VERSION ""

NS_ :

BS_:

BU_: PowertrainControlModule AtmosphericSensor SafetyRestraintSystem2 Aftertreatment_2_GasOutlet Aftertreatment_2_GasIntake DieselParticulateFilterControl Turbocharger SafetyRestraintSystem1 CabDisplay2 Aftertreatment_1_GasOutlet Aftertreatment_1_GasIntake OnBoardDataLogger OffBoardDiagnosticTool2 OffBoardDiagnosticTool1 FileServer ParkingBrakeController SeatController2 FanDriveController SteeringColumnUnit CommunicationUnitRadio CommunicationUnitSatellite CommunicationUnitCellular PropulsionBatteryCharger ChassisController2 ChassisController1 EngineValveControl AuxiliaryHeater2 AuxiliaryHeater1 ClutchUnit RampControl InformationSystem1 SuspensionSystemController2 OilSensor VehicleDynamicStability ExhaustEmissionController TransmissionDisplay2 TransmissionDisplay1 ClimateControl2 WaterPumpController RearAxleSteeringController LightingOperatorControl SeatController1 IgnitionController2 IgnitionController1 TirePressureController CabController2 CabController1 PneumaticSystemController SuspensionSystemController1 HydraulicPumpController EnduranceBrakingSystem RetarderExhaustEngine2 OnBoardDiagnosticUnit HeadwayController RetarderExhaustEngine1 CabDisplay1 ManagementComputer VirtualTerminal OffVehicleGateway PowerTakeOffFront HitchControl AuxiliaryValveControl BodyController TractorTrailerBridge1 StarterSystem ElectricalSystem VehicleSecurity VehicleNavigation AerodynamicControl ElectricalChargingSystem ClimateControl1 TripRecorder InstrumentCluster SuspensionDriveAxle2 SuspensionDriveAxle1 SuspensionSteerAxle SteeringController FuelSystem CruiseControl RetarderDriveline RetarderEngine BrakesDriveAxle2 BrakesDriveAxle1 BrakesSystemController BrakesSteerAxle AxleDrive2 AxleDrive1 AxleSteering PowerTakeOff ShiftConsoleSecondary ShiftConsolePrimary Transmission2 Transmission1 Engine2 Engine1

BO_ 2566642942 DC4: 8 Vector__XXX
 SG_ EnableStatusOfDoor30 : 58|2@1+ (1,0) [0|3] "" Vector__XXX
 SG_ OpenStatusOfDoor30 : 56|2@1+ (1,0) [0|3] "" Vector__XXX
 SG_ LockStatusOfDoor30 : 54|2@1+ (1,0) [0|3] "" Vector__XXX
 SG_ EnableStatusOfDoor29 : 52|2@1+ (1,0) [0|3] "" Vector__XXX
 SG_ OpenStatusOfDoor29 : 50|2@1+ (1,0) [0|3] "" Vector__XXX
 SG_ LockStatusOfDoor29 : 48|2@1+ (1,0) [0|3] "" Vector__XXX
 SG_ EnableStatusOfDoor28 : 46|2@1+ (1,0) [0|3] "" Vector__XXX
 SG_ OpenStatusOfDoor28 : 44|2@1+ (1,0) [0|3] "" Vector__XXX
 SG_ LockStatusOfDoor28 : 42|2@1+ (1,0) [0|3] "" Vector__XXX
 SG_ EnableStatusOfDoor27 : 40|2@1+ (1,0) [0|3] "" Vector__XXX
 SG_ OpenStatusOfDoor27 : 38|2@1+ (1,0) [0|3] "" Vector__XXX
 SG_ LockStatusOfDoor27 : 36|2@1+ (1,0) [0|3] "" Vector__XXX
 SG_ EnableStatusOfDoor26 : 34|2@1+ (1,0) [0|3] "" Vector__XXX
 SG_ OpenStatusOfDoor26 : 32|2@1+ (1,0) [0|3] "" Vector__XXX
 SG_ LockStatusOfDoor26 : 30|2@1+ (1,0) [0|3] "" Vector__XXX
 SG_ EnableStatusOfDoor25 : 28|2@1+ (1,0) [0|3] "" Vector__XXX
 SG_ OpenStatusOfDoor25 : 26|2@1+ (1,0) [0|3] "" Vector__XXX
 SG_ LockStatusOfDoor25 : 24|2@1+ (1,0) [0|3] "" Vector__XXX
 SG_ EnableStatusOfDoor24 : 22|2@1+ (1,0) [0|3] "" Vector__XXX
 SG_ OpenStatusOfDoor24 : 20|2@1+ (1,0) [0|3] "" Vector__XXX
 SG_ LockStatusOfDoor24 : 18|2@1+ (1,0) [0|3] "" Vector__XXX
 SG_ EnableStatusOfDoor23 : 16|2@1+ (1,0) [0|3] "" Vector__XXX
 SG_ OpenStatusOfDoor23 : 14|2@1+ (1,0) [0|3] "" Vector__XXX
 SG_ LockStatusOfDoor23 : 12|2@1+ (1,0) [0|3] "" Vector__XXX
 SG_ EnableStatusOfDoor22 : 10|2@1+ (1,0) [0|3] "" Vector__XXX
 SG_ OpenStatusOfDoor22 : 8|2@1+ (1,0) [0|3] "" Vector__XXX
 SG_ LockStatusOfDoor22 : 6|2@1+ (1,0) [0|3] "" Vector__XXX
 SG_ EnableStatusOfDoor21 : 4|2@1+ (1,0) [0|3] "" Vector__XXX
 SG_ OpenStatusOfDoor21 : 2|2@1+ (1,0) [0|3] "" Vector__XXX
 SG_ LockStatusOfDoor21 : 0|2@1+ (1,0) [0|3] "" Vector__XXX

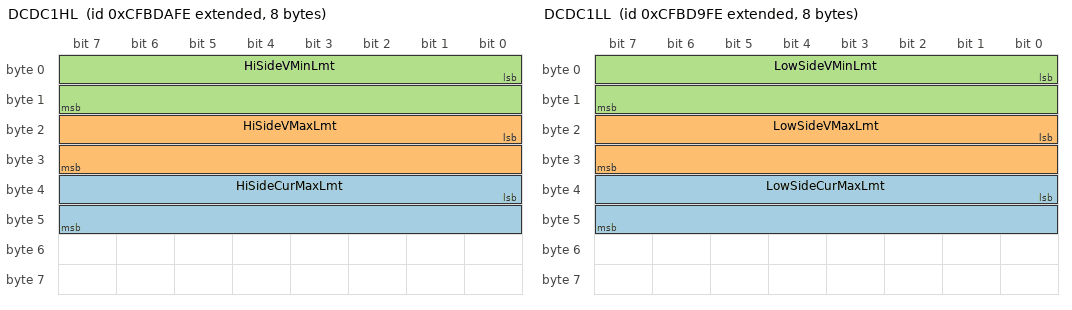
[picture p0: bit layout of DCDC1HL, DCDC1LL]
BO_ 2365315838 DCDC1HL: 8 Vector__XXX
 SG_ HiSideCurMaxLmt : 32|16@1+ (0.05,0) [0|3212.75] "A" Vector__XXX
 SG_ HiSideVMaxLmt : 16|16@1+ (0.05,0) [0|3212.75] "V" Vector__XXX
 SG_ HiSideVMinLmt : 0|16@1+ (0.05,0) [0|3212.75] "V" Vector__XXX

BO_ 2365315582 DCDC1LL: 8 Vector__XXX
 SG_ LowSideCurMaxLmt : 32|16@1+ (0.05,0) [0|3212.75] "A" Vector__XXX
 SG_ LowSideVMaxLmt : 16|16@1+ (0.01,0) [0|642.55] "V" Vector__XXX
 SG_ LowSideVMinLmt : 0|16@1+ (0.01,0) [0|642.55] "V" Vector__XXX

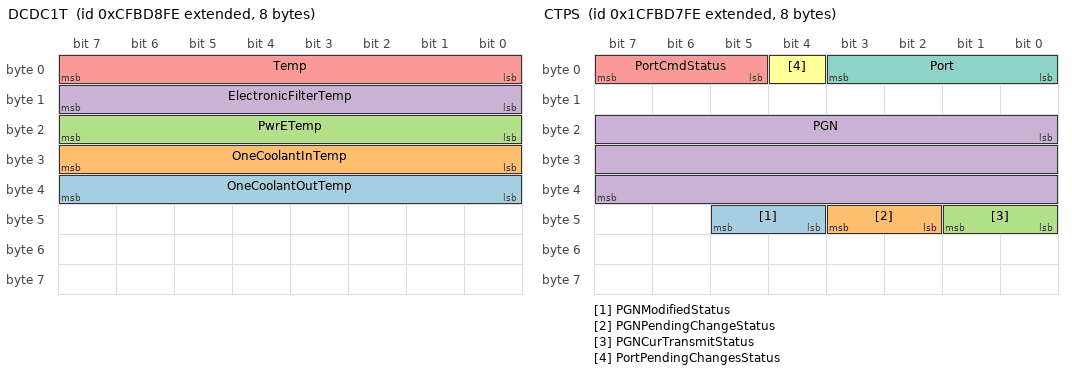
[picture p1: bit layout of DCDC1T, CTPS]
BO_ 2365315326 DCDC1T: 8 Vector__XXX
 SG_ OneCoolantOutTemp : 32|8@1+ (1,-40) [-40|210] "°C" Vector__XXX
 SG_ OneCoolantInTemp : 24|8@1+ (1,-40) [-40|210] "°C" Vector__XXX
 SG_ PwrETemp : 16|8@1+ (1,-40) [-40|210] "°C" Vector__XXX
 SG_ ElectronicFilterTemp : 8|8@1+ (1,-40) [-40|210] "°C" Vector__XXX
 SG_ Temp : 0|8@1+ (1,-40) [-40|210] "°C" Vector__XXX

BO_ 2633750526 CTPS: 8 Vector__XXX
 SG_ PGNModifiedStatus : 44|2@1+ (1,0) [0|3] "" Vector__XXX
 SG_ PGNPendingChangeStatus : 42|2@1+ (1,0) [0|3] "" Vector__XXX
 SG_ PGNCurTransmitStatus : 40|2@1+ (1,0) [0|3] "" Vector__XXX
 SG_ PGN : 16|24@1+ (1,0) [0|16777215] "" Vector__XXX
 SG_ PortCmdStatus : 5|3@1+ (1,0) [0|7] "" Vector__XXX
 SG_ PortPendingChangesStatus : 4|1@1+ (1,0) [0|1] "" Vector__XXX
 SG_ Port : 0|4@1+ (1,0) [0|15] "" Vector__XXX

BO_ 2566641406 EEC21: 8 Vector__XXX
 SG_ ExhManifoldPress2 : 16|16@1+ (0.1,0) [0|6425.5] "kPa" Vector__XXX
 SG_ ExhManifoldPress1 : 0|16@1+ (0.1,0) [0|6425.5] "kPa" Vector__XXX

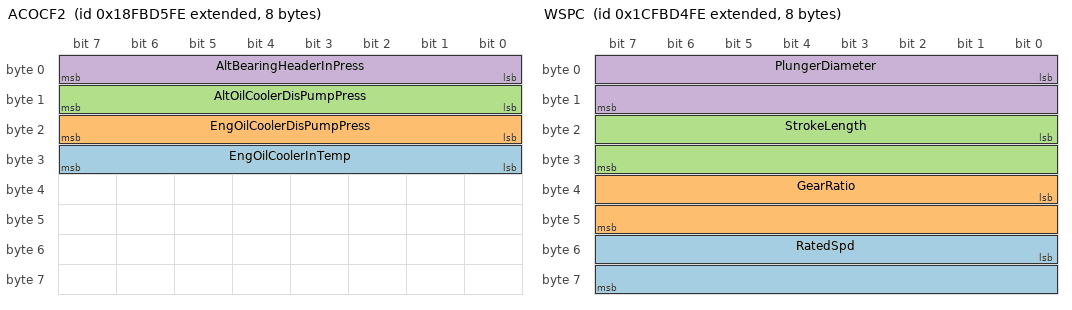
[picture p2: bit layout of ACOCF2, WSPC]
BO_ 2566641150 ACOCF2: 8 Vector__XXX
 SG_ EngOilCoolerInTemp : 24|8@1+ (1,-40) [-40|210] "°C" Vector__XXX
 SG_ EngOilCoolerDisPumpPress : 16|8@1+ (2,0) [0|500] "kPa" Vector__XXX
 SG_ AltOilCoolerDisPumpPress : 8|8@1+ (2,0) [0|500] "kPa" Vector__XXX
 SG_ AltBearingHeaderInPress : 0|8@1+ (2,0) [0|500] "kPa" Vector__XXX

BO_ 2633749758 WSPC: 8 Vector__XXX
 SG_ RatedSpd : 48|16@1+ (0.125,0) [0|8031.875] "rpm" Vector__XXX
 SG_ GearRatio : 32|16@1+ (0.001,0) [0|64.255] "" Vector__XXX
 SG_ StrokeLength : 16|16@1+ (1,0) [0|64255] "mm" Vector__XXX
 SG_ PlungerDiameter : 0|16@1+ (1,0) [0|64255] "mm" Vector__XXX

BO_ 2633749502 WSPT: 16 Vector__XXX
 SG_ CycleCount : 96|32@1+ (1,0) [0|4211081215] "" Vector__XXX
 SG_ WorkingHours : 64|32@1+ (1,0) [0|4211081215] "s" Vector__XXX
 SG_ PwrEndWorkingHours : 32|32@1+ (1,0) [0|4211081215] "s" Vector__XXX
 SG_ FluidEndWorkingHours : 0|32@1+ (1,0) [0|4211081215] "s" Vector__XXX

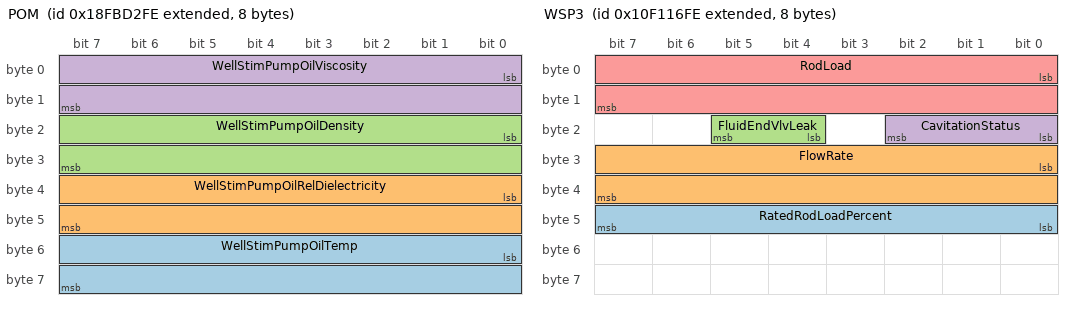
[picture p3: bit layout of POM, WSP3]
BO_ 2566640382 POM: 8 Vector__XXX
 SG_ WellStimPumpOilTemp : 48|16@1+ (0.03125,-273) [-273|1734.96875] "°C" Vector__XXX
 SG_ WellStimPumpOilRelDielectricity : 32|16@1+ (0.0001220703125,0) [0|7.8436279296875] "" Vector__XXX
 SG_ WellStimPumpOilDensity : 16|16@1+ (3.052E-005,0) [0|1.9610626] "g/cc" Vector__XXX
 SG_ WellStimPumpOilViscosity : 0|16@1+ (0.015625,0) [0|1003.984375] "cP" Vector__XXX

BO_ 2431719166 WSP3: 8 Vector__XXX
 SG_ RatedRodLoadPercent : 40|8@1+ (0.5,0) [0|125] "%" Vector__XXX
 SG_ FlowRate : 24|16@1+ (0.5,0) [0|32127.5] "l/min" Vector__XXX
 SG_ FluidEndVlvLeak : 20|2@1+ (1,0) [0|3] "" Vector__XXX
 SG_ CavitationStatus : 16|3@1+ (1,0) [0|7] "" Vector__XXX
 SG_ RodLoad : 0|16@1+ (5,0) [0|321275] "kN" Vector__XXX

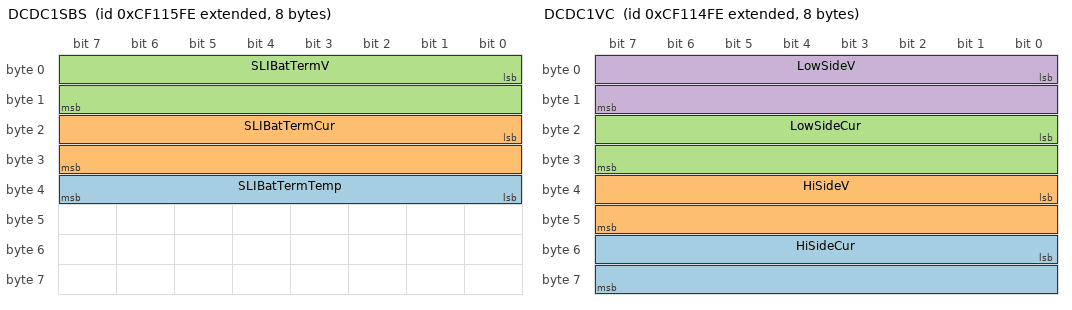
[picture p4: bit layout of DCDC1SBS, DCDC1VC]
BO_ 2364610046 DCDC1SBS: 8 Vector__XXX
 SG_ SLIBatTermTemp : 32|8@1+ (1,-40) [-40|210] "°C" Vector__XXX
 SG_ SLIBatTermCur : 16|16@1+ (0.1,-3212.7) [-3212.7|3212.8] "A" Vector__XXX
 SG_ SLIBatTermV : 0|16@1+ (0.01,0) [0|642.55] "V" Vector__XXX

BO_ 2364609790 DCDC1VC: 8 Vector__XXX
 SG_ HiSideCur : 48|16@1+ (0.1,-3212.7) [-3212.7|3212.8] "A" Vector__XXX
 SG_ HiSideV : 32|16@1+ (0.05,0) [0|3212.75] "V" Vector__XXX
 SG_ LowSideCur : 16|16@1+ (0.1,-3212.7) [-3212.7|3212.8] "A" Vector__XXX
 SG_ LowSideV : 0|16@1+ (0.01,0) [0|642.55] "V" Vector__XXX

BO_ 2364609534 DCDC1OS: 8 Vector__XXX
 SG_ DCDC1OperatingStatusCRC : 56|8@1+ (1,0) [0|255] "" Vector__XXX
 SG_ DCDC1OperatingStatusCounter : 52|4@1+ (1,0) [0|15] "" Vector__XXX
 SG_ PLDueToUndefinedReason : 32|2@1+ (1,0) [0|3] "" Vector__XXX
 SG_ PLDueToSLIBatTermTemp : 30|2@1+ (1,0) [0|3] "" Vector__XXX
 SG_ PLDueToSLIBatTermCur : 28|2@1+ (1,0) [0|3] "" Vector__XXX
 SG_ PLDueToSLIBatTermV : 26|2@1+ (1,0) [0|3] "" Vector__XXX
 SG_ PLDueToPwrETemp : 24|2@1+ (1,0) [0|3] "" Vector__XXX
 SG_ PLDueToElectronicFilterTemp : 22|2@1+ (1,0) [0|3] "" Vector__XXX
 SG_ PLDueToCtrlTemp : 20|2@1+ (1,0) [0|3] "" Vector__XXX
 SG_ PLDueToLowSideVMax : 18|2@1+ (1,0) [0|3] "" Vector__XXX
 SG_ PLDueToLowSideVMin : 16|2@1+ (1,0) [0|3] "" Vector__XXX
 SG_ PLDueToHiSideVMax : 14|2@1+ (1,0) [0|3] "" Vector__XXX
 SG_ PLDueToHiSideVMin : 12|2@1+ (1,0) [0|3] "" Vector__XXX
 SG_ PLDueToLowSideCur : 10|2@1+ (1,0) [0|3] "" Vector__XXX
 SG_ PLDueToHiSideCur : 8|2@1+ (1,0) [0|3] "" Vector__XXX
 SG_ LoadshedReq : 6|2@1+ (1,0) [0|3] "" Vector__XXX
 SG_ HVILStatus : 4|2@1+ (1,0) [0|3] "" Vector__XXX
 SG_ OperationalStatus : 0|4@1+ (1,0) [0|15] "" Vector__XXX

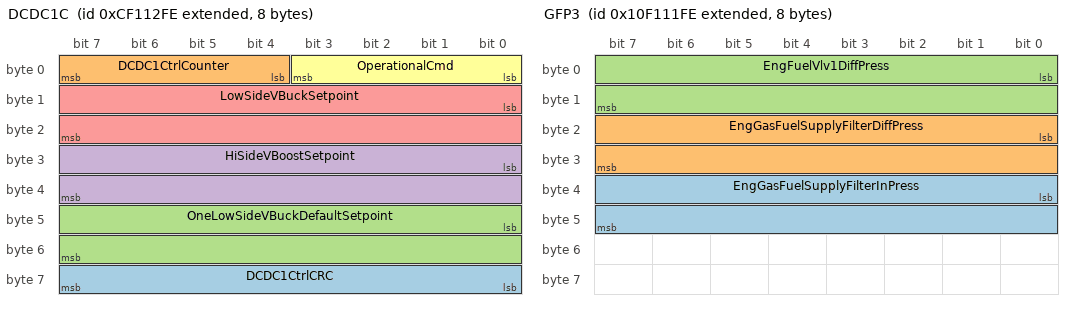
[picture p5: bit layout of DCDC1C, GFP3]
BO_ 2364609278 DCDC1C: 8 Vector__XXX
 SG_ DCDC1CtrlCRC : 56|8@1+ (1,0) [0|255] "" Vector__XXX
 SG_ DCDC1CtrlCounter : 4|4@1+ (1,0) [0|15] "" Vector__XXX
 SG_ OneLowSideVBuckDefaultSetpoint : 40|16@1+ (0.01,0) [0|642.55] "V" Vector__XXX
 SG_ HiSideVBoostSetpoint : 24|16@1+ (0.05,0) [0|3212.75] "V" Vector__XXX
 SG_ LowSideVBuckSetpoint : 8|16@1+ (0.01,0) [0|642.55] "V" Vector__XXX
 SG_ OperationalCmd : 0|4@1+ (1,0) [0|15] "" Vector__XXX

BO_ 2431717886 GFP3: 8 Vector__XXX
 SG_ EngGasFuelSupplyFilterInPress : 32|16@1+ (0.5,0) [0|32127.5] "kPa" Vector__XXX
 SG_ EngGasFuelSupplyFilterDiffPress : 16|16@1+ (0.0078125,-100) [-100|401.9921875] "kPa" Vector__XXX
 SG_ EngFuelVlv1DiffPress : 0|16@1+ (0.0078125,-100) [-100|401.9921875] "kPa" Vector__XXX

BO_ 2297499902 B2: 8 Vector__XXX
 SG_ BrkPedalSw2 : 16|2@1+ (1,0) [0|3] "" Vector__XXX
 SG_ DemandedBrkAppPress : 0|16@1+ (0.1,0) [0|6425.5] "kPa" Vector__XXX

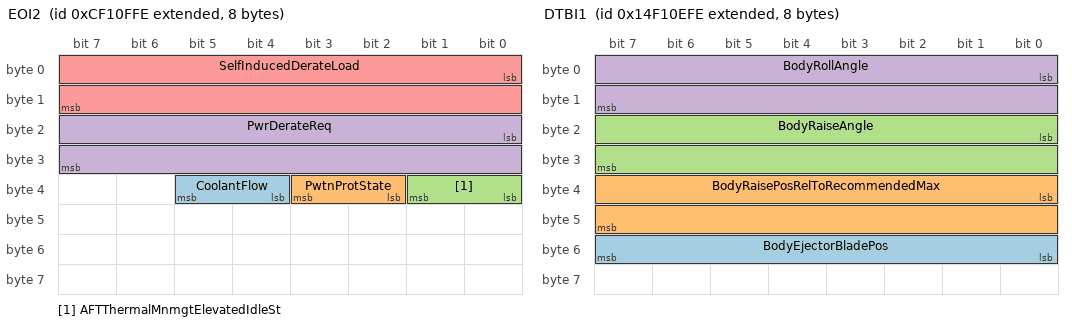
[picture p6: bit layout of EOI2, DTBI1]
BO_ 2364608510 EOI2: 8 Vector__XXX
 SG_ CoolantFlow : 36|2@1+ (1,0) [0|3] "" Vector__XXX
 SG_ PwtnProtState : 34|2@1+ (1,0) [0|3] "" Vector__XXX
 SG_ AFTThermalMnmgtElevatedIdleSt : 32|2@1+ (1,0) [0|3] "" Vector__XXX
 SG_ PwrDerateReq : 16|16@1+ (0.5,0) [0|32127.5] "kW" Vector__XXX
 SG_ SelfInducedDerateLoad : 0|16@1+ (0.5,0) [0|32127.5] "kW" Vector__XXX

BO_ 2498825982 DTBI1: 8 Vector__XXX
 SG_ BodyEjectorBladePos : 48|8@1+ (0.4,0) [0|100] "%" Vector__XXX
 SG_ BodyRaisePosRelToRecommendedMax : 32|16@1+ (0.005,-150) [-150|171.275] "%" Vector__XXX
 SG_ BodyRaiseAngle : 16|16@1+ (0.0078125,-200) [-200|301.9921875] "deg" Vector__XXX
 SG_ BodyRollAngle : 0|16@1+ (0.0078125,-200) [-200|301.9921875] "deg" Vector__XXX

BO_ 2565934590 GFI6: 8 Vector__XXX
 SG_ EngFuelVlv2DiffPress : 0|16@1+ (0.1,0) [0|6425.5] "kPa" Vector__XXX

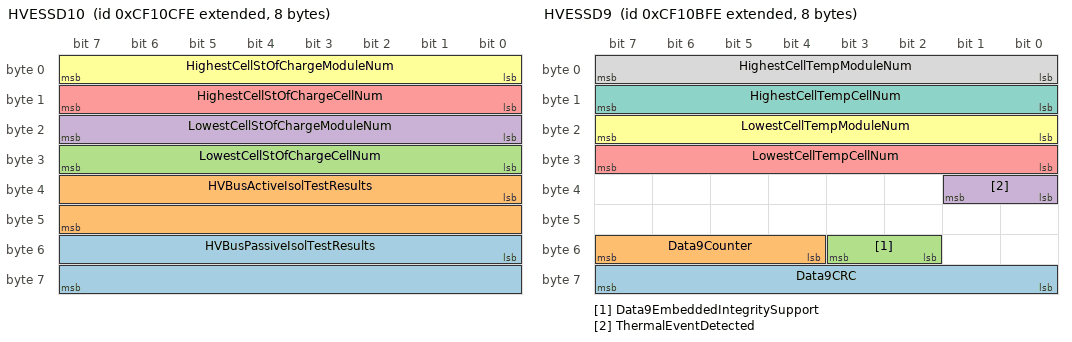
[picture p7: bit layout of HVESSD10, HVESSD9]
BO_ 2364607742 HVESSD10: 8 Vector__XXX
 SG_ HVBusPassiveIsolTestResults : 48|16@1+ (0.1,0) [0|6425.5] "Ohm/V" Vector__XXX
 SG_ HVBusActiveIsolTestResults : 32|16@1+ (0.1,0) [0|6425.5] "Ohm/V" Vector__XXX
 SG_ LowestCellStOfChargeCellNum : 24|8@1+ (1,0) [0|250] "" Vector__XXX
 SG_ LowestCellStOfChargeModuleNum : 16|8@1+ (1,0) [0|250] "" Vector__XXX
 SG_ HighestCellStOfChargeCellNum : 8|8@1+ (1,0) [0|250] "" Vector__XXX
 SG_ HighestCellStOfChargeModuleNum : 0|8@1+ (1,0) [0|250] "" Vector__XXX

BO_ 2364607486 HVESSD9: 8 Vector__XXX
 SG_ Data9CRC : 56|8@1+ (1,0) [0|255] "" Vector__XXX
 SG_ Data9Counter : 52|4@1+ (1,0) [0|15] "" Vector__XXX
 SG_ Data9EmbeddedIntegritySupport : 50|2@1+ (1,0) [0|3] "" Vector__XXX
 SG_ ThermalEventDetected : 32|2@1+ (1,0) [0|3] "" Vector__XXX
 SG_ LowestCellTempCellNum : 24|8@1+ (1,0) [0|250] "" Vector__XXX
 SG_ LowestCellTempModuleNum : 16|8@1+ (1,0) [0|250] "" Vector__XXX
 SG_ HighestCellTempCellNum : 8|8@1+ (1,0) [0|250] "" Vector__XXX
 SG_ HighestCellTempModuleNum : 0|8@1+ (1,0) [0|250] "" Vector__XXX

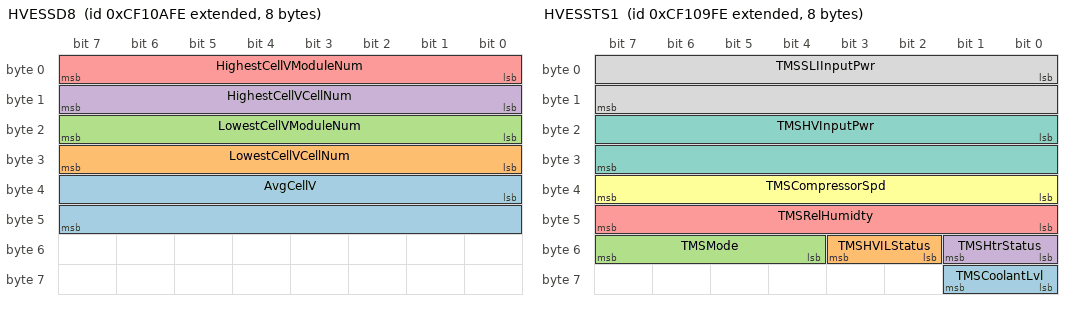
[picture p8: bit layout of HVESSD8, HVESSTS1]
BO_ 2364607230 HVESSD8: 8 Vector__XXX
 SG_ AvgCellV : 32|16@1+ (0.001,0) [0|64.255] "V" Vector__XXX
 SG_ LowestCellVCellNum : 24|8@1+ (1,0) [0|250] "" Vector__XXX
 SG_ LowestCellVModuleNum : 16|8@1+ (1,0) [0|250] "" Vector__XXX
 SG_ HighestCellVCellNum : 8|8@1+ (1,0) [0|250] "" Vector__XXX
 SG_ HighestCellVModuleNum : 0|8@1+ (1,0) [0|250] "" Vector__XXX

BO_ 2364606974 HVESSTS1: 8 Vector__XXX
 SG_ TMSCoolantLvl : 56|2@1+ (1,0) [0|3] "" Vector__XXX
 SG_ TMSHVILStatus : 50|2@1+ (1,0) [0|3] "" Vector__XXX
 SG_ TMSMode : 52|4@1+ (1,0) [0|15] "" Vector__XXX
 SG_ TMSHtrStatus : 48|2@1+ (1,0) [0|3] "" Vector__XXX
 SG_ TMSRelHumidty : 40|8@1+ (0.4,0) [0|100] "%" Vector__XXX
 SG_ TMSCompressorSpd : 32|8@1+ (32,0) [0|8000] "rpm" Vector__XXX
 SG_ TMSHVInputPwr : 16|16@1+ (0.5,0) [0|32127.5] "W" Vector__XXX
 SG_ TMSSLIInputPwr : 0|16@1+ (0.5,0) [0|32127.5] "W" Vector__XXX

BO_ 2364606718 HVESSMS1: 8 Vector__XXX
 SG_ Module32OperationalStatus : 62|2@1+ (1,0) [0|3] "" Vector__XXX
 SG_ Module31OperationalStatus : 60|2@1+ (1,0) [0|3] "" Vector__XXX
 SG_ Module30OperationalStatus : 58|2@1+ (1,0) [0|3] "" Vector__XXX
 SG_ Module29OperationalStatus : 56|2@1+ (1,0) [0|3] "" Vector__XXX
 SG_ Module28OperationalStatus : 54|2@1+ (1,0) [0|3] "" Vector__XXX
 SG_ Module27OperationalStatus : 52|2@1+ (1,0) [0|3] "" Vector__XXX
 SG_ Module26OperationalStatus : 50|2@1+ (1,0) [0|3] "" Vector__XXX
 SG_ Module25OperationalStatus : 48|2@1+ (1,0) [0|3] "" Vector__XXX
 SG_ Module24OperationalStatus : 46|2@1+ (1,0) [0|3] "" Vector__XXX
 SG_ Module23OperationalStatus : 44|2@1+ (1,0) [0|3] "" Vector__XXX
 SG_ Module22OperationalStatus : 42|2@1+ (1,0) [0|3] "" Vector__XXX
 SG_ Module21OperationalStatus : 40|2@1+ (1,0) [0|3] "" Vector__XXX
 SG_ Module20OperationalStatus : 38|2@1+ (1,0) [0|3] "" Vector__XXX
 SG_ Module19OperationalStatus : 36|2@1+ (1,0) [0|3] "" Vector__XXX
 SG_ Module18OperationalStatus : 34|2@1+ (1,0) [0|3] "" Vector__XXX
 SG_ Module17OperationalStatus : 32|2@1+ (1,0) [0|3] "" Vector__XXX
 SG_ Module16OperationalStatus : 30|2@1+ (1,0) [0|3] "" Vector__XXX
 SG_ Module15OperationalStatus : 28|2@1+ (1,0) [0|3] "" Vector__XXX
 SG_ Module14OperationalStatus : 26|2@1+ (1,0) [0|3] "" Vector__XXX
 SG_ Module13OperationalStatus : 24|2@1+ (1,0) [0|3] "" Vector__XXX
 SG_ Module12OperationalStatus : 22|2@1+ (1,0) [0|3] "" Vector__XXX
 SG_ Module11OperationalStatus : 20|2@1+ (1,0) [0|3] "" Vector__XXX
 SG_ Module10OperationalStatus : 18|2@1+ (1,0) [0|3] "" Vector__XXX
 SG_ Module9OperationalStatus : 16|2@1+ (1,0) [0|3] "" Vector__XXX
 SG_ Module8OperationalStatus : 14|2@1+ (1,0) [0|3] "" Vector__XXX
 SG_ Module7OperationalStatus : 12|2@1+ (1,0) [0|3] "" Vector__XXX
 SG_ Module6OperationalStatus : 10|2@1+ (1,0) [0|3] "" Vector__XXX
 SG_ Module5OperationalStatus : 8|2@1+ (1,0) [0|3] "" Vector__XXX
 SG_ Module4OperationalStatus : 6|2@1+ (1,0) [0|3] "" Vector__XXX
 SG_ Module3OperationalStatus : 4|2@1+ (1,0) [0|3] "" Vector__XXX
 SG_ Module2OperationalStatus : 2|2@1+ (1,0) [0|3] "" Vector__XXX
 SG_ Module1OperationalStatus : 0|2@1+ (1,0) [0|3] "" Vector__XXX

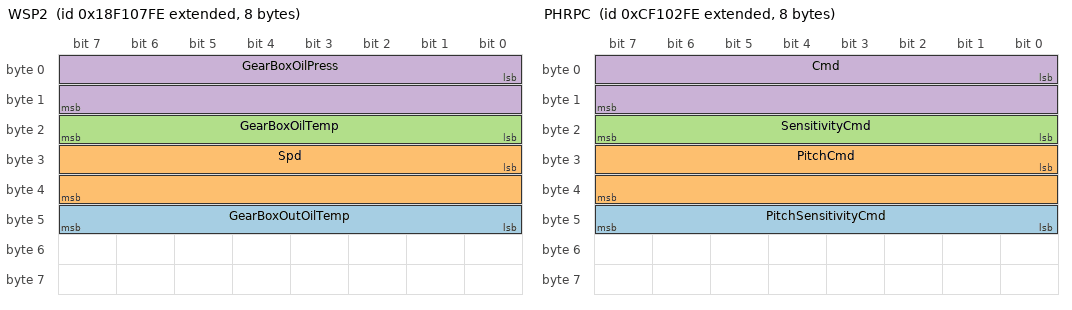
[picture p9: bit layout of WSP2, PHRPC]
BO_ 2565933054 WSP2: 8 Vector__XXX
 SG_ GearBoxOutOilTemp : 40|8@1+ (1,-40) [-40|210] "°C" Vector__XXX
 SG_ Spd : 24|16@1+ (0.125,0) [0|8031.875] "rpm" Vector__XXX
 SG_ GearBoxOilTemp : 16|8@1+ (1,-40) [-40|210] "°C" Vector__XXX
 SG_ GearBoxOilPress : 0|16@1+ (0.1,0) [0|6425.5] "kPa" Vector__XXX

BO_ 2565932798 WSP1: 8 Vector__XXX
 SG_ DisPress : 16|16@1+ (5,0) [0|321275] "kPa" Vector__XXX
 SG_ SuctionPress : 0|16@1+ (0.1,-3212.7) [-3212.7|3212.8] "kPa" Vector__XXX

BO_ 2364605950 HPD: 8 Vector__XXX
 SG_ MechMovementAngle : 16|16@1+ (0.0078125,0) [0|359.99] "deg" Vector__XXX
 SG_ LinePress : 0|16@1+ (1,0) [0|64255] "kPa" Vector__XXX

BO_ 2565932286 ESSI2: 8 Vector__XXX
 SG_ Vour : 0|16@1+ (0.5,0) [0|32127.5] "rpm" Vector__XXX

BO_ 2364605438 GTRACE: 8 Vector__XXX
 SG_ KVArHoursExport : 32|32@1+ (1,0) [0|4211081215] "kVArh" Vector__XXX
 SG_ KWHoursExport : 0|32@1+ (1,0) [0|4211081215] "kWh" Vector__XXX

BO_ 2364605182 PHRPC: 8 Vector__XXX
 SG_ PitchSensitivityCmd : 40|8@1+ (0.4,0) [0|100] "%" Vector__XXX
 SG_ PitchCmd : 24|16@1+ (0.002,-64) [-64|64.51] "deg" Vector__XXX
 SG_ SensitivityCmd : 16|8@1+ (0.4,0) [0|100] "%" Vector__XXX
 SG_ Cmd : 0|16@1+ (0.002,-64) [-64|64.51] "deg" Vector__XXX

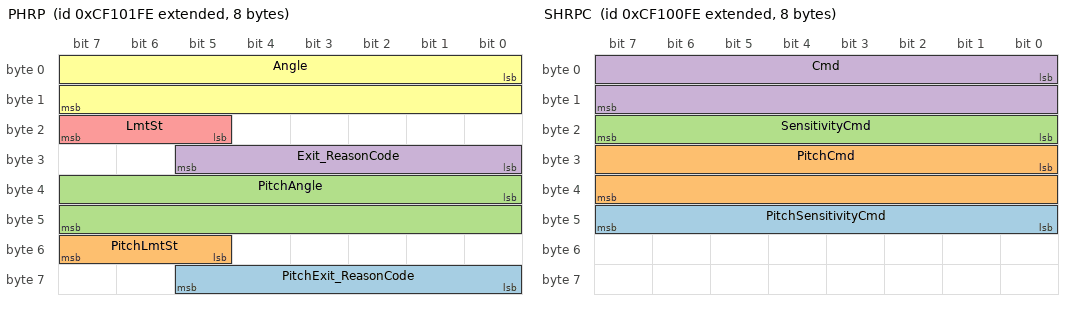
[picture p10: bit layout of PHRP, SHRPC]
BO_ 2364604926 PHRP: 8 Vector__XXX
 SG_ PitchExit_ReasonCode : 56|6@1+ (1,0) [0|63] "" Vector__XXX
 SG_ PitchLmtSt : 53|3@1+ (1,0) [0|7] "" Vector__XXX
 SG_ PitchAngle : 32|16@1+ (0.002,-64) [-64|64.51] "deg" Vector__XXX
 SG_ Exit_ReasonCode : 24|6@1+ (1,0) [0|63] "" Vector__XXX
 SG_ LmtSt : 21|3@1+ (1,0) [0|7] "" Vector__XXX
 SG_ Angle : 0|16@1+ (0.002,-64) [-64|64.51] "deg" Vector__XXX

BO_ 2364604670 SHRPC: 8 Vector__XXX
 SG_ PitchSensitivityCmd : 40|8@1+ (0.4,0) [0|100] "%" Vector__XXX
 SG_ PitchCmd : 24|16@1+ (0.002,-64) [-64|64.51] "deg" Vector__XXX
 SG_ SensitivityCmd : 16|8@1+ (0.4,0) [0|100] "%" Vector__XXX
 SG_ Cmd : 0|16@1+ (0.002,-64) [-64|64.51] "deg" Vector__XXX

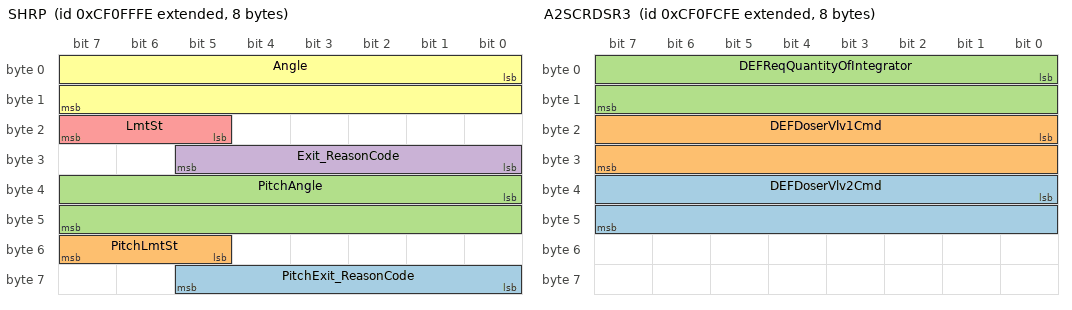
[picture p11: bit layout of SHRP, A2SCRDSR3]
BO_ 2364604414 SHRP: 8 Vector__XXX
 SG_ PitchExit_ReasonCode : 56|6@1+ (1,0) [0|63] "" Vector__XXX
 SG_ PitchLmtSt : 53|3@1+ (1,0) [0|7] "" Vector__XXX
 SG_ PitchAngle : 32|16@1+ (0.002,-64) [-64|64.51] "deg" Vector__XXX
 SG_ Exit_ReasonCode : 24|6@1+ (1,0) [0|63] "" Vector__XXX
 SG_ LmtSt : 21|3@1+ (1,0) [0|7] "" Vector__XXX
 SG_ Angle : 0|16@1+ (0.002,-64) [-64|64.51] "deg" Vector__XXX

BO_ 2364604158 A2SCRDSI4: 8 Vector__XXX
 SG_ DEFActualQuantityOfIntegrator : 0|16@1+ (0.001,0) [0|64.255] "g" Vector__XXX

BO_ 2364603902 A1SCRDSI4: 8 Vector__XXX
 SG_ DEFActualQuantityOfIntegrator : 0|16@1+ (0.001,0) [0|64.255] "g" Vector__XXX

BO_ 2364603646 A2SCRDSR3: 8 Vector__XXX
 SG_ DEFDoserVlv2Cmd : 32|16@1+ (0.0025,0) [0|160.6375] "%" Vector__XXX
 SG_ DEFDoserVlv1Cmd : 16|16@1+ (0.0025,0) [0|160.6375] "%" Vector__XXX
 SG_ DEFReqQuantityOfIntegrator : 0|16@1+ (0.001,0) [0|64.255] "g" Vector__XXX

BO_ 2364603390 A1SCRDSR3: 8 Vector__XXX
 SG_ DEFDoserVlv2Cmd : 32|16@1+ (0.0025,0) [0|100] "%" Vector__XXX
 SG_ DEFDoserVlv1Cmd : 16|16@1+ (0.0025,0) [0|100] "%" Vector__XXX
 SG_ DEFReqQuantityOfIntegrator : 0|16@1+ (0.001,0) [0|64.255] "g" Vector__XXX

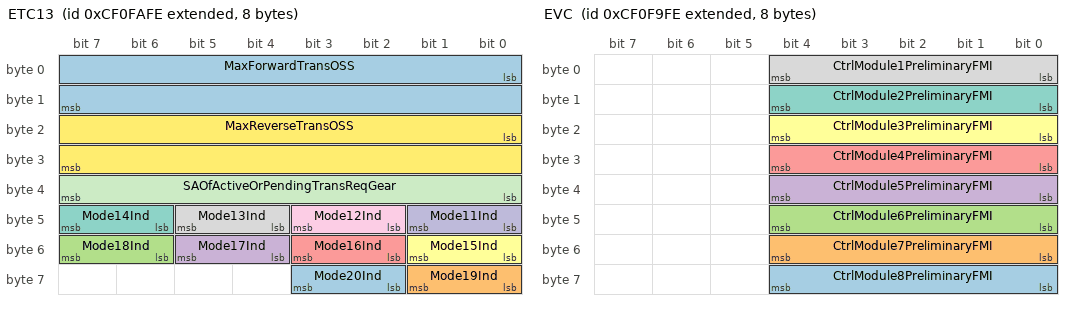
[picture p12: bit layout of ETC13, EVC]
BO_ 2364603134 ETC13: 8 Vector__XXX
 SG_ Mode20Ind : 58|2@1+ (1,0) [0|3] "" Vector__XXX
 SG_ Mode19Ind : 56|2@1+ (1,0) [0|3] "" Vector__XXX
 SG_ Mode18Ind : 54|2@1+ (1,0) [0|3] "" Vector__XXX
 SG_ Mode17Ind : 52|2@1+ (1,0) [0|3] "" Vector__XXX
 SG_ Mode16Ind : 50|2@1+ (1,0) [0|3] "" Vector__XXX
 SG_ Mode15Ind : 48|2@1+ (1,0) [0|3] "" Vector__XXX
 SG_ Mode14Ind : 46|2@1+ (1,0) [0|3] "" Vector__XXX
 SG_ Mode13Ind : 44|2@1+ (1,0) [0|3] "" Vector__XXX
 SG_ Mode12Ind : 42|2@1+ (1,0) [0|3] "" Vector__XXX
 SG_ Mode11Ind : 40|2@1+ (1,0) [0|3] "" Vector__XXX
 SG_ SAOfActiveOrPendingTransReqGear : 32|8@1+ (1,0) [0|253] "" Vector__XXX
 SG_ MaxReverseTransOSS : 16|16@1+ (0.125,0) [0|8031.875] "rpm" Vector__XXX
 SG_ MaxForwardTransOSS : 0|16@1+ (0.125,0) [0|8031.875] "rpm" Vector__XXX

BO_ 2364602878 EVC: 8 Vector__XXX
 SG_ CtrlModule8PreliminaryFMI : 56|5@1+ (1,0) [0|31] "" Vector__XXX
 SG_ CtrlModule7PreliminaryFMI : 48|5@1+ (1,0) [0|31] "" Vector__XXX
 SG_ CtrlModule6PreliminaryFMI : 40|5@1+ (1,0) [0|31] "" Vector__XXX
 SG_ CtrlModule5PreliminaryFMI : 32|5@1+ (1,0) [0|31] "" Vector__XXX
 SG_ CtrlModule4PreliminaryFMI : 24|5@1+ (1,0) [0|31] "" Vector__XXX
 SG_ CtrlModule3PreliminaryFMI : 16|5@1+ (1,0) [0|31] "" Vector__XXX
 SG_ CtrlModule2PreliminaryFMI : 8|5@1+ (1,0) [0|31] "" Vector__XXX
 SG_ CtrlModule1PreliminaryFMI : 0|5@1+ (1,0) [0|31] "" Vector__XXX

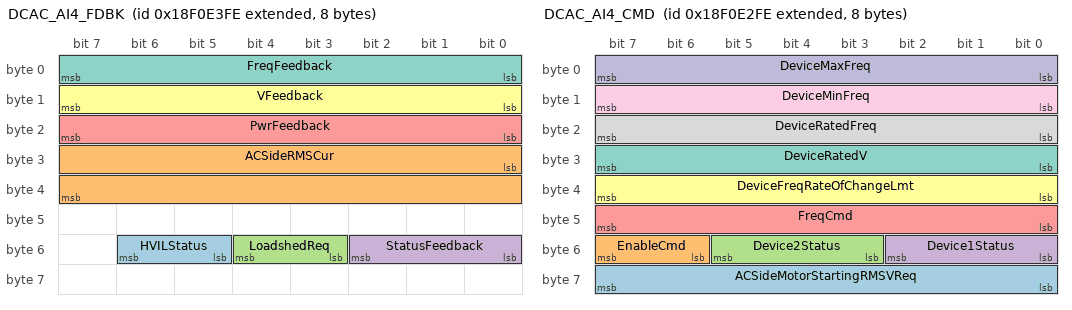
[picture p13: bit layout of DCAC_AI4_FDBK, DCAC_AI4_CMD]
BO_ 2565923838 DCAC_AI4_FDBK: 8 Vector__XXX
 SG_ HVILStatus : 53|2@1+ (1,0) [0|3] "" Vector__XXX
 SG_ ACSideRMSCur : 24|16@1+ (0.03125,0) [0|2007.96875] "A" Vector__XXX
 SG_ LoadshedReq : 51|2@1+ (1,0) [0|3] "" Vector__XXX
 SG_ StatusFeedback : 48|3@1+ (1,0) [0|7] "" Vector__XXX
 SG_ PwrFeedback : 16|8@1+ (0.1,0) [0|25] "kW" Vector__XXX
 SG_ VFeedback : 8|8@1+ (2,0) [0|500] "V" Vector__XXX
 SG_ FreqFeedback : 0|8@1+ (1,0) [0|250] "Hz" Vector__XXX

BO_ 2565923582 DCAC_AI4_CMD: 8 Vector__XXX
 SG_ ACSideMotorStartingRMSVReq : 56|8@1+ (2,0) [0|500] "V" Vector__XXX
 SG_ EnableCmd : 54|2@1+ (1,0) [0|3] "" Vector__XXX
 SG_ Device2Status : 51|3@1+ (1,0) [0|7] "" Vector__XXX
 SG_ Device1Status : 48|3@1+ (1,0) [0|7] "" Vector__XXX
 SG_ FreqCmd : 40|8@1+ (1,0) [0|250] "Hz" Vector__XXX
 SG_ DeviceFreqRateOfChangeLmt : 32|8@1+ (2,0) [0|500] "Hz/s" Vector__XXX
 SG_ DeviceRatedV : 24|8@1+ (2,0) [0|500] "V" Vector__XXX
 SG_ DeviceRatedFreq : 16|8@1+ (1,0) [0|250] "Hz" Vector__XXX
 SG_ DeviceMinFreq : 8|8@1+ (1,0) [0|250] "Hz" Vector__XXX
 SG_ DeviceMaxFreq : 0|8@1+ (1,0) [0|250] "Hz" Vector__XXX

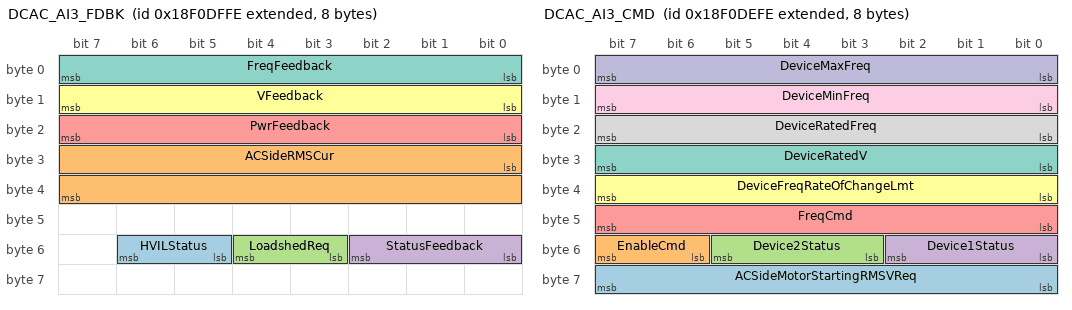
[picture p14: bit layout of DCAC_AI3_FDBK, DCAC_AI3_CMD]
BO_ 2565922814 DCAC_AI3_FDBK: 8 Vector__XXX
 SG_ HVILStatus : 53|2@1+ (1,0) [0|3] "" Vector__XXX
 SG_ ACSideRMSCur : 24|16@1+ (0.03125,0) [0|2007.96875] "A" Vector__XXX
 SG_ LoadshedReq : 51|2@1+ (1,0) [0|3] "" Vector__XXX
 SG_ StatusFeedback : 48|3@1+ (1,0) [0|7] "" Vector__XXX
 SG_ PwrFeedback : 16|8@1+ (0.1,0) [0|25] "kW" Vector__XXX
 SG_ VFeedback : 8|8@1+ (2,0) [0|500] "V" Vector__XXX
 SG_ FreqFeedback : 0|8@1+ (1,0) [0|250] "Hz" Vector__XXX

BO_ 2565922558 DCAC_AI3_CMD: 8 Vector__XXX
 SG_ ACSideMotorStartingRMSVReq : 56|8@1+ (2,0) [0|500] "V" Vector__XXX
 SG_ EnableCmd : 54|2@1+ (1,0) [0|3] "" Vector__XXX
 SG_ Device2Status : 51|3@1+ (1,0) [0|7] "" Vector__XXX
 SG_ Device1Status : 48|3@1+ (1,0) [0|7] "" Vector__XXX
 SG_ FreqCmd : 40|8@1+ (1,0) [0|250] "Hz" Vector__XXX
 SG_ DeviceFreqRateOfChangeLmt : 32|8@1+ (2,0) [0|500] "Hz/s" Vector__XXX
 SG_ DeviceRatedV : 24|8@1+ (2,0) [0|500] "V" Vector__XXX
 SG_ DeviceRatedFreq : 16|8@1+ (1,0) [0|250] "Hz" Vector__XXX
 SG_ DeviceMinFreq : 8|8@1+ (1,0) [0|250] "Hz" Vector__XXX
 SG_ DeviceMaxFreq : 0|8@1+ (1,0) [0|250] "Hz" Vector__XXX

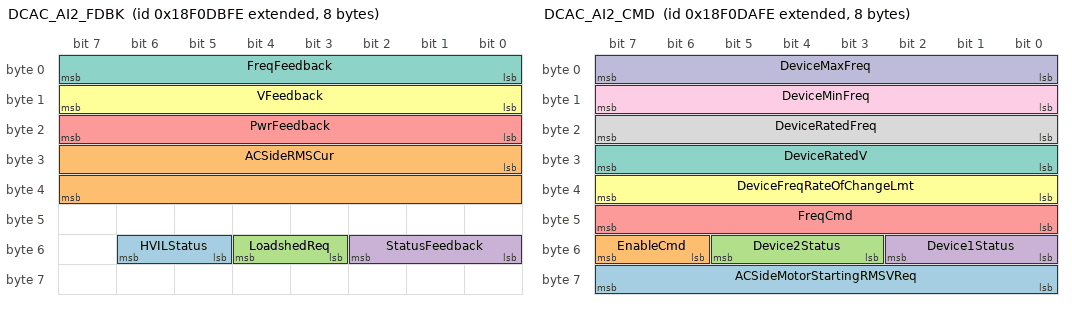
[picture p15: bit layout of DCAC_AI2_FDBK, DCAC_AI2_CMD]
BO_ 2565921790 DCAC_AI2_FDBK: 8 Vector__XXX
 SG_ HVILStatus : 53|2@1+ (1,0) [0|3] "" Vector__XXX
 SG_ ACSideRMSCur : 24|16@1+ (0.03125,0) [0|2007.96875] "A" Vector__XXX
 SG_ LoadshedReq : 51|2@1+ (1,0) [0|3] "" Vector__XXX
 SG_ StatusFeedback : 48|3@1+ (1,0) [0|7] "" Vector__XXX
 SG_ PwrFeedback : 16|8@1+ (0.1,0) [0|25] "kW" Vector__XXX
 SG_ VFeedback : 8|8@1+ (2,0) [0|500] "V" Vector__XXX
 SG_ FreqFeedback : 0|8@1+ (1,0) [0|250] "Hz" Vector__XXX

BO_ 2565921534 DCAC_AI2_CMD: 8 Vector__XXX
 SG_ ACSideMotorStartingRMSVReq : 56|8@1+ (2,0) [0|500] "V" Vector__XXX
 SG_ EnableCmd : 54|2@1+ (1,0) [0|3] "" Vector__XXX
 SG_ Device2Status : 51|3@1+ (1,0) [0|7] "" Vector__XXX
 SG_ Device1Status : 48|3@1+ (1,0) [0|7] "" Vector__XXX
 SG_ FreqCmd : 40|8@1+ (1,0) [0|250] "Hz" Vector__XXX
 SG_ DeviceFreqRateOfChangeLmt : 32|8@1+ (2,0) [0|500] "Hz/s" Vector__XXX
 SG_ DeviceRatedV : 24|8@1+ (2,0) [0|500] "V" Vector__XXX
 SG_ DeviceRatedFreq : 16|8@1+ (1,0) [0|250] "Hz" Vector__XXX
 SG_ DeviceMinFreq : 8|8@1+ (1,0) [0|250] "Hz" Vector__XXX
 SG_ DeviceMaxFreq : 0|8@1+ (1,0) [0|250] "Hz" Vector__XXX

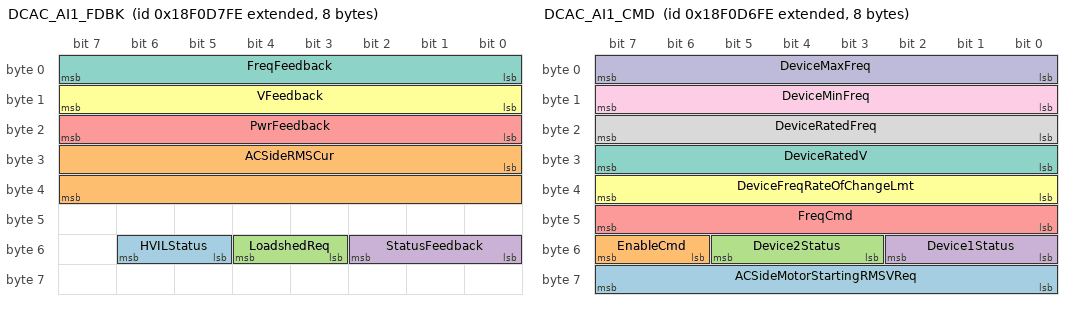
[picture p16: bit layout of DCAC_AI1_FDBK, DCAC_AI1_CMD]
BO_ 2565920766 DCAC_AI1_FDBK: 8 Vector__XXX
 SG_ HVILStatus : 53|2@1+ (1,0) [0|3] "" Vector__XXX
 SG_ ACSideRMSCur : 24|16@1+ (0.03125,0) [0|2007.96875] "A" Vector__XXX
 SG_ LoadshedReq : 51|2@1+ (1,0) [0|3] "" Vector__XXX
 SG_ StatusFeedback : 48|3@1+ (1,0) [0|7] "" Vector__XXX
 SG_ PwrFeedback : 16|8@1+ (0.1,0) [0|25] "kW" Vector__XXX
 SG_ VFeedback : 8|8@1+ (2,0) [0|500] "V" Vector__XXX
 SG_ FreqFeedback : 0|8@1+ (1,0) [0|250] "Hz" Vector__XXX

BO_ 2565920510 DCAC_AI1_CMD: 8 Vector__XXX
 SG_ ACSideMotorStartingRMSVReq : 56|8@1+ (2,0) [0|500] "V" Vector__XXX
 SG_ EnableCmd : 54|2@1+ (1,0) [0|3] "" Vector__XXX
 SG_ Device2Status : 51|3@1+ (1,0) [0|7] "" Vector__XXX
 SG_ Device1Status : 48|3@1+ (1,0) [0|7] "" Vector__XXX
 SG_ FreqCmd : 40|8@1+ (1,0) [0|250] "Hz" Vector__XXX
 SG_ DeviceFreqRateOfChangeLmt : 32|8@1+ (2,0) [0|500] "Hz/s" Vector__XXX
 SG_ DeviceRatedV : 24|8@1+ (2,0) [0|500] "V" Vector__XXX
 SG_ DeviceRatedFreq : 16|8@1+ (1,0) [0|250] "Hz" Vector__XXX
 SG_ DeviceMinFreq : 8|8@1+ (1,0) [0|250] "Hz" Vector__XXX
 SG_ DeviceMaxFreq : 0|8@1+ (1,0) [0|250] "Hz" Vector__XXX

BO_ 2364580094 HVESSD7: 8 Vector__XXX
 SG_ MaxChargeVLmt : 48|16@1+ (0.05,0) [0|3212.75] "V" Vector__XXX
 SG_ ChargeEnergyCapacity : 24|24@1+ (0.001,0) [0|16449.535] "kWh" Vector__XXX
 SG_ DisEnergyCapacity : 0|24@1+ (0.001,0) [0|16449.535] "kWh" Vector__XXX

BO_ 2364577534 HVESSS1: 8 Vector__XXX
 SG_ Status1CRC : 56|8@1+ (1,0) [0|255] "" Vector__XXX
 SG_ NumOfHVESPsReady : 48|8@1+ (1,0) [0|250] "" Vector__XXX
 SG_ Status1Counter : 36|4@1+ (1,0) [0|15] "" Vector__XXX
 SG_ OperationalStatus : 44|4@1+ (1,0) [0|15] "" Vector__XXX
 SG_ HVBusConnectionStatus : 40|4@1+ (1,0) [0|15] "" Vector__XXX
 SG_ InternalChargerStatus : 32|2@1+ (1,0) [0|3] "" Vector__XXX
 SG_ CellBalancingActive : 30|2@1+ (1,0) [0|3] "" Vector__XXX
 SG_ CellBalanceStatus : 28|2@1+ (1,0) [0|3] "" Vector__XXX
 SG_ StOfChargeStatus : 24|4@1+ (1,0) [0|15] "" Vector__XXX
 SG_ InertiaSwStatus : 22|2@1+ (1,0) [0|3] "" Vector__XXX
 SG_ HVILStatus : 20|2@1+ (1,0) [0|3] "" Vector__XXX
 SG_ HVBusPassiveIsolTestStatus : 16|4@1+ (1,0) [0|15] "" Vector__XXX
 SG_ HVBusActiveIsolTestStatus : 12|4@1+ (1,0) [0|15] "" Vector__XXX
 SG_ CenterOfPackContactorSt : 10|2@1+ (1,0) [0|3] "" Vector__XXX
 SG_ HVBusPreChargeRelaySt : 8|2@1+ (1,0) [0|3] "" Vector__XXX
 SG_ HVBusDisconnectForewarning : 4|4@1+ (1,0) [0|15] "" Vector__XXX
 SG_ HVBusContactorSt8092 : 2|2@1+ (1,0) [0|3] "" Vector__XXX
 SG_ HVBusContactorSt : 0|2@1+ (1,0) [0|3] "" Vector__XXX

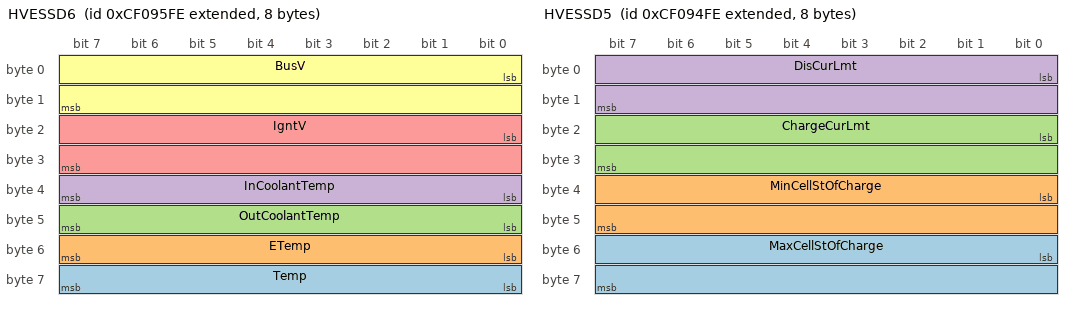
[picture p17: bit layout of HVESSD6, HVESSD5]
BO_ 2364577278 HVESSD6: 8 Vector__XXX
 SG_ Temp : 56|8@1+ (1,-40) [-40|210] "°C" Vector__XXX
 SG_ ETemp : 48|8@1+ (1,-40) [-40|210] "°C" Vector__XXX
 SG_ OutCoolantTemp : 40|8@1+ (1,-40) [-40|210] "°C" Vector__XXX
 SG_ InCoolantTemp : 32|8@1+ (1,-40) [-40|210] "°C" Vector__XXX
 SG_ IgntV : 16|16@1+ (0.01,0) [0|642.55] "V" Vector__XXX
 SG_ BusV : 0|16@1+ (0.05,0) [0|3212.75] "V" Vector__XXX

BO_ 2364577022 HVESSD5: 8 Vector__XXX
 SG_ MaxCellStOfCharge : 48|16@1+ (0.0015625,0) [0|100.3984375] "%" Vector__XXX
 SG_ MinCellStOfCharge : 32|16@1+ (0.0015625,0) [0|100.3984375] "%" Vector__XXX
 SG_ ChargeCurLmt : 16|16@1+ (0.05,-1600) [0|1612.75] "A" Vector__XXX
 SG_ DisCurLmt : 0|16@1+ (0.05,-1600) [-1600|0] "A" Vector__XXX

BO_ 2364576766 HVESSD4: 8 Vector__XXX
 SG_ CellBalancingCount : 32|16@1+ (1,0) [0|64255] "" Vector__XXX
 SG_ ChargeCapacity : 16|16@1+ (0.01,0) [0|642.55] "Ah" Vector__XXX
 SG_ DisCapacity : 0|16@1+ (0.01,0) [0|642.55] "Ah" Vector__XXX

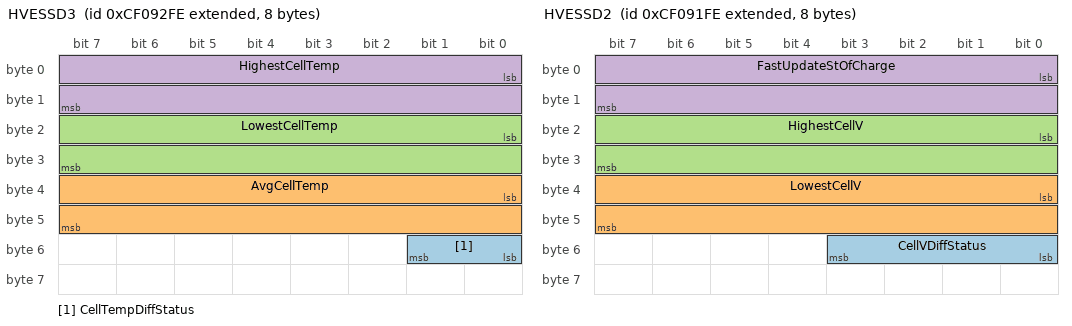
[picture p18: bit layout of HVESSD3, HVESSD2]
BO_ 2364576510 HVESSD3: 8 Vector__XXX
 SG_ CellTempDiffStatus : 48|2@1+ (1,0) [0|3] "" Vector__XXX
 SG_ AvgCellTemp : 32|16@1+ (0.03125,-273) [-273|1734.96875] "°C" Vector__XXX
 SG_ LowestCellTemp : 16|16@1+ (0.03125,-273) [-273|1734.96875] "°C" Vector__XXX
 SG_ HighestCellTemp : 0|16@1+ (0.03125,-273) [-273|1734.96875] "°C" Vector__XXX

BO_ 2364576254 HVESSD2: 8 Vector__XXX
 SG_ CellVDiffStatus : 48|4@1+ (1,0) [0|15] "" Vector__XXX
 SG_ LowestCellV : 32|16@1+ (0.001,0) [0|64.255] "V" Vector__XXX
 SG_ HighestCellV : 16|16@1+ (0.001,0) [0|64.255] "V" Vector__XXX
 SG_ FastUpdateStOfCharge : 0|16@1+ (0.0015625,0) [0|100.3984375] "%" Vector__XXX

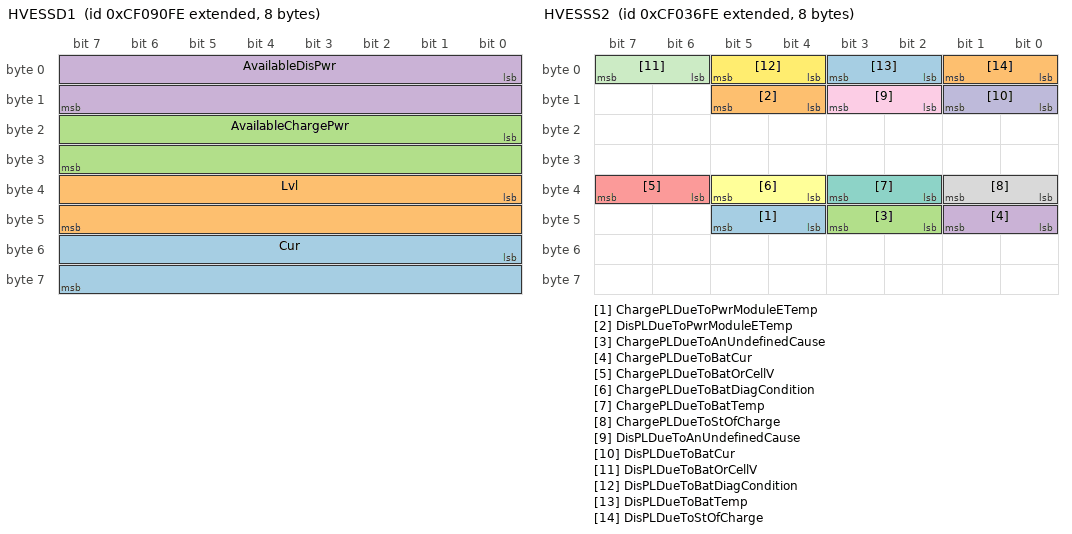
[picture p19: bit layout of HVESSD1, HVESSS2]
BO_ 2364575998 HVESSD1: 8 Vector__XXX
 SG_ Cur : 48|16@1+ (0.05,-1600) [-1600|1612.75] "A" Vector__XXX
 SG_ Lvl : 32|16@1+ (0.05,0) [0|3212.75] "V" Vector__XXX
 SG_ AvailableChargePwr : 16|16@1+ (0.05,0) [0|3212.75] "kW" Vector__XXX
 SG_ AvailableDisPwr : 0|16@1+ (0.05,0) [0|3212.75] "kW" Vector__XXX

BO_ 2364552958 HVESSS2: 8 Vector__XXX
 SG_ ChargePLDueToPwrModuleETemp : 44|2@1+ (1,0) [0|3] "" Vector__XXX
 SG_ DisPLDueToPwrModuleETemp : 12|2@1+ (1,0) [0|3] "" Vector__XXX
 SG_ ChargePLDueToAnUndefinedCause : 42|2@1+ (1,0) [0|3] "" Vector__XXX
 SG_ ChargePLDueToBatCur : 40|2@1+ (1,0) [0|3] "" Vector__XXX
 SG_ ChargePLDueToBatOrCellV : 38|2@1+ (1,0) [0|3] "" Vector__XXX
 SG_ ChargePLDueToBatDiagCondition : 36|2@1+ (1,0) [0|3] "" Vector__XXX
 SG_ ChargePLDueToBatTemp : 34|2@1+ (1,0) [0|3] "" Vector__XXX
 SG_ ChargePLDueToStOfCharge : 32|2@1+ (1,0) [0|3] "" Vector__XXX
 SG_ DisPLDueToAnUndefinedCause : 10|2@1+ (1,0) [0|3] "" Vector__XXX
 SG_ DisPLDueToBatCur : 8|2@1+ (1,0) [0|3] "" Vector__XXX
 SG_ DisPLDueToBatOrCellV : 6|2@1+ (1,0) [0|3] "" Vector__XXX
 SG_ DisPLDueToBatDiagCondition : 4|2@1+ (1,0) [0|3] "" Vector__XXX
 SG_ DisPLDueToBatTemp : 2|2@1+ (1,0) [0|3] "" Vector__XXX
 SG_ DisPLDueToStOfCharge : 0|2@1+ (1,0) [0|3] "" Vector__XXX

BO_ 2558459646 ESRRBR: 8 Vector__XXX
 SG_ ReqEngSpdDecelerationRateLmt : 16|16@1+ (1,0) [0|64255] "rpm/s" Vector__XXX
 SG_ ReqEngSpdAccelerationRateLmt : 0|16@1+ (1,0) [0|64255] "rpm/s" Vector__XXX

CM_ BO_ 2566642942 "Door Control 4
Used for door information.";
CM_ SG_ 2566642942 EnableStatusOfDoor30 "Enable status of bus door 30.  Enabled means the bus doors are able to be automatically opened or closed.

00b = Door disabled
01b = Door enabled
10b = Error
11b = Not available";
CM_ SG_ 2566642942 OpenStatusOfDoor30 "Open status of bus door 30

00b = Door closed
01b = Door opened
10b = Error
11b = Not available";
CM_ SG_ 2566642942 LockStatusOfDoor30 "Lock status of bus door 30

00b = Unlocked
01b = Locked
10b = Error
11b = Not available";
CM_ SG_ 2566642942 EnableStatusOfDoor29 "Enable status of bus door 29.  Enabled means the bus doors are able to be automatically opened or closed.

00b = Door disabled
01b = Door enabled
10b = Error
11b = Not available";
CM_ SG_ 2566642942 OpenStatusOfDoor29 "Open status of bus door 29

00b = Door closed
01b = Door opened
10b = Error
11b = Not available";
CM_ SG_ 2566642942 LockStatusOfDoor29 "Lock status of bus door 29

00b = Unlocked
01b = Locked
10b = Error
11b = Not available";
CM_ SG_ 2566642942 EnableStatusOfDoor28 "Enable status of bus door 28.  Enabled means the bus doors are able to be automatically opened or closed.

00b = Door disabled
01b = Door enabled
10b = Error
11b = Not available";
CM_ SG_ 2566642942 OpenStatusOfDoor28 "Open status of bus door 28

00b = Door closed
01b = Door opened
10b = Error
11b = Not available";
CM_ SG_ 2566642942 LockStatusOfDoor28 "Lock status of bus door 28

00b = Unlocked
01b = Locked
10b = Error
11b = Not available";
CM_ SG_ 2566642942 EnableStatusOfDoor27 "Enable status of bus door 27.  Enabled means the bus doors are able to be automatically opened or closed.

00b = Door disabled
01b = Door enabled
10b = Error
11b = Not available";
CM_ SG_ 2566642942 OpenStatusOfDoor27 "Open status of bus door 27

00b = Door closed
01b = Door opened
10b = Error
11b = Not available";
CM_ SG_ 2566642942 LockStatusOfDoor27 "Lock status of bus door 27

00b = Unlocked
01b = Locked
10b = Error
11b = Not available";
CM_ SG_ 2566642942 EnableStatusOfDoor26 "Enable status of bus door 26.  Enabled means the bus doors are able to be automatically opened or closed.

00b = Door disabled
01b = Door enabled
10b = Error
11b = Not available";
CM_ SG_ 2566642942 OpenStatusOfDoor26 "Open status of bus door 26

00b = Door closed
01b = Door opened
10b = Error
11b = Not available";
CM_ SG_ 2566642942 LockStatusOfDoor26 "Lock status of bus door 26

00b = Unlocked
01b = Locked
10b = Error
11b = Not available";
CM_ SG_ 2566642942 EnableStatusOfDoor25 "Enable status of bus door 25.  Enabled means the bus doors are able to be automatically opened or closed.

00b = Door disabled
01b = Door enabled
10b = Error
11b = Not available";
CM_ SG_ 2566642942 OpenStatusOfDoor25 "Open status of bus door 25

00b = Door closed
01b = Door opened
10b = Error
11b = Not available";
CM_ SG_ 2566642942 LockStatusOfDoor25 "Lock status of bus door 25

00b = Unlocked
01b = Locked
10b = Error
11b = Not available";
CM_ SG_ 2566642942 EnableStatusOfDoor24 "Enable status of bus door 24.  Enabled means the bus doors are able to be automatically opened or closed.

00b = Door disabled
01b = Door enabled
10b = Error
11b = Not available";
CM_ SG_ 2566642942 OpenStatusOfDoor24 "Open status of bus door 24

00b = Door closed
01b = Door opened
10b = Error
11b = Not available";
CM_ SG_ 2566642942 LockStatusOfDoor24 "Lock status of bus door 24

00b = Unlocked
01b = Locked
10b = Error
11b = Not available";
CM_ SG_ 2566642942 EnableStatusOfDoor23 "Enable status of bus door 23.  Enabled means the bus doors are able to be automatically opened or closed.

00b = Door disabled
01b = Door enabled
10b = Error
11b = Not available";
CM_ SG_ 2566642942 OpenStatusOfDoor23 "Open status of bus door 23

00b = Door closed
01b = Door opened
10b = Error
11b = Not available";
CM_ SG_ 2566642942 LockStatusOfDoor23 "Lock status of bus door 23

00b = Unlocked
01b = Locked
10b = Error
11b = Not available";
CM_ SG_ 2566642942 EnableStatusOfDoor22 "Enable status of bus door 22.  Enabled means the bus doors are able to be automatically opened or closed.

00b = Door disabled
01b = Door enabled
10b = Error
11b = Not available";
CM_ SG_ 2566642942 OpenStatusOfDoor22 "Open status of bus door 22

00b = Door closed
01b = Door opened
10b = Error
11b = Not available";
CM_ SG_ 2566642942 LockStatusOfDoor22 "Lock status of bus door 22

00b = Unlocked
01b = Locked
10b = Error
11b = Not available";
CM_ SG_ 2566642942 EnableStatusOfDoor21 "Enable status of bus door 21.  Enabled means the bus doors are able to be automatically opened or closed.

00b = Door disabled
01b = Door enabled
10b = Error
11b = Not available";
CM_ SG_ 2566642942 OpenStatusOfDoor21 "Open status of bus door 21

00b = Door closed
01b = Door opened
10b = Error
11b = Not available";
CM_ SG_ 2566642942 LockStatusOfDoor21 "Lock status of bus door 21

00b = Unlocked
01b = Locked
10b = Error
11b = Not available";
CM_ BO_ 2365315838 "DC/DC Converter 1 High Side Limits
Sets the HVES or High Voltage system limits for the transfer of energy between the high voltage system (i.e. high side) and the SLI battery or low voltage system (i.e. low side) using a DC/DC converter.
One ...";
CM_ SG_ 2365315838 HiSideCurMaxLmt "The maximum allowed high side current requested by a separate device.   Under normal conditions this requested limit would be reflected in SPN 8826.";
CM_ SG_ 2365315838 HiSideVMaxLmt "The maximum allowed high side voltage requested by a separate device.   Under normal conditions this requested limit would be reflected in SPN 8825.";
CM_ SG_ 2365315838 HiSideVMinLmt "The minimum allowed high side voltage requested by a separate device.   Under normal conditions this requested limit would be reflected in SPN 8824.";
CM_ BO_ 2365315582 "DC/DC Converter 1 Low Side Limits
Sets the SLI or Low Voltage system limits for the transfer of energy between the HVES or high voltage system (i.e. high side) and the SLI battery or low voltage system (i.e. low side) in a DC/DC Converter.";
CM_ SG_ 2365315582 LowSideCurMaxLmt "The maximum allowed low side current requested by a separate device.   Under normal conditions this requested limit would be reflected in SPN 8829.";
CM_ SG_ 2365315582 LowSideVMaxLmt "The maximum allowed low side voltage requested by a separate device.   Under normal conditions this requested limit would be reflected in SPN 8828.";
CM_ SG_ 2365315582 LowSideVMinLmt "The minimum allowed low side voltage requested by a separate device.   Under normal conditions this requested limit would be reflected in SPN 8827.";
CM_ BO_ 2365315326 "DC/DC Converter 1 Temperatures
DC/DC Converter measured temperature data.

One intended use of this message is for a conventional engine mounted alternator replacement.";
CM_ SG_ 2365315326 OneCoolantOutTemp "Parameter indicating the temperature of the DC/DC Converter Coolant measured at the output of the converter";
CM_ SG_ 2365315326 OneCoolantInTemp "Parameter indicating the temperature of the DC/DC Converter Coolant measured at the input of the converter";
CM_ SG_ 2365315326 PwrETemp "Parameter indicating the temperature of the DC/DC Converter power electronics components (e.g, switch or heatsink).";
CM_ SG_ 2365315326 ElectronicFilterTemp "Parameter indicating the temperature of the electronic components that make up the DC/DC Converter filter.";
CM_ SG_ 2365315326 Temp "Parameter indicating the temperature of the DC/DC Converter (e.g, controller, circuit board, enclosure).";
CM_ BO_ 2633750526 "Configurable Transmit PGNs Status
PGN 28928 and PGN 64471 are used to manage and report messages that are transmitted by a Configurable ECU. PGN 64471 is the response to PGN 28928. This message includes the PGs and their transmit status that can be ...";
CM_ SG_ 2633750526 PGNModifiedStatus "Indicates if able to honor the transmit status change request issued in the triggering PGN 28928 message for the associated PG on the port identified in SPN 8595.  This parameter is reported as '0' only if the received PGN 28928 requested a transmit ...";
CM_ SG_ 2633750526 PGNPendingChangeStatus "Indicates if there is a pending change to the transmit capability of the associated PG on the port identified in SPN 8599.
00b = Pending transmit change to disable for the port identified in SPN 8599.
01b = Pending transmit change to enable for ...";
CM_ SG_ 2633750526 PGNCurTransmitStatus "Indicates the current transmit status of the associated PG on the port identified in SPN 8599.
00b = PG is currently configured for transmit on the port identified in SPN 8599.
01b = PG is not currently configured for transmit on the port ...";
CM_ SG_ 2633750526 PGN "Identifies the PG for which the associated SPNs 8603, 8604, & 8605 apply.";
CM_ SG_ 2633750526 PortCmdStatus "Indicates the overall success in performing the commanded transaction in PGN 28928.
000b = Positive Acknowledgment - PGN 28928 commanded transaction was processed without issue.
001b = Negative Acknowledgment - PGN 28928 command was received but ...";
CM_ SG_ 2633750526 PortPendingChangesStatus "Indicates if there are any pending transmit changes for the specified ECU communication port.
0b = No pending changes to the transmit status for any supported PGs for the port identified in SPN 8599.
1b = Transmit changes are pending for one or ...";
CM_ SG_ 2633750526 Port "Identifies the ECU communications port of the responding Configurable ECU that is in context for this instance of PGN 64471.  If changes are accepted by the Configurable ECU, then this is the port affected.  The identification of each ECU ...";
CM_ BO_ 2566641406 "Electronic Engine Controller 21
Engine exhaust related parameters";
CM_ SG_ 2566641406 ExhManifoldPress2 "Absolute pressure of the exhaust gasses as measured at the engine exhaust manifold, location 2.";
CM_ SG_ 2566641406 ExhManifoldPress1 "Absolute pressure of the exhaust gasses as measured at the engine exhaust manifold, location 1.";
CM_ BO_ 2566641150 "Aftercooler and Oil Cooler Fluids 2
Temperature and pressures for the aftercooler and oil cooler.";
CM_ SG_ 2566641150 EngOilCoolerInTemp "Temperature of lube oil at engine cooler intake.";
CM_ SG_ 2566641150 EngOilCoolerDisPumpPress "Pressure of the lube oil at engine oil cooler discharge pump.";
CM_ SG_ 2566641150 AltOilCoolerDisPumpPress "Pressure of the lube oil at the alternator oil cooler discharge pump.";
CM_ SG_ 2566641150 AltBearingHeaderInPress "Pressure of the lube oil at the intake of alternator bearing header.";
CM_ BO_ 2633749758 "Well Stimulation Pump System Configuration
Communicates the configuration parameters of a well stimulation pump used in oil and gas drilling applications.
A well stimulation pump is a pump used to flow hydrocarbons from the drainage area into the ...";
CM_ SG_ 2633749758 RatedSpd "The rated speed of the well stimulation pump.";
CM_ SG_ 2633749758 GearRatio "Actual ratio of input shaft speed to output shaft speed.";
CM_ SG_ 2633749758 StrokeLength "The stroke length of the plunger in a well stimulation pump.";
CM_ SG_ 2633749758 PlungerDiameter "The diameter of the well stimulation pump plungers";
CM_ BO_ 2633749502 "Well Stimulation Pump System Lifetime Totals
Communicates the configuration parameters of a well stimulation pump used in oil and gas drilling applications.
A well stimulation pump is a pump used to flow hydrocarbons from the drainage area into ...";
CM_ SG_ 2633749502 CycleCount "The total number of cycles on the well stimulation pump. A cycle is defined as a working stage from start to finish.";
CM_ SG_ 2633749502 WorkingHours "The accumulated amount of time the Well Stimulation Pump has spent working.";
CM_ SG_ 2633749502 PwrEndWorkingHours "The accumulated time of operation of the power end of the pump while under operating conditions.";
CM_ SG_ 2633749502 FluidEndWorkingHours "The accumulated time of operation of the fluid end of the pump while under operating conditions.";
CM_ BO_ 2566640382 "Pump Oil Message
Pump oil related parameters.

.";
CM_ SG_ 2566640382 WellStimPumpOilTemp "Temperature of the well stimulation pump lubricant.";
CM_ SG_ 2566640382 WellStimPumpOilRelDielectricity "Well stimulation pump oil relative dielectricity used to describe the well stimulation pump oil quality.";
CM_ SG_ 2566640382 WellStimPumpOilDensity "Density of the well stimulation pump oil.";
CM_ SG_ 2566640382 WellStimPumpOilViscosity "Dynamic viscosity of the well stimulation pump oil.";
CM_ BO_ 2431719166 "Well Stimulation Pump System 3
Communicates operating parameters of a well stimulation pump used in oil and gas drilling applications.
A well stimulation pump is a pump used to flow hydrocarbons from the drainage area into the well bore of a oil ...";
CM_ SG_ 2431719166 RatedRodLoadPercent "Parameter which represents the ratio of the calculated rod load (reference SPN 8648) divided by the rated rod load of the pump * 100.";
CM_ SG_ 2431719166 FlowRate "The amount of fluid that is being pumped by the well stimulation pump.";
CM_ SG_ 2431719166 FluidEndVlvLeak "Indicates the leakage detected in the well stimulation pump fluid end.

00b = No Leak Detected
01b = Leak Detected
10b = Error
11b = Not Available";
CM_ SG_ 2431719166 CavitationStatus "Indicates the level of cavitation detected on the well stimulation pump.

000b = No Cavitation
001b = Low
010b = Medium
011b = High
100b = Reserved
101b = Reserved
110b = Error
111b = Not Available";
CM_ SG_ 2431719166 RodLoad "The load on the plungers of the well stimulation pump.";
CM_ BO_ 2364610046 "DC/DC Converter 1 SLI Battery Status
Status of the SLI battery measured at the SLI battery terminals.

One intended use of this message is for a conventional engine mounted alternator replacement.";
CM_ SG_ 2364610046 SLIBatTermTemp "Parameter indicating the SLI battery terminal temperature for control use by the DC/DC converter.";
CM_ SG_ 2364610046 SLIBatTermCur "Parameter indicating the SLI battery terminal current for control use by the DC/DC converter.  The current is positive if the SLI battery or low side voltage source is being charged from the HVES.";
CM_ SG_ 2364610046 SLIBatTermV "Parameter indicating the SLI battery terminal voltage for control use by the DC/DC converter.";
CM_ BO_ 2364609790 "DC/DC Converter 1 Voltage and Current
Voltage and current data from a DC/DC Converter.

One intended use of this message is for a conventional engine mounted alternator replacement.";
CM_ SG_ 2364609790 HiSideCur "Indicates the measured HVES or high side current measured at the point of control inside the DC/DC Converter.  The current is negative if the converter is charging the SLI battery from the hybrid battery.";
CM_ SG_ 2364609790 HiSideV "Indicates the measured HVES or high side voltage measured at the point of control inside the DC/DC Converter.";
CM_ SG_ 2364609790 LowSideCur "Indicates the measured SLI battery or low side current measured at the point of control inside the DC/DC Converter.  The current is positive if the converter is charging the SLI battery from the hybrid battery.";
CM_ SG_ 2364609790 LowSideV "Indicates the measured SLI battery or low side voltage measured at the point of control inside the DC/DC Converter.";
CM_ BO_ 2364609534 "DC/DC Converter 1 Operating Status
Contains information on the operating status of a DC/DC Converter.

One intended use of this message is for a conventional engine mounted alternator replacement.";
CM_ SG_ 2364609534 DCDC1OperatingStatusCRC "The CRC is defined as follows:
• Length: 8 bits
• Polynomial: x^8+x^5+x^3+x^2+x+1
• Initial Value: FFh
• Input Data Reflection: Not reflected
• Result Data Reflection: Not reflected
• XOR value: FFh
SAE makes no claim of the functional safety ...";
CM_ SG_ 2364609534 DCDC1OperatingStatusCounter "The message counter is used to detect situations where the transmitting ECU malfunction repeats the same frame all the time. The receiver of the information may use the counter parameter to detect this situation. The transmitting device will ...";
CM_ SG_ 2364609534 PLDueToUndefinedReason "Indicates whether or not output power is being limited due to an undefined reason.

00b = No power limit for this reason
01b = Power limited for this reason
10b = Error
11b = Not Available";
CM_ SG_ 2364609534 PLDueToSLIBatTermTemp "Indicates whether or not output power is being limited due to the SLI battery terminal temperature (see SPN 8591) approaching or exceeding limits (see SPN 8819).
00b = No power limit for this reason
01b = Power limited for this reason
10b = Error
 ...";
CM_ SG_ 2364609534 PLDueToSLIBatTermCur "Indicates whether or not output power is being limited due to the SLI battery terminal current (see SPN 8590) approaching or exceeding limits (see SPN 8818).
00b = No power limit for this reason
01b = Power limited for this reason
10b = Error
 ...";
CM_ SG_ 2364609534 PLDueToSLIBatTermV "Indicates whether or not output power is being limited due to the SLI battery terminal voltage (see SPN 8589) approaching or exceeding limits (see SPN 8817).
00b = No power limit for this reason
01b = Power limited for this reason
10b = Error
 ...";
CM_ SG_ 2364609534 PLDueToPwrETemp "Indicates whether or not output power is being limited due to Power Electronics Temperature (see SPN 8594) approaching or exceeding the maximum limit.
00b = No power limit for this reason
01b = Power limited for this reason
10b = Error
11b = Not ...";
CM_ SG_ 2364609534 PLDueToElectronicFilterTemp "Indicates whether or not output power is being limited due to Output Electronic Filter Temperature (see SPN 8693) approaching or exceeding the maximum limit.
00b = No power limit for this reason
01b = Power limited for this reason
10b = Error
 ...";
CM_ SG_ 2364609534 PLDueToCtrlTemp "Indicates whether or not output power is being limited due to Converter Temperature (see SPN 8592) approaching or exceeding the maximum limit.
00b = No power limit for this reason
01b = Power limited for this reason
10b = Error
11b = Not ...";
CM_ SG_ 2364609534 PLDueToLowSideVMax "Indicates whether or not output power is being limited due to low side voltage (see SPN 8585) approaching or exceeding the maximum limit (see SPN 8567).
00b = No power limit for this reason
01b = Power limited for this reason
10b = Error
11b = ...";
CM_ SG_ 2364609534 PLDueToLowSideVMin "Indicates whether or not output power is being limited due to low side voltage (see SPN 8585) approaching or falling below the minimum limit (see SPN 8566).
00b = No power limit for this reason
01b = Power limited for this reason
10b = Error
11b ...";
CM_ SG_ 2364609534 PLDueToHiSideVMax "Indicates whether or not output power is being limited due to high side voltage (see SPN 8587) approaching or exceeding the maximum limit (see SPN 8564).
00b = No power limit for this reason
01b = Power limited for this reason
10b = Error
11b = ...";
CM_ SG_ 2364609534 PLDueToHiSideVMin "Indicates whether or not output power is being limited due to high side voltage (see SPN 8587) approaching or falling below the minimum limit (see SPN 8563).
00b = No power limit for this reason
01b = Power limited for this reason
10b = Error
 ...";
CM_ SG_ 2364609534 PLDueToLowSideCur "Indicates whether or not output power is being limited due to low side current (see SPN 8586) approaching or exceeding the maximum limit (see SPN 8568).
00b = No power limit for this reason
01b = Power limited for this reason
10b = Error
11b = ...";
CM_ SG_ 2364609534 PLDueToHiSideCur "Indicates whether or not output power is being limited due to high side current (see SPN 8588) approaching or exceeding the maximum limit (see SPN 8565).
00b = No power limit for this reason
01b = Power limited for this reason
10b = Error
11b = ...";
CM_ SG_ 2364609534 LoadshedReq "The loadshed request is a request to the controlling device to reduce the DC/DC Converter loads.  The Loadshed Requested state is an indication that this DC/DC Converter has a malfunction or is in a limit condition and if the load of the output is ...";
CM_ SG_ 2364609534 HVILStatus "High Voltage Interlock Loop (HVIL) state of the DC/DC Converter.

00b = HVIL Closed
01b = HVIL Open
10b = Error
11b = Not Available";
CM_ SG_ 2364609534 OperationalStatus "Operating state of the DC/DC Converter
0000b = Disabled
0001b = Initialization in process.  The device is powering up.  This process may include both internal checks, as well as system checks being run by the DC/DC Converter.
0010b = Operational ...";
CM_ BO_ 2364609278 "DC/DC Converter 1 Control
Controls the transfer of energy between the HVES or high voltage system (i.e. high side) and the SLI battery or low voltage system (i.e. low side).  Provides a function to either charge the SLI Battery from the HVES (Buck) ...";
CM_ SG_ 2364609278 DCDC1CtrlCRC "The CRC is defined as follows:
• Length: 8 bits
• Polynomial: x^8+x^5+x^3+x^2+x+1
• Initial Value: FFh
• Input Data Reflection: Not reflected
• Result Data Reflection: Not reflected
• XOR value: FFh
SAE makes no claim of the functional safety ...";
CM_ SG_ 2364609278 DCDC1CtrlCounter "The message counter is used to detect situations where the transmitting ECU malfunction repeats the same frame all the time. The receiver of the information may use the counter parameter to detect this situation. The transmitting device will ...";
CM_ SG_ 2364609278 OneLowSideVBuckDefaultSetpoint "The set point for the converter default low side voltage during buck mode.   This setting may be used for when communication has been lost with the controlling device.  When set to Not Available (FFFFh), no default setting is provided and the system ...";
CM_ SG_ 2364609278 HiSideVBoostSetpoint "The set point for regulating the high side voltage during boost mode.";
CM_ SG_ 2364609278 LowSideVBuckSetpoint "The set point for regulating the low side voltage during buck mode.";
CM_ SG_ 2364609278 OperationalCmd "Command to enable or disable operation.
0000b = Disable - in this mode all high voltage switching is disabled
0001b = Operate in standby mode; system is waiting for command to enter buck or boost mode
0010b = Operate in buck mode; energy flows ...";
CM_ BO_ 2431717886 "Gaseous Fuel Pressure 3";
CM_ SG_ 2431717886 EngGasFuelSupplyFilterInPress "Pressure of gaseous fuel supply measured at the intake of gaseous fuel supply filter.";
CM_ SG_ 2431717886 EngGasFuelSupplyFilterDiffPress "Change in gaseous fuel delivery pressure, measured across the filter, due to accumulation of solid or semisolid matter on the filter element.";
CM_ SG_ 2431717886 EngFuelVlv1DiffPress "The differential pressure between the intake and the outlet of the first or only gaseous fuel valve.

See SPN 1391 for alternate range and resolution.";
CM_ BO_ 2297499902 "Brakes 2
Contains information on brake control.";
CM_ SG_ 2297499902 BrkPedalSw2 "Second switch signal instance which indicates that the driver operated brake foot pedal is being pressed. This parameter is functionally equivalent to SPN 597, but derived from a second, independent sensor and may be used where redundancy is ...";
CM_ SG_ 2297499902 DemandedBrkAppPress "Gage pressure of the compressed air or fluid in the vehicle braking system that is used to apply brake shoes (or pads) against the brake drums (or discs). This is the brake application pressure demanded by the vehicle operator and / or another ...";
CM_ BO_ 2364608510 "Engine Operating Information 2
Contains engine parameters related to operation.";
CM_ SG_ 2364608510 CoolantFlow "Used to detect the flow of engine coolant through an engine (usually from an engine coolant flow switch).

00b = No Engine Coolant Flow
01b = Engine Coolant is Flowing
10b = Error
11b = Not Available";
CM_ SG_ 2364608510 PwtnProtState "Engine powertrain protection derate enablement status; based on if the engine is or is not installed in a chassis. This is intended to be used in a factory test cell mode or service dyno mode situation (where the engine is not installed in a ...";
CM_ SG_ 2364608510 AFTThermalMnmgtElevatedIdleSt "Indicates that the engine is elevating the idle speed due to aftertreatment thermal management strategies.

00b = No Idle Elevation Active - standard idle speed
01b = Idle Elevation Active
10b = Reserved for SAE assignment
11b = Not Available";
CM_ SG_ 2364608510 PwrDerateReq "Derate request made from the engine control system to an external system, where the engine is requesting an external device to reduce the load being applied. A zero value indicates no derate, while any other value indicates the amount of load (in ...";
CM_ SG_ 2364608510 SelfInducedDerateLoad "The self-induced derate load that the Engine Control Module is trying to achieve.  A value of 0% means there is no active derate.";
CM_ BO_ 2498825982 "Dump Truck Body Information
Communicates the status and position of the dump body of an earth moving vehicle.";
CM_ SG_ 2498825982 BodyEjectorBladePos "The dump body ejector blade is used to push material out of the dump body of a dump truck. 0% represents the fully retracted position and 100% represents the fully extended position.";
CM_ SG_ 2498825982 BodyRaisePosRelToRecommendedMax "The angular position of the dump body expressed as a percentage of the maximum recommended body raised position. 100% represents the maximum default raised position of the dump body and is measured related to level ground.
Note:  Depending on the ...";
CM_ SG_ 2498825982 BodyRaiseAngle "The angular position of the dump body referenced to the vehicle chassis. 0 degrees represents the body in its resting position.";
CM_ SG_ 2498825982 BodyRollAngle "The angle between the dump body y-axis and the ground plane (i.e. rotation about the X-axis). The roll angle for a roll to the right is reported with a positive value. Roll angle is the same for both Z-Down and Z-Up axis systems, since both systems ...";
CM_ BO_ 2565934590 "Fuel Information 6 (Gaseous)
Gaseous fuel information 6";
CM_ SG_ 2565934590 EngFuelVlv2DiffPress "The differential pressure between the intake and the outlet of the second gaseous fuel valve.";
CM_ BO_ 2364607742 "High Voltage Energy Storage System Data 10
Data set 10 (electrical) for High Voltage Energy Storage System (or Pack 1 in systems with only one pack).";
CM_ SG_ 2364607742 HVBusPassiveIsolTestResults "The isolation resistance expressed in Ohms per Volt that resulted from the High-Voltage Bus Passive Isolation Test.
See SPN 8097 (HVESS High-Voltage Bus Passive Isolation Test Status) for test status and SPN 8126 (HVESS High-Voltage Bus Passive ...";
CM_ SG_ 2364607742 HVBusActiveIsolTestResults "The isolation resistance expressed in Ohms per Volt that resulted from the High-Voltage Bus Active Isolation Test.
See SPN 8096 (HVESS High-Voltage Bus Active Isolation Test Status) for test status and SPN 8125 (HVESS High-Voltage Bus Active ...";
CM_ SG_ 2364607742 LowestCellStOfChargeCellNum "Identifies the location of SPN 8084 (HVESS Lowest Cell State of Charge) within SPN 8247 (HVESS Lowest Cell State of Charge Module Number).
This parameter provides HVES system level information. If there are multiple packs in the system, then both ...";
CM_ SG_ 2364607742 LowestCellStOfChargeModuleNum "Identifies the location of the module containing SPN 8084 (HVESS Lowest Cell State of Charge).
This parameter provides HVES system level information. If there are multiple packs in the system, then both individual pack messages (e.g. HVESP1, HVESP2 ...";
CM_ SG_ 2364607742 HighestCellStOfChargeCellNum "Identifies the location of SPN 8085 (HVESS Highest Cell State of Charge) within SPN 8245 (HVESS Highest Cell State of Charge Module Number).
This parameter provides HVES system level information. If there are multiple packs in the system, then both ...";
CM_ SG_ 2364607742 HighestCellStOfChargeModuleNum "Identifies the location of the module containing SPN 8085 (HVESS Highest Cell State of Charge).
This parameter provides HVES system level information. If there are multiple packs in the system, then both individual pack messages (e.g. HVESP1, ...";
CM_ BO_ 2364607486 "High Voltage Energy Storage System Data 9
Data set 9 (thermal) for High Voltage Energy Storage System (or Pack 1 in systems with only one pack).";
CM_ SG_ 2364607486 Data9CRC "The CRC is defined as follows:
• Length: 8 bits
• Polynomial: x^8+x^5+x^3+x^2+x+1
• Initial Value: FFh
• Input Data Reflection: Not reflected
• Result Data Reflection: Not reflected
• XOR value: FFh
SAE makes no claim of the functional safety ...";
CM_ SG_ 2364607486 Data9Counter "The message counter is used to detect situations where the transmitting ECU malfunction repeats the same frame all the time. The receiver of the information may use the counter parameter to detect this situation. The transmitting device will ...";
CM_ SG_ 2364607486 Data9EmbeddedIntegritySupport "Indicates SPN 22973 (HVESS Data 9 CRC) and SPN 22972 (HVESS Data 9 Counter) are supported by the sender.
00b = Embedded CRC and Counter are supported by the sender
01b = Protection is supported using J1939-76 SHM
10b = Reserved
11b = CRC and ...";
CM_ SG_ 2364607486 ThermalEventDetected "A sensor has detected the presence of a thermal event at or near High Voltage Energy Storage System  (or Pack 1 in systems with only one pack).
00b = No Thermal Event Detected
01b = Thermal Event Detected
10b = Error
11b = Not available
This ...";
CM_ SG_ 2364607486 LowestCellTempCellNum "Identifies the location of SPN 8076 (HVESS Lowest Cell Temperature) within SPN 8243 (HVESS Lowest Cell Temperature Module Number).
This parameter provides HVES system level information. If there are multiple packs in the system, then both ...";
CM_ SG_ 2364607486 LowestCellTempModuleNum "Identifies the location of the module containing SPN 8076 (HVESS Lowest Cell Temperature ).
This parameter provides HVES system level information. If there are multiple packs in the system, then both individual pack messages (e.g. HVESP1, HVESP2 ...";
CM_ SG_ 2364607486 HighestCellTempCellNum "Identifies the location of SPN 8075 (HVESS Highest Cell Temperature) within SPN 8241 (HVESS Highest Cell Temperature Module Number).
This parameter provides HVES system level information. If there are multiple packs in the system, then both ...";
CM_ SG_ 2364607486 HighestCellTempModuleNum "Identifies the location of the module containing SPN 8075 (HVESS Highest Cell Temperature).
This parameter provides HVES system level information. If there are multiple packs in the system, then both individual pack messages (e.g. HVESP1, HVESP2 ...";
CM_ BO_ 2364607230 "High Voltage Energy Storage System Data 8
Data set 8 (electrical data) for High Voltage Energy Storage System (or Pack 1 in systems with only one pack).";
CM_ SG_ 2364607230 AvgCellV "The average cell voltage in the High Voltage Energy Storage System (or Pack 1 in systems with only one pack).
This parameter provides HVES system level information. If there are multiple packs in the system, then both individual pack messages (e.g ...";
CM_ SG_ 2364607230 LowestCellVCellNum "Identifies the location of SPN 5923 (HVESS Lowest Cell Voltage) within SPN 8238 (HVESS Lowest Cell Voltage Module Number).
This parameter provides HVES system level information. If there are multiple packs in the system, then both individual pack ...";
CM_ SG_ 2364607230 LowestCellVModuleNum "Identifies the location of the module containing SPN 5923 (HVESS Lowest Cell Voltage).
This parameter provides HVES system level information. If there are multiple packs in the system, then both individual pack messages (e.g. HVESP1, HVESP2 etc.) ...";
CM_ SG_ 2364607230 HighestCellVCellNum "Identifies the location of SPN 5922 (HVESS Highest Cell Voltage) within SPN 8236 (HVESS Highest Cell Voltage Module Number).
This parameter provides HVES system level information. If there are multiple packs in the system, then both individual pack ...";
CM_ SG_ 2364607230 HighestCellVModuleNum "Identifies the location of the module containing SPN 5922 (HVESS Highest Cell Voltage).
This parameter provides HVES system level information. If there are multiple packs in the system, then both individual pack messages (e.g. HVESP1, HVESP2 etc.) ...";
CM_ BO_ 2364606974 "High Voltage Energy Storage System Thermal Management System Status 1
Collection of data the High Voltage Energy Storage System (or Pack 1 in systems with only one pack) Thermal Management System sends to the Hybrid Controller.";
CM_ SG_ 2364606974 TMSCoolantLvl "Indicates the coolant level in the High Voltage Energy Storage System (or Pack 1 in systems with only one pack) Thermal Management System.
This parameter provides HVES system level information. If there are multiple packs in the system, then both ...";
CM_ SG_ 2364606974 TMSHVILStatus "Status of the High Voltage Interlock Loop from the viewpoint of the High Voltage Energy Storage System Thermal Management System 1.

00b = HVIL Closed
01b = HVIL Open
10b = Error
11b = Not Available";
CM_ SG_ 2364606974 TMSMode "Indicates the operating mode of the Thermal Management System.  The heat transfer medium may be (e.g. liquid or air).  The cooling system may be fans, liquid coolant, or a combination of mediums.  The system may include an air and/or liquid ...";
CM_ SG_ 2364606974 TMSHtrStatus "The state of the High Voltage Energy Storage System (or Pack 1 in systems with only one pack) heater
This parameter provides HVES system level information. If there are multiple packs in the system, then both individual pack messages (e.g. HVESP1, ...";
CM_ SG_ 2364606974 TMSRelHumidty "When the High Voltage Energy Storage System (or Pack 1 in systems with only one pack) Thermal Management System is equipped with a relative humidity sensor, this is the  measured Relative Humidity.
This parameter provides HVES system level ...";
CM_ SG_ 2364606974 TMSCompressorSpd "When the High Voltage Energy Storage System (or Pack 1 in systems with only one pack) Thermal Management System is equipped with an active cooling system (e.g. air conditioner), this is the Compressor Speed.
This parameter provides HVES system ...";
CM_ SG_ 2364606974 TMSHVInputPwr "This is the high-voltage power consumed by this Thermal Management System (TMS). If there is only one pack, or a single TMS for the entire HVES system, then this represents the total high-voltage power consumed.
This parameter provides HVES system ...";
CM_ SG_ 2364606974 TMSSLIInputPwr "This is the low-voltage power consumed by this Thermal Management System (TMS). If there is only one pack, or a single TMS for the entire HVES system, then this represents the total low-voltage power consumed.
This parameter provides HVES system ...";
CM_ BO_ 2364606718 "High Voltage Energy Storage System Module Status 1
Module Status message 1 for High Voltage Energy Storage System (or Pack 1 in systems with only one pack).";
CM_ SG_ 2364606718 Module32OperationalStatus "Operational Status of Module 32 in this High Voltage Energy Storage System (or Pack 1 in systems with only one pack).  Not Operational is used when the module is initializing or not able to function (e.g. internal module level monitors have failed) ...";
CM_ SG_ 2364606718 Module31OperationalStatus "Operational Status of Module 31 in this High Voltage Energy Storage System (or Pack 1 in systems with only one pack).  Not Operational is used when the module is initializing or not able to function (e.g. internal module level monitors have failed) ...";
CM_ SG_ 2364606718 Module30OperationalStatus "Operational Status of Module 30 in this High Voltage Energy Storage System (or Pack 1 in systems with only one pack).  Not Operational is used when the module is initializing or not able to function (e.g. internal module level monitors have failed) ...";
CM_ SG_ 2364606718 Module29OperationalStatus "Operational Status of Module 29 in this High Voltage Energy Storage System (or Pack 1 in systems with only one pack).  Not Operational is used when the module is initializing or not able to function (e.g. internal module level monitors have failed) ...";
CM_ SG_ 2364606718 Module28OperationalStatus "Operational Status of Module 28 in this High Voltage Energy Storage System (or Pack 1 in systems with only one pack).  Not Operational is used when the module is initializing or not able to function (e.g. internal module level monitors have failed) ...";
CM_ SG_ 2364606718 Module27OperationalStatus "Operational Status of Module 27 in this High Voltage Energy Storage System (or Pack 1 in systems with only one pack).  Not Operational is used when the module is initializing or not able to function (e.g. internal module level monitors have failed) ...";
CM_ SG_ 2364606718 Module26OperationalStatus "Operational Status of Module 26 in this High Voltage Energy Storage System (or Pack 1 in systems with only one pack).  Not Operational is used when the module is initializing or not able to function (e.g. internal module level monitors have failed) ...";
CM_ SG_ 2364606718 Module25OperationalStatus "Operational Status of Module 25 in this High Voltage Energy Storage System (or Pack 1 in systems with only one pack).  Not Operational is used when the module is initializing or not able to function (e.g. internal module level monitors have failed) ...";
CM_ SG_ 2364606718 Module24OperationalStatus "Operational Status of Module 24 in this High Voltage Energy Storage System (or Pack 1 in systems with only one pack).  Not Operational is used when the module is initializing or not able to function (e.g. internal module level monitors have failed) ...";
CM_ SG_ 2364606718 Module23OperationalStatus "Operational Status of Module 23 in this High Voltage Energy Storage System (or Pack 1 in systems with only one pack).  Not Operational is used when the module is initializing or not able to function (e.g. internal module level monitors have failed) ...";
CM_ SG_ 2364606718 Module22OperationalStatus "Operational Status of Module 22 in this High Voltage Energy Storage System (or Pack 1 in systems with only one pack).  Not Operational is used when the module is initializing or not able to function (e.g. internal module level monitors have failed) ...";
CM_ SG_ 2364606718 Module21OperationalStatus "Operational Status of Module 21 in this High Voltage Energy Storage System (or Pack 1 in systems with only one pack).  Not Operational is used when the module is initializing or not able to function (e.g. internal module level monitors have failed) ...";
CM_ SG_ 2364606718 Module20OperationalStatus "Operational Status of Module 20 in this High Voltage Energy Storage System (or Pack 1 in systems with only one pack).  Not Operational is used when the module is initializing or not able to function (e.g. internal module level monitors have failed) ...";
CM_ SG_ 2364606718 Module19OperationalStatus "Operational Status of Module 19 in this High Voltage Energy Storage System (or Pack 1 in systems with only one pack).  Not Operational is used when the module is initializing or not able to function (e.g. internal module level monitors have failed) ...";
CM_ SG_ 2364606718 Module18OperationalStatus "Operational Status of Module 18 in this High Voltage Energy Storage System (or Pack 1 in systems with only one pack).  Not Operational is used when the module is initializing or not able to function (e.g. internal module level monitors have failed) ...";
CM_ SG_ 2364606718 Module17OperationalStatus "Operational Status of Module 17 in the High Voltage Energy Storage System (or Pack 1 in systems with only one pack).  Not Operational is used when the module is initializing or not able to function (e.g. internal module level monitors have failed) ...";
CM_ SG_ 2364606718 Module16OperationalStatus "Operational Status of Module 16 in the High Voltage Energy Storage System (or Pack 1 in systems with only one pack).  Not Operational is used when the module is initializing or not able to function (e.g. internal module level monitors have failed) ...";
CM_ SG_ 2364606718 Module15OperationalStatus "Operational Status of Module 15 in the High Voltage Energy Storage System (or Pack 1 in systems with only one pack).  Not Operational is used when the module is initializing or not able to function (e.g. internal module level monitors have failed) ...";
CM_ SG_ 2364606718 Module14OperationalStatus "Operational Status of Module 14 in the High Voltage Energy Storage System (or Pack 1 in systems with only one pack).  Not Operational is used when the module is initializing or not able to function (e.g. internal module level monitors have failed) ...";
CM_ SG_ 2364606718 Module13OperationalStatus "Operational Status of Module 13 in the High Voltage Energy Storage System (or Pack 1 in systems with only one pack).  Not Operational is used when the module is initializing or not able to function (e.g. internal module level monitors have failed) ...";
CM_ SG_ 2364606718 Module12OperationalStatus "Operational Status of Module 12 in the High Voltage Energy Storage System (or Pack 1 in systems with only one pack).  Not Operational is used when the module is initializing or not able to function (e.g. internal module level monitors have failed) ...";
CM_ SG_ 2364606718 Module11OperationalStatus "Operational Status of Module 11 in the High Voltage Energy Storage System (or Pack 1 in systems with only one pack).  Not Operational is used when the module is initializing or not able to function (e.g. internal module level monitors have failed) ...";
CM_ SG_ 2364606718 Module10OperationalStatus "Operational Status of Module 10 in the High Voltage Energy Storage System (or Pack 1 in systems with only one pack).  Not Operational is used when the module is initializing or not able to function (e.g. internal module level monitors have failed) ...";
CM_ SG_ 2364606718 Module9OperationalStatus "Operational Status of Module 9 in the High Voltage Energy Storage System (or Pack 1 in systems with only one pack).  Not Operational is used when the module is initializing or not able to function (e.g. internal module level monitors have failed) ...";
CM_ SG_ 2364606718 Module8OperationalStatus "Operational Status of Module 8 in the High Voltage Energy Storage System (or Pack 1 in systems with only one pack).  Not Operational is used when the module is initializing or not able to function (e.g. internal module level monitors have failed) ...";
CM_ SG_ 2364606718 Module7OperationalStatus "Operational Status of Module 7 in the High Voltage Energy Storage System (or Pack 1 in systems with only one pack).  Not Operational is used when the module is initializing or not able to function (e.g. internal module level monitors have failed) ...";
CM_ SG_ 2364606718 Module6OperationalStatus "Operational Status of Module 6 in the High Voltage Energy Storage System (or Pack 1 in systems with only one pack).  Not Operational is used when the module is initializing or not able to function (e.g. internal module level monitors have failed) ...";
CM_ SG_ 2364606718 Module5OperationalStatus "Operational Status of Module 5 in the High Voltage Energy Storage System (or Pack 1 in systems with only one pack).  Not Operational is used when the module is initializing or not able to function (e.g. internal module level monitors have failed) ...";
CM_ SG_ 2364606718 Module4OperationalStatus "Operational Status of Module 4 in the High Voltage Energy Storage System (or Pack 1 in systems with only one pack).  Not Operational is used when the module is initializing or not able to function (e.g. internal module level monitors have failed) ...";
CM_ SG_ 2364606718 Module3OperationalStatus "Operational Status of Module 3 in the High Voltage Energy Storage System (or Pack 1 in systems with only one pack).  Not Operational is used when the module is initializing or not able to function (e.g. internal module level monitors have failed) ...";
CM_ SG_ 2364606718 Module2OperationalStatus "Operational Status of Module 2 in the High Voltage Energy Storage System (or Pack 1 in systems with only one pack).  Not Operational is used when the module is initializing or not able to function (e.g. internal module level monitors have failed) ...";
CM_ SG_ 2364606718 Module1OperationalStatus "Operational Status of Module 1 in the High Voltage Energy Storage System (or Pack 1 in systems with only one pack).  Not Operational is used when the module is initializing or not able to function (e.g. internal module level monitors have failed) ...";
CM_ BO_ 2565933054 "Well Stimulation Pump System 2
Communicates operating parameters of a well stimulation pump used in oil and gas drilling applications.
A well stimulation pump is a pump used to flow hydrocarbons from the drainage area into the well bore of a oil ...";
CM_ SG_ 2565933054 GearBoxOutOilTemp "Temperature of the oil at the outlet of the well stimulation pump gear box.  Reference SPN 8157 for the temperature at the inlet of the pump gear box.";
CM_ SG_ 2565933054 Spd "The operating speed of the well stimulation pump.";
CM_ SG_ 2565933054 GearBoxOilTemp "Temperature of the oil in the well stimulation pump gear box.";
CM_ SG_ 2565933054 GearBoxOilPress "The oil pressure measured in the well stimulation pump gear box.";
CM_ BO_ 2565932798 "Well Stimulation Pump System 1
Communicates operating parameters of a well stimulation pump used in oil and gas drilling applications.
A well stimulation pump is a pump used to flow hydrocarbons from the drainage area into the well bore of a oil ...";
CM_ SG_ 2565932798 DisPress "The pressure on the discharge side of the well stimulation pump.";
CM_ SG_ 2565932798 SuctionPress "The pressure on the suction side of the well stimulation pump.";
CM_ BO_ 2364605950 "Hydraulic Pressure Displacement
Sensors related to hydraulic measurement and displacement.";
CM_ SG_ 2364605950 MechMovementAngle "The angle of rotation of the mechanical component.
The increase and decrease of the value (i.e. rotation about the X-axis) is in accordance to the right-hand rule, as specified in SAE J670, with the positive X axis directed inward along the center ...";
CM_ SG_ 2364605950 LinePress "The pressure of the hydraulic fluid, measured in the hydraulic line.";
CM_ BO_ 2565932286 "Engine Speed Sensor Information 2
This PG contains the speed information and status signal of each engine speed sensor. This message is used for service to troubleshoot no-start or hard start problems.  This message is not needed except for ...";
CM_ SG_ 2565932286 Vour "The engine speed as measured by speed sensor 4.
Notes: This is for the engine speed from the 4th engine speed sensor. This may be different than SPN 190 when used in multiple engine speed sensor configurations. In an application with multiple ...";
CM_ BO_ 2364605438 "Generator Trip Energy
This PG contains quantities for the \"trip\" energy from the generator.

These values can be reset by the user.";
CM_ SG_ 2364605438 KVArHoursExport "The trip AC reactive energy exported by the generator since the last reset of the trip kVArh meter.

This value will be reset by the user at will.";
CM_ SG_ 2364605438 KWHoursExport "The total kilowatt-hours that have been exported by the generator since the last reset of the trip kWh meter.

This value will be reset by the user at will.";
CM_ BO_ 2364605182 "Primary or Rear Hitch Roll and Pitch Command
Provides control of rear hitch roll and pitch.";
CM_ SG_ 2364605182 PitchSensitivityCmd "Command for setting the sensitivity of the rear hitch pitch control expressed as a percentage of the maximum gain. 0% indicates minimal gain in the control loop; 100%, the maximum gain. Values near zero may result in no reaction by the control loop.";
CM_ SG_ 2364605182 PitchCmd "Command for setting the pitch angle of the rear three-point hitch expressed in degrees from vertical alignment of the upper and lower attachment points. Positive is in the anti-clockwise direction when viewed from the left-hand side of the tractor.";
CM_ SG_ 2364605182 SensitivityCmd "Command for setting the sensitivity of the rear hitch roll control expressed as a percentage of the maximum gain. 0% indicates minimal gain in the control loop; 100%, the maximum gain. Values near zero may result in no reaction by the control loop.";
CM_ SG_ 2364605182 Cmd "Command for setting the roll angle of the rear three-point hitch expressed in degrees with 0 being horizontally aligned with the rear axle of the tractor. Facing the direction of travel, an anti-clockwise rotation would be indicated by a negative ...";
CM_ BO_ 2364604926 "Primary or Rear Hitch Roll and Pitch
Provides roll and pitch information for the rear hitch.";
CM_ SG_ 2364604926 PitchExit_ReasonCode "Used to indicate why the rear hitch cannot accept remote pitch commands or has most recently stopped accepting remote commands.
000000 = No reason/all clear
000001 = Required level of operator presence/awareness not detected
000010 = Implement ...";
CM_ SG_ 2364604926 PitchLmtSt "Used to report the Tractor ECU's present limit status associated with the rear hitch pitch commands.
000 = Not limited
001 = Operator limited/controlled (request cannot be implemented)
010 = Limited High (only lower command values result in a ...";
CM_ SG_ 2364604926 PitchAngle "Measured pitch angle of the rear three-point hitch expressed in degrees from vertical alignment of the upper and lower attachment points. Positive is in the anti-clockwise direction when viewed from the left-hand side of the tractor.";
CM_ SG_ 2364604926 Exit_ReasonCode "Used to indicate why the rear hitch cannot accept remote roll commands or has most recently stopped accepting remote commands.
000000 = No reason/all clear
000001 = Required level of operator presence/awareness not detected
000010 = Implement ...";
CM_ SG_ 2364604926 LmtSt "Used to report the Tractor ECU's present limit status associated with the rear hitch roll commands.
000 = Not limited
001 = Operator limited/controlled (request cannot be implemented)
010 = Limited High (only lower command values result in a ...";
CM_ SG_ 2364604926 Angle "Measured roll angle of the rear three-point hitch expressed in degrees from horizontal alignment with the rear axle of the tractor. Facing the direction of travel, an anti-clockwise rotation would be indicated by a negative number and a clockwise ...";
CM_ BO_ 2364604670 "Secondary or Front Hitch Roll and Pitch Command
Provides control of front hitch roll and pitch.";
CM_ SG_ 2364604670 PitchSensitivityCmd "Command for setting the sensitivity of the front hitch pitch control expressed as a percentage of the maximum gain. 0% indicates minimal gain in the control loop; 100%, the maximum gain. Values near zero may result in no reaction by the control ...";
CM_ SG_ 2364604670 PitchCmd "Command for setting the pitch angle of the front three-point hitch expressed in degrees from vertical alignment of the upper and lower attachment points. Positive is in the anti-clockwise direction when viewed from the left-hand side of the tractor.";
CM_ SG_ 2364604670 SensitivityCmd "Command for setting the sensitivity of the front hitch roll control expressed as a percentage of the maximum gain. 0% indicates minimal gain in the control loop; 100%, the maximum gain. Values near zero may result in no reaction by the control loop.";
CM_ SG_ 2364604670 Cmd "Command for setting the roll angle of the front three-point hitch expressed in degrees with 0 being horizontally aligned with the rear axle of the tractor. Facing the direction of travel, an anti-clockwise rotation would be indicated by a negative ...";
CM_ BO_ 2364604414 "Secondary or Front Hitch Roll and Pitch
Provides roll and pitch information for the front hitch.";
CM_ SG_ 2364604414 PitchExit_ReasonCode "Used to indicate why the front hitch cannot accept remote pitch commands or has most recently stopped accepting remote commands.
000000 = No reason/all clear
000001 = Required level of operator presence/awareness not detected
000010 = Implement ...";
CM_ SG_ 2364604414 PitchLmtSt "Used to report the Tractor ECU's present limit status associated with the front hitch pitch commands.
000 = Not limited
001 = Operator limited/controlled (request cannot be implemented)
010 = Limited High (only lower command values result in a ...";
CM_ SG_ 2364604414 PitchAngle "Measured pitch angle of the front three-point hitch expressed in degrees from vertical alignment of the upper and lower attachment points. Positive is in the anti-clockwise direction when viewed from the left-hand side of the tractor.";
CM_ SG_ 2364604414 Exit_ReasonCode "Used to indicate why the front hitch cannot accept remote roll commands or has most recently stopped accepting remote commands.
000000 = No reason/all clear
000001 = Required level of operator presence/awareness not detected
000010 = Implement ...";
CM_ SG_ 2364604414 LmtSt "Used to report the Tractor ECU's present limit status associated with the front hitch roll commands.
000 = Not limited
001 = Operator limited/controlled (request cannot be implemented)
010 = Limited High (only lower command values result in a ...";
CM_ SG_ 2364604414 Angle "Measured roll angle of the front three-point hitch expressed in degrees from horizontal alignment with the rear axle of the tractor. Facing the direction of travel, an anti-clockwise rotation would be indicated by a negative number and a clockwise ...";
CM_ BO_ 2364604158 "Aftertreatment 2 SCR Dosing System Information 4
This message contains SCR dosing system information for aftertreatment system 2 (or bank 2).";
CM_ SG_ 2364604158 DEFActualQuantityOfIntegrator "The SCR requested diesel exhaust fluid integrator total quantity for aftertreatment system 2 (exhaust bank 2).  See SPN 4386 for alternate resolution.";
CM_ BO_ 2364603902 "Aftertreatment 1 SCR Dosing System Information 4
This message contains SCR dosing system request information for aftertreatment system 1 (or bank 1).";
CM_ SG_ 2364603902 DEFActualQuantityOfIntegrator "The SCR requested diesel exhaust fluid integrator total quantity for aftertreatment system 1 (exhaust bank 1).  See SPN 4333 for alternate resolution.";
CM_ BO_ 2364603646 "Aftertreatment 2 SCR Dosing System Requests 3
This message contains SCR dosing system request information for aftertreatment system 2 (or bank 2).";
CM_ SG_ 2364603646 DEFDoserVlv2Cmd "Command (in percent) sent to the second valve of the diesel exhaust fluid (DEF) injector to control the amount of DEF being injected into the aftreatment system 2 (bank 2) exhaust stream.

0% closes the valve; 100% fully opens the valve.";
CM_ SG_ 2364603646 DEFDoserVlv1Cmd "Command (in percent) sent to the diesel exhaust fluid (DEF) injector to control the amount of DEF being injected into the aftreatment system 2 (bank 2) exhaust stream.

0% closes the valve; 100% fully opens the valve.";
CM_ SG_ 2364603646 DEFReqQuantityOfIntegrator "Represents the command for the diesel exhaust fluid quantity integrator in the dosing control unit. See SPN 4403 for alternate resolution.";
CM_ BO_ 2364603390 "Aftertreatment 1 SCR Dosing System Requests 3
This message contains SCR dosing system request information for aftertreatment system 1 (or bank 1).";
CM_ SG_ 2364603390 DEFDoserVlv2Cmd "Command (in percent) sent to the second valve of the diesel exhaust fluid (DEF) injector to control the amount of DEF being injected into the aftreatment exhaust stream.

0% closes the valve; 100% fully opens the valve.";
CM_ SG_ 2364603390 DEFDoserVlv1Cmd "Command (in percent) sent to the diesel exhaust fluid (DEF) injector to control the amount of DEF being injected into the aftreatment exhaust stream.

0% closes the valve; 100% fully opens the valve.";
CM_ SG_ 2364603390 DEFReqQuantityOfIntegrator "Represents the command for the diesel exhaust fluid quantity integrator in the dosing control unit. See SPN 4350 for alternate resolution.";
CM_ BO_ 2364603134 "Electronic Transmission Controller 13
Electronic Transmission Controller 13";
CM_ SG_ 2364603134 Mode20Ind "This state signal is the transmission's indication that it is operating under transmission mode 20 (SPN 12958) as commanded via the TC2 message (PGN 3328).  The definition of the transmission mode is left to the discretion of the transmission ...";
CM_ SG_ 2364603134 Mode19Ind "This state signal is the transmission's indication that it is operating under transmission mode 19 (SPN 12957) as commanded via the TC2 message (PGN 3328).  The definition of the transmission mode is left to the discretion of the transmission ...";
CM_ SG_ 2364603134 Mode18Ind "This state signal is the transmission's indication that it is operating under transmission mode 18 (SPN 12956) as commanded via the TC2 message (PGN 3328).  The definition of the transmission mode is left to the discretion of the transmission ...";
CM_ SG_ 2364603134 Mode17Ind "This state signal is the transmission's indication that it is operating under transmission mode 17 (SPN 12955) as commanded via the TC2 message (PGN 3328).  The definition of the transmission mode is left to the discretion of the transmission ...";
CM_ SG_ 2364603134 Mode16Ind "This state signal is the transmission's indication that it is operating under transmission mode 16 (SPN 12954) as commanded via the TC2 message (PGN 3328).  The definition of the transmission mode is left to the discretion of the transmission ...";
CM_ SG_ 2364603134 Mode15Ind "This state signal is the transmission's indication that it is operating under transmission mode 15 (SPN 12953) as commanded via the TC2 message (PGN 3328).  The definition of the transmission mode is left to the discretion of the transmission ...";
CM_ SG_ 2364603134 Mode14Ind "This state signal is the transmission's indication that it is operating under transmission mode 14 (SPN 12952) as commanded via the TC2 message (PGN 3328).  The definition of the transmission mode is left to the discretion of the transmission ...";
CM_ SG_ 2364603134 Mode13Ind "This state signal is the transmission's indication that it is operating under transmission mode 13 (SPN 12951) as commanded via the TC2 message (PGN 3328).  The definition of the transmission mode is left to the discretion of the transmission ...";
CM_ SG_ 2364603134 Mode12Ind "This state signal is the transmission's indication that it is operating under transmission mode 12 (SPN 12950) as commanded via the TC2 message (PGN 3328).  The definition of the transmission mode is left to the discretion of the transmission ...";
CM_ SG_ 2364603134 Mode11Ind "This state signal is the transmission's indication that it is operating under transmission mode 11 (SPN 12949) as commanded via the TC2 message (PGN 3328).  The definition of the transmission mode is left to the discretion of the transmission ...";
CM_ SG_ 2364603134 SAOfActiveOrPendingTransReqGear "This parameter indicates the source address of the device whose SPN 525 [Transmission Requested Gear] request is currently being acted upon by the transmission. If transmission response to a device’s SPN 525 request is pending, that device’s source ...";
CM_ SG_ 2364603134 MaxReverseTransOSS "Maximum transmission output shaft speed that can be achieved in the reverse direction, based on current operating conditions.";
CM_ SG_ 2364603134 MaxForwardTransOSS "Maximum transmission output shaft speed that can be achieved in the forward direction, based on current operating conditions.";
CM_ BO_ 2364602878 "Engine Valve Controller
Transmits information about the engine valve control  module used to control the valves on the engine.";
CM_ SG_ 2364602878 CtrlModule8PreliminaryFMI "Used to identify the applicable J1939-73 FMI detected in Engine Valve Control Module 8 by the manufacturer's software.  When there are multiple failures, the most severe is transmitted.
A value of 31 is sent to indicate that no failure has been ...";
CM_ SG_ 2364602878 CtrlModule7PreliminaryFMI "Used to identify the applicable J1939-73 FMI detected in Engine Valve Control Module 7 by the manufacturer's software. When there are multiple failures, the most severe is transmitted.
A value of 31 is sent to indicate that no failure has been ...";
CM_ SG_ 2364602878 CtrlModule6PreliminaryFMI "Used to identify the applicable J1939-73 FMI detected in Engine Valve Control Module 6 by the manufacturer's software.  When there are multiple failures, the most severe is transmitted.
A value of 31 is sent to indicate that no failure has been ...";
CM_ SG_ 2364602878 CtrlModule5PreliminaryFMI "Used to identify the applicable J1939-73 FMI detected in Engine Valve Control Module 5 by the manufacturer's software.  When there are multiple failures, the most severe is transmitted.
A value of 31 is sent to indicate that no failure has been ...";
CM_ SG_ 2364602878 CtrlModule4PreliminaryFMI "Used to identify the applicable J1939-73 FMI detected in Engine Valve Control Module 4 by the manufacturer's software.  When there are multiple failures, the most severe is transmitted.
A value of 31 is sent to indicate that no failure has been ...";
CM_ SG_ 2364602878 CtrlModule3PreliminaryFMI "Used to identify the applicable J1939-73 FMI detected in Engine Valve Control Module 3 by the manufacturer's software.  When there are multiple failures, the most severe is transmitted.
A value of 31 is sent to indicate that no failure has been ...";
CM_ SG_ 2364602878 CtrlModule2PreliminaryFMI "Used to identify the applicable J1939-73 FMI detected in Engine Valve Control Module 2 by the manufacturer's software.  When there are multiple failures, the most severe is transmitted.
A value of 31 is sent to indicate that no failure has been ...";
CM_ SG_ 2364602878 CtrlModule1PreliminaryFMI "Used to identify the applicable J1939-73 FMI detected in Engine Valve Control Module 1 by the manufacturer's software.  When there are multiple failures, the most severe is transmitted.
A value of 31 is sent to indicate that no failure has been ...";
CM_ BO_ 2565923838 "DC/AC Accessory Inverter 4 Feedback
Sent by this DC/AC Accessory Inverter instance and contains the current operating conditions of this output of the inverter.  This message would be received by a controller application (e.g. Power System Manager) ...";
CM_ SG_ 2565923838 HVILStatus "High Voltage Interlock Loop (HVIL) state of the DC/AC Accessory Inverter 4.

00b = HVIL Closed
01b = HVIL Open
10b = Error
11b = Not Available";
CM_ SG_ 2565923838 ACSideRMSCur "Present operating AC Side output RMS line Current of this DC/AC Accessory Inverter.  When connected to a balanced three phase motor, this would be the current in each individual phase of the motor.";
CM_ SG_ 2565923838 LoadshedReq "Loadshed Request from this DC/AC Accessory Inverter output.  The Loadshed Requested state is an indication that the inverter output powering this device has a malfunction and is in a limit condition and if the load of the output is not reduced, the ...";
CM_ SG_ 2565923838 StatusFeedback "Operating Status of this DC/AC Accessory Inverter output. The Inverter Output Faulted state will be communicated when the inverter output has shutdown due to an overload condition or other fault.
000b = Output Disabled
001b = Output Enabled
010b ...";
CM_ SG_ 2565923838 PwrFeedback "Present operating AC Side power of this DC/AC Accessory Inverter output.";
CM_ SG_ 2565923838 VFeedback "Present operating AC Side line to line RMS voltage of this DC/AC Accessory Inverter output.  In a three phase balanced motor, this is the RMS voltage across one phase of the motor.";
CM_ SG_ 2565923838 FreqFeedback "Present operating frequency of this DC/AC Accessory Inverter output.";
CM_ BO_ 2565923582 "DC/AC Accessory Inverter 4 Command
Used to command this instance of an DC/AC Accessory Inverter that uses a V/Hz algorithm.  The Inverter may have multiple outputs to power accessories on a vehicle (e.g. HVAC compressor, air compressor, power ...";
CM_ SG_ 2565923582 ACSideMotorStartingRMSVReq "Signal to the DC/AC Accessory Inverter indicating the requested AC side RMS voltage for starting the attached accessory motor.   In a V/Hz variable speed motor control application, this voltage typically may be set to a non-zero value when an ...";
CM_ SG_ 2565923582 EnableCmd "Command to the DC/AC Accessory Inverter to enable this output.  Each output may control multiple devices (e.g. electric motors) if they all operate at the same frequency.
00b = Disable DC/AC Accessory Inverter Output
01b = Enable DC/AC Accessory ...";
CM_ SG_ 2565923582 Device2Status "Signal to the DC/AC Accessory Inverter indicating the state of the device attached to the inverter output.  Each output may control multiple devices (e.g. electric motors) if they all operate at the same frequency.
The Faulted Off state will be ...";
CM_ SG_ 2565923582 Device1Status "Signal to the DC/AC Accessory Inverter indicating the state of the device attached to the inverter output.  Each output may control multiple devices (e.g. electric motors) if they all operate at the same frequency.
The Faulted Off state will be ...";
CM_ SG_ 2565923582 FreqCmd "Command to the DC/AC Accessory Inverter indicating the Inverter frequency desired for the device(s) attached to the inverter output.  Each output may control multiple devices (e.g. electric motors) if they all operate at the same frequency.";
CM_ SG_ 2565923582 DeviceFreqRateOfChangeLmt "Signal to the DC/AC Accessory Inverter indicating the frequency rate of change limit of the device(s) attached to the inverter output (Note: Increasing and decreasing rates can be controlled by the same signal).  Each output may control multiple ...";
CM_ SG_ 2565923582 DeviceRatedV "Signal to the DC/AC Accessory Inverter indicating the rated RMS voltage of the device(s) attached to the inverter output.   Each output may control multiple devices (e.g. electric motors) if they all operate at the same frequency.";
CM_ SG_ 2565923582 DeviceRatedFreq "Signal to the DC/AC Accessory Inverter indicating the rated frequency of the device(s) attached to the inverter output.  Each output may control multiple devices (e.g. electric motors) if they all operate at the same frequency.";
CM_ SG_ 2565923582 DeviceMinFreq "Signal to the DC/AC Accessory Inverter indicating the minimum frequency of the device(s) attached to the inverter output.  Each output may control multiple devices (e.g. electric motors) if they all operate at the same frequency.";
CM_ SG_ 2565923582 DeviceMaxFreq "Signal to the DC/AC Accessory Inverter indicating the maximum frequency of the devices(s) attached to the inverter output.  Each output may control multiple devices (e.g. electric motors) if they all operate at the same frequency.";
CM_ BO_ 2565922814 "DC/AC Accessory Inverter 3 Feedback
Sent by this DC/AC Accessory Inverter instance and contains the current operating conditions of this output of the inverter.  This message would be received by a controller application (e.g. Power System Manager) ...";
CM_ SG_ 2565922814 HVILStatus "High Voltage Interlock Loop (HVIL) state of the DC/AC Accessory Inverter 3.

00b = HVIL Closed
01b = HVIL Open
10b = Error
11b = Not Available";
CM_ SG_ 2565922814 ACSideRMSCur "Present operating AC Side output RMS line Current of this DC/AC Accessory Inverter.  When connected to a balanced three phase motor, this would be the current in each individual phase of the motor.";
CM_ SG_ 2565922814 LoadshedReq "Loadshed Request from this DC/AC Accessory Inverter output.  The Loadshed Requested state is an indication that the inverter output powering this device has a malfunction and is in a limit condition and if the load of the output is not reduced, the ...";
CM_ SG_ 2565922814 StatusFeedback "Operating Status of this DC/AC Accessory Inverter output. The Inverter Output Faulted state will be communicated when the inverter output has shutdown due to an overload condition or other fault.
000b = Output Disabled
001b = Output Enabled
010b ...";
CM_ SG_ 2565922814 PwrFeedback "Present operating AC Side power of this DC/AC Accessory Inverter output.";
CM_ SG_ 2565922814 VFeedback "Present operating AC Side line to line RMS voltage of this DC/AC Accessory Inverter output.  In a three phase balanced motor, this is the RMS voltage across one phase of the motor.";
CM_ SG_ 2565922814 FreqFeedback "Present operating frequency of this DC/AC Accessory Inverter output.";
CM_ BO_ 2565922558 "DC/AC Accessory Inverter 3 Command
Used to command this instance of an DC/AC Accessory Inverter that uses a V/Hz algorithm.  The Inverter may have multiple outputs to power accessories on a vehicle (e.g. HVAC compressor, air compressor, power ...";
CM_ SG_ 2565922558 ACSideMotorStartingRMSVReq "Signal to the DC/AC Accessory Inverter indicating the requested AC side RMS voltage for starting the attached accessory motor.   In a V/Hz variable speed motor control application, this voltage typically may be set to a non-zero value when an ...";
CM_ SG_ 2565922558 EnableCmd "Command to the DC/AC Accessory Inverter to enable this output.  Each output may control multiple devices (e.g. electric motors) if they all operate at the same frequency.
00b = Disable DC/AC Accessory Inverter Output
01b = Enable DC/AC Accessory ...";
CM_ SG_ 2565922558 Device2Status "Signal to the DC/AC Accessory Inverter indicating the state of the device attached to the inverter output.  Each output may control multiple devices (e.g. electric motors) if they all operate at the same frequency.
The Faulted Off state will be ...";
CM_ SG_ 2565922558 Device1Status "Signal to the DC/AC Accessory Inverter indicating the state of the device attached to the inverter output.  Each output may control multiple devices (e.g. electric motors) if they all operate at the same frequency.
The Faulted Off state will be ...";
CM_ SG_ 2565922558 FreqCmd "Command to the DC/AC Accessory Inverter indicating the Inverter frequency desired for the device(s) attached to the inverter output.  Each output may control multiple devices (e.g. electric motors) if they all operate at the same frequency.";
CM_ SG_ 2565922558 DeviceFreqRateOfChangeLmt "Signal to the DC/AC Accessory Inverter indicating the frequency rate of change limit of the device(s) attached to the inverter output (Note: Increasing and decreasing rates can be controlled by the same signal).  Each output may control multiple ...";
CM_ SG_ 2565922558 DeviceRatedV "Signal to the DC/AC Accessory Inverter indicating the rated RMS voltage of the device(s) attached to the inverter output.   Each output may control multiple devices (e.g. electric motors) if they all operate at the same frequency.";
CM_ SG_ 2565922558 DeviceRatedFreq "Signal to the DC/AC Accessory Inverter indicating the rated frequency of the device(s) attached to the inverter output.  Each output may control multiple devices (e.g. electric motors) if they all operate at the same frequency.";
CM_ SG_ 2565922558 DeviceMinFreq "Signal to the DC/AC Accessory Inverter indicating the minimum frequency of the device(s) attached to the inverter output.  Each output may control multiple devices (e.g. electric motors) if they all operate at the same frequency.";
CM_ SG_ 2565922558 DeviceMaxFreq "Signal to the DC/AC Accessory Inverter indicating the maximum frequency of the devices(s) attached to the inverter output.  Each output may control multiple devices (e.g. electric motors) if they all operate at the same frequency.";
CM_ BO_ 2565921790 "DC/AC Accessory Inverter 2 Feedback
Sent by this DC/AC Accessory Inverter instance and contains the current operating conditions of this output of the inverter.  This message would be received by a controller application (e.g. Power System Manager) ...";
CM_ SG_ 2565921790 HVILStatus "High Voltage Interlock Loop (HVIL) state of the DC/AC Accessory Inverter 2.

00b = HVIL Closed
01b = HVIL Open
10b = Error
11b = Not Available";
CM_ SG_ 2565921790 ACSideRMSCur "Present operating AC Side output RMS line Current of this DC/AC Accessory Inverter.  When connected to a balanced three phase motor, this would be the current in each individual phase of the motor.";
CM_ SG_ 2565921790 LoadshedReq "Loadshed Request from this DC/AC Accessory Inverter output.  The Loadshed Requested state is an indication that the inverter output powering this device has a malfunction and is in a limit condition and if the load of the output is not reduced, the ...";
CM_ SG_ 2565921790 StatusFeedback "Operating Status of this DC/AC Accessory Inverter output. The Inverter Output Faulted state will be communicated when the inverter output has shutdown due to an overload condition or other fault.
000b = Output Disabled
001b = Output Enabled
010b ...";
CM_ SG_ 2565921790 PwrFeedback "Present operating AC Side power of this DC/AC Accessory Inverter output.";
CM_ SG_ 2565921790 VFeedback "Present operating AC Side line to line RMS voltage of this DC/AC Accessory Inverter output.  In a three phase balanced motor, this is the RMS voltage across one phase of the motor.";
CM_ SG_ 2565921790 FreqFeedback "Present operating frequency of this DC/AC Accessory Inverter output.";
CM_ BO_ 2565921534 "DC/AC Accessory Inverter 2 Command
Used to command this instance of an DC/AC Accessory Inverter that uses a V/Hz algorithm.  The Inverter may have multiple outputs to power accessories on a vehicle (e.g. HVAC compressor, air compressor, power ...";
CM_ SG_ 2565921534 ACSideMotorStartingRMSVReq "Signal to the DC/AC Accessory Inverter indicating the requested AC side RMS voltage for starting the attached accessory motor.   In a V/Hz variable speed motor control application, this voltage typically may be set to a non-zero value when an ...";
CM_ SG_ 2565921534 EnableCmd "Command to the DC/AC Accessory Inverter to enable this output.  Each output may control multiple devices (e.g. electric motors) if they all operate at the same frequency.
00b = Disable DC/AC Accessory Inverter Output
01b = Enable DC/AC Accessory ...";
CM_ SG_ 2565921534 Device2Status "Signal to the DC/AC Accessory Inverter indicating the state of the device attached to the inverter output.  Each output may control multiple devices (e.g. electric motors) if they all operate at the same frequency.
The Faulted Off state will be ...";
CM_ SG_ 2565921534 Device1Status "Signal to the DC/AC Accessory Inverter indicating the state of the device attached to the inverter output.  Each output may control multiple devices (e.g. electric motors) if they all operate at the same frequency.
The Faulted Off state will be ...";
CM_ SG_ 2565921534 FreqCmd "Command to the DC/AC Accessory Inverter indicating the Inverter frequency desired for the device(s) attached to the inverter output.  Each output may control multiple devices (e.g. electric motors) if they all operate at the same frequency.";
CM_ SG_ 2565921534 DeviceFreqRateOfChangeLmt "Signal to the DC/AC Accessory Inverter indicating the frequency rate of change limit of the device(s) attached to the inverter output (Note: Increasing and decreasing rates can be controlled by the same signal).  Each output may control multiple ...";
CM_ SG_ 2565921534 DeviceRatedV "Signal to the DC/AC Accessory Inverter indicating the rated RMS voltage of the device(s) attached to the inverter output.   Each output may control multiple devices (e.g. electric motors) if they all operate at the same frequency.";
CM_ SG_ 2565921534 DeviceRatedFreq "Signal to the DC/AC Accessory Inverter indicating the rated frequency of the device(s) attached to the inverter output.  Each output may control multiple devices (e.g. electric motors) if they all operate at the same frequency.";
CM_ SG_ 2565921534 DeviceMinFreq "Signal to the DC/AC Accessory Inverter indicating the minimum frequency of the device(s) attached to the inverter output.  Each output may control multiple devices (e.g. electric motors) if they all operate at the same frequency.";
CM_ SG_ 2565921534 DeviceMaxFreq "Signal to the DC/AC Accessory Inverter indicating the maximum frequency of the devices(s) attached to the inverter output.  Each output may control multiple devices (e.g. electric motors) if they all operate at the same frequency.";
CM_ BO_ 2565920766 "DC/AC Accessory Inverter 1 Feedback
Sent by this DC/AC Accessory Inverter instance and contains the current operating conditions of this output of the inverter.  This message would be received by a controller application (e.g. Power System Manager) ...";
CM_ SG_ 2565920766 HVILStatus "High Voltage Interlock Loop (HVIL) state of the DC/AC Accessory Inverter 1.

00b = HVIL Closed
01b = HVIL Open
10b = Error
11b = Not Available";
CM_ SG_ 2565920766 ACSideRMSCur "Present operating AC Side output RMS line Current of this DC/AC Accessory Inverter.  When connected to a balanced three phase motor, this would be the current in each individual phase of the motor.";
CM_ SG_ 2565920766 LoadshedReq "Loadshed Request from this DC/AC Accessory Inverter output.  The Loadshed Requested state is an indication that the inverter output powering this device has a malfunction and is in a limit condition and if the load of the output is not reduced, the ...";
CM_ SG_ 2565920766 StatusFeedback "Operating Status of this DC/AC Accessory Inverter output. The Inverter Output Faulted state will be communicated when the inverter output has shutdown due to an overload condition or other fault.
000b = Output Disabled
001b = Output Enabled
010b ...";
CM_ SG_ 2565920766 PwrFeedback "Present operating AC Side power of this DC/AC Accessory Inverter output.";
CM_ SG_ 2565920766 VFeedback "Present operating AC Side line to line RMS voltage of this DC/AC Accessory Inverter output.  In a three phase balanced motor, this is the RMS voltage across one phase of the motor.";
CM_ SG_ 2565920766 FreqFeedback "Present operating frequency of this DC/AC Accessory Inverter output.";
CM_ BO_ 2565920510 "DC/AC Accessory Inverter 1 Command
Used to command this instance of an DC/AC Accessory Inverter that uses a V/Hz algorithm.  The Inverter may have multiple outputs to power accessories on a vehicle (e.g. HVAC compressor, air compressor, power ...";
CM_ SG_ 2565920510 ACSideMotorStartingRMSVReq "Signal to the DC/AC Accessory Inverter indicating the requested AC side RMS voltage for starting the attached accessory motor.   In a V/Hz variable speed motor control application, this voltage typically may be set to a non-zero value when an ...";
CM_ SG_ 2565920510 EnableCmd "Command to the DC/AC Accessory Inverter to enable this output.  Each output may control multiple devices (e.g. electric motors) if they all operate at the same frequency.
00b = Disable DC/AC Accessory Inverter Output
01b = Enable DC/AC Accessory ...";
CM_ SG_ 2565920510 Device2Status "Signal to the DC/AC Accessory Inverter indicating the state of the device attached to the inverter output.  Each output may control multiple devices (e.g. electric motors) if they all operate at the same frequency.
The Faulted Off state will be ...";
CM_ SG_ 2565920510 Device1Status "Signal to the DC/AC Accessory Inverter indicating the state of the device attached to the inverter output.  Each output may control multiple devices (e.g. electric motors) if they all operate at the same frequency.
The Faulted Off state will be ...";
CM_ SG_ 2565920510 FreqCmd "Command to the DC/AC Accessory Inverter indicating the Inverter frequency desired for the device(s) attached to the inverter output.  Each output may control multiple devices (e.g. electric motors) if they all operate at the same frequency.";
CM_ SG_ 2565920510 DeviceFreqRateOfChangeLmt "Signal to the DC/AC Accessory Inverter indicating the frequency rate of change limit of the device(s) attached to the inverter output (Note: Increasing and decreasing rates can be controlled by the same signal).  Each output may control multiple ...";
CM_ SG_ 2565920510 DeviceRatedV "Signal to the DC/AC Accessory Inverter indicating the rated RMS voltage of the device(s) attached to the inverter output.   Each output may control multiple devices (e.g. electric motors) if they all operate at the same frequency.";
CM_ SG_ 2565920510 DeviceRatedFreq "Signal to the DC/AC Accessory Inverter indicating the rated frequency of the device(s) attached to the inverter output.  Each output may control multiple devices (e.g. electric motors) if they all operate at the same frequency.";
CM_ SG_ 2565920510 DeviceMinFreq "Signal to the DC/AC Accessory Inverter indicating the minimum frequency of the device(s) attached to the inverter output.  Each output may control multiple devices (e.g. electric motors) if they all operate at the same frequency.";
CM_ SG_ 2565920510 DeviceMaxFreq "Signal to the DC/AC Accessory Inverter indicating the maximum frequency of the devices(s) attached to the inverter output.  Each output may control multiple devices (e.g. electric motors) if they all operate at the same frequency.";
CM_ BO_ 2364580094 "High Voltage Energy Storage System Data 7
Data set 7 (electrical) for High Voltage Energy Storage System (or Pack 1 in systems with only one pack).";
CM_ SG_ 2364580094 MaxChargeVLmt "The maximum voltage level not to be exceeded while charging the High Voltage Energy Storage System (or Pack 1 in systems with only one pack).  If this parameter is not supported, the maximum charge voltage should be limited to SPN 8117 (HVESS ...";
CM_ SG_ 2364580094 ChargeEnergyCapacity "The amount of unused electrical energy storage available to be filled by charging High Voltage Energy Storage System (or Pack 1 in systems with only one pack), i.e. “how much empty space is remaining in the tank”. See SPN 8080 (HVESS Charge ...";
CM_ SG_ 2364580094 DisEnergyCapacity "The amount of stored electrical energy in High Voltage Energy Storage System (or Pack 1 in systems with only one pack) that is available for use by the hybrid system, i.e. “how full is the tank”. See SPN 8079 (HVESS Discharge Capacity) for ...";
CM_ BO_ 2364577534 "High Voltage Energy Storage System Status 1
Status data set 1 for High Voltage Energy Storage System (or Pack 1 in systems with only one pack).";
CM_ SG_ 2364577534 Status1CRC "The CRC is defined as follows:
• Length: 8 bits
• Polynomial: x^8+x^5+x^3+x^2+x+1
• Initial Value: FFh
• Input Data Reflection: Not reflected
• Result Data Reflection: Not reflected
• XOR value: FFh
SAE makes no claim of the functional safety ...";
CM_ SG_ 2364577534 NumOfHVESPsReady "The number of High Voltage Energy Storage Packs that are currently ready to provide high voltage energy or are actively providing high voltage energy in the HVESS system. This parameter will increment after contactors are closed.";
CM_ SG_ 2364577534 Status1Counter "The message counter is used to detect situations where the transmitting ECU malfunction repeats the same frame all the time. The receiver of the information may use the counter parameter to detect this situation. The transmitting device will ...";
CM_ SG_ 2364577534 OperationalStatus "Provides feedback on where the High Voltage Energy Storage System (or Pack 1 in systems with only one pack) is in its operating spectrum, and includes feedback in response to the Operation Consent [i.e. SPN 8412 (HVESS Operation Consent)] and Power ...";
CM_ SG_ 2364577534 HVBusConnectionStatus "This parameter provides high level feedback on the High Voltage Energy Storage System (or Pack 1 in systems with only one pack) high voltage bus connection.  For specific contactor information, see SPN 8091 (HVESS High-Voltage Bus (Positive) ...";
CM_ SG_ 2364577534 InternalChargerStatus "Indicates that the charger in this HVES instance is on.  External chargers may use the External Energy Source Connection Status (SPN 7898) and related SPs.
This parameter provides HVES system level information. If there are multiple packs in the ...";
CM_ SG_ 2364577534 CellBalancingActive "Indicates whether or not the cells in the High Voltage Energy Storage System (or Pack 1 in systems with only one pack) are currently being balanced.
This parameter provides HVES system level information. If there are multiple packs in the system, ...";
CM_ SG_ 2364577534 CellBalanceStatus "Indicates whether or not the cells in the High Voltage Energy Storage System (or Pack 1 in systems with only one pack) are balanced.
This parameter provides HVES system level information. If there are multiple packs in the system, then both ...";
CM_ SG_ 2364577534 StOfChargeStatus "Status of the High Voltage Energy Storage System (or Pack 1 in systems with only one pack) State of Charge (SOC).  Note:  A given HVES controller may not support all of the states.
This parameter provides HVES system level information. If there are ...";
CM_ SG_ 2364577534 InertiaSwStatus "Switch indicating that an impact has been sensed by the High Voltage Energy Storage System (or Pack 1 in systems with only one pack). The impact indication may require action by another controller, or by this HVES instance itself.  For example, a ...";
CM_ SG_ 2364577534 HVILStatus "Status of the High Voltage Interlock Loop from the viewpoint of the High Voltage Energy Storage System (or Pack 1 in systems with only one pack).
This parameter provides HVES system level information. If there are multiple packs in the system, then ...";
CM_ SG_ 2364577534 HVBusPassiveIsolTestStatus "Status of the high-voltage bus electrical passive isolation test as performed by the High Voltage Energy Storage System (or Pack 1 in systems with only one pack).
This parameter provides HVES system level information. If there are multiple packs in ...";
CM_ SG_ 2364577534 HVBusActiveIsolTestStatus "Status of the high-voltage bus electrical active isolation test as performed by the High Voltage Energy Storage System (or Pack 1 in systems with only one pack).
This parameter provides HVES system level information. If there are multiple packs in ...";
CM_ SG_ 2364577534 CenterOfPackContactorSt "Position of the center high-voltage contactor.  When this contactor is closed, the positive half of the High Voltage Energy Storage System (or Pack 1 in systems with only one pack) is connected to the negative half.  If a system controls the ...";
CM_ SG_ 2364577534 HVBusPreChargeRelaySt "Position of the high-voltage bus contactor pre-charge relay.  When this relay is closed, the High Voltage Energy Storage System (or Pack 1 in systems with only one pack) is bringing the high-voltage bus up to its operating level.
This parameter ...";
CM_ SG_ 2364577534 HVBusDisconnectForewarning "Indicates that the High Voltage Energy Storage System (or Pack 1 in systems with only one pack) is about to disconnect from the high voltage bus due to unacceptable conditions.
This parameter provides HVES system level information. If there are ...";
CM_ SG_ 2364577534 HVBusContactorSt8092 "Position of the High Voltage Energy Storage System (or Pack 1 in systems with only one pack) negative side bus contactor.  When this contactor is closed, the negative side of this HVES instance is connected to the negative side of the high-voltage ...";
CM_ SG_ 2364577534 HVBusContactorSt "Position of the High Voltage Energy Storage System (or Pack 1 in systems with only one pack) positive side bus contactor.  When this contactor is closed, the positive side of this HVES instance is connected to the positive side of the high-voltage ...";
CM_ BO_ 2364577278 "High Voltage Energy Storage System Data 6
Data set 6 (external or interface data) for High Voltage Energy Storage System (or Pack 1 in systems with only one pack).";
CM_ SG_ 2364577278 Temp "The temperature of High Voltage Energy Storage System (or Pack 1 in systems with only one pack). The value may be determined from a unique sensor specifically for this purpose, or by aggregating various temperature sensor readings within the system.
 ...";
CM_ SG_ 2364577278 ETemp "The temperature of the electronics or control modules in the High Voltage Energy Storage System (or Pack 1 in systems with only one pack).  If there are multiple temperature sensors then this parameter would be set to the maximum sensor reading.
 ...";
CM_ SG_ 2364577278 OutCoolantTemp "The temperature of liquid coolant as it exits the High Voltage Energy Storage System (or Pack 1 in systems with only one pack).
This parameter provides HVES system level information. If there are multiple packs in the system, then both individual ...";
CM_ SG_ 2364577278 InCoolantTemp "The temperature of liquid coolant as it enters the High Voltage Energy Storage System (or Pack 1 in systems with only one pack).
This parameter provides HVES system level information. If there are multiple packs in the system, then both individual ...";
CM_ SG_ 2364577278 IgntV "The voltage level at the ignition input of the High Voltage Energy Storage System (or Pack 1 in systems with only one pack) controller.
This parameter provides HVES system level information. If there are multiple packs in the system, then both ...";
CM_ SG_ 2364577278 BusV "The voltage level of the high voltage bus, as measured by the High Voltage Energy Storage System (or Pack 1 in systems with only one pack) on the bus side (not the battery side) of its contactors.
This parameter provides HVES system level ...";
CM_ BO_ 2364577022 "High Voltage Energy Storage System Data 5
Data set 5 (electrical data) for High Voltage Energy Storage System (or Pack 1 in systems with only one pack).";
CM_ SG_ 2364577022 MaxCellStOfCharge "Indicates the state of charge of the highest-charged cell in the High Voltage Energy Storage System (or Pack 1 in systems with only one pack).  0% means no charge remaining, 100% means the cell is fully charged.  If a single state of charge value ...";
CM_ SG_ 2364577022 MinCellStOfCharge "Indicates the state of charge of the lowest-charged cell in the High Voltage Energy Storage System (or Pack 1 in systems with only one pack).  0% means no charge remaining, 100% means the cell is fully charged.   If a single state of charge value ...";
CM_ SG_ 2364577022 ChargeCurLmt "The maximum instantaneous current flow limit into the High Voltage Energy Storage System (or Pack 1 in systems with only one pack). This parameter is defined from the high voltage energy storage system's point of view and should reflect the ...";
CM_ SG_ 2364577022 DisCurLmt "The maximum instantaneous current flow limit out of the High Voltage Energy Storage System (or Pack 1 in systems with only one pack). This parameter is defined from the high voltage energy storage system's point of view and should reflect the ...";
CM_ BO_ 2364576766 "High Voltage Energy Storage System Data 4
Data set 4 (electrical data) for High Voltage Energy Storage System (or Pack 1 in systems with only one pack).";
CM_ SG_ 2364576766 CellBalancingCount "The number of cells that are currently being balanced in the High Voltage Energy Storage System (or Pack 1 in systems with only one pack).
This parameter provides HVES system level information. If there are multiple packs in the system, then both ...";
CM_ SG_ 2364576766 ChargeCapacity "The amount of unused electrical charge storage in the High Voltage Energy Storage System (or Pack 1 in systems with only one pack) that is available to be filled by charging, i.e. “how much empty space is remaining in the tank”. See SPN 8206 (HVESS ...";
CM_ SG_ 2364576766 DisCapacity "The amount of stored electrical charge in the High Voltage Energy Storage System (or Pack 1 in systems with only one pack) that is available for use by the hybrid system, i.e. “how full is the tank”. See SPN 8205 (HVESS Discharge Energy Capacity) ...";
CM_ BO_ 2364576510 "High Voltage Energy Storage System Data 3
Data set 3 (thermal data) for High Voltage Energy Storage System (or Pack 1 in systems with only one pack).";
CM_ SG_ 2364576510 CellTempDiffStatus "Indicates whether or not the differential between the highest and lowest cell temperatures are within acceptable limits per the High Voltage Energy Storage System (or Pack 1 in systems with only one pack).  The actual temperature differential can be ...";
CM_ SG_ 2364576510 AvgCellTemp "The average temperature level of all cells in the High Voltage Energy Storage System (or Pack 1 in systems with only one pack).
This parameter provides HVES system level information. If there are multiple packs in the system, then both individual ...";
CM_ SG_ 2364576510 LowestCellTemp "The lowest temperature level reported by any cell in the High Voltage Energy Storage System (or Pack 1 in systems with only one pack).  If a single temperature sensor covers more than one cell, the value in this parameter is for the smallest group ...";
CM_ SG_ 2364576510 HighestCellTemp "The highest temperature level reported by any cell in the High Voltage Energy Storage System (or Pack 1 in systems with only one pack).  If a single temperature sensor covers more than one cell, the value in this parameter is for the smallest group ...";
CM_ BO_ 2364576254 "High Voltage Energy Storage System Data 2
Data set 2 (electrical data) for High Voltage Energy Storage System (or Pack 1 in systems with only one pack).";
CM_ SG_ 2364576254 CellVDiffStatus "Indicates whether or not the differential between the highest and lowest cell voltages are within acceptable limits, according to the High Voltage Energy Storage System (or Pack 1 in systems with only one pack).   The actual voltage differential can ...";
CM_ SG_ 2364576254 LowestCellV "The lowest voltage level reported by any cell in the High Voltage Energy Storage System (or Pack 1 in systems with only one pack). If a single voltage sensor covers more than one cell, the value in this parameter is for the smallest group of cells ...";
CM_ SG_ 2364576254 HighestCellV "The highest voltage level reported by any cell in the High Voltage Energy Storage System (or Pack 1 in systems with only one pack). If a single voltage sensor covers more than one cell, the value in this parameter is for the smallest group of cells ...";
CM_ SG_ 2364576254 FastUpdateStOfCharge "Indicates the High Voltage Energy Storage System (or Pack 1 in systems with only one pack) state of charge. 0% means no charge remaining, 100% means the system is fully charged in terms of physical limits of the energy storage system. Acceptable ...";
CM_ BO_ 2364575998 "High Voltage Energy Storage System Data 1
Data set 1 (electrical data) for High Voltage Energy Storage System (or Pack 1 in systems with only one pack).";
CM_ SG_ 2364575998 Cur "The current in or out of the High Voltage Energy Storage System (or Pack 1 in systems with only one pack). This parameter should be synchronized with SPN 5919 (HVESS Voltage Level) such that a realized power value can be calculated.  This parameter ...";
CM_ SG_ 2364575998 Lvl "The voltage level of the High Voltage Energy Storage System (or Pack 1 in systems with only one pack). This parameter should be synchronized with SPN 5920 (HVESS Current) such that a realized power value can be calculated.  If the HVES component ...";
CM_ SG_ 2364575998 AvailableChargePwr "The rate at which the High Voltage Energy Storage System (or Pack 1 in systems with only one pack) can currently receive energy from a regenerative or recharging system.
This parameter provides HVES system level information. If there are multiple ...";
CM_ SG_ 2364575998 AvailableDisPwr "The rate at which the High Voltage Energy Storage System (or Pack 1 in systems with only one pack) can currently provide energy for propulsion or other uses.
This parameter provides HVES system level information. If there are multiple packs in the ...";
CM_ BO_ 2364552958 "High Voltage Energy Storage System Status 2
Status data set 2 for High Voltage Energy Storage System (or Pack 1 in systems with only one pack).";
CM_ SG_ 2364552958 ChargePLDueToPwrModuleETemp "Indicates whether or not output charge power is being limited due to Power Module Electronics Temperature (see SPN 22822 (HVESS Power Module Electronics Temperature)) approaching or exceeding the maximum limit.
00b = No power limit for this reason
 ...";
CM_ SG_ 2364552958 DisPLDueToPwrModuleETemp "Indicates whether or not output discharge power is being limited due to Power Module Electronics Temperature (see SPN 22822 (HVESS Power Module Electronics Temperature)) approaching or exceeding the maximum limit.
00b = No power limit for this ...";
CM_ SG_ 2364552958 ChargePLDueToAnUndefinedCause "Indicates whether or not charge power of this HVES instance is being limited due to an undefined cause.
This parameter provides HVES system level information. If there are multiple packs in the system, then both individual pack messages (e.g ...";
CM_ SG_ 2364552958 ChargePLDueToBatCur "Indicates whether or not charge power of this HVES instance is being limited due to battery current.
This parameter provides HVES system level information. If there are multiple packs in the system, then both individual pack messages (e.g. HVESP1, ...";
CM_ SG_ 2364552958 ChargePLDueToBatOrCellV "Indicates whether or not charge power of this HVES instance is being limited due to a battery or cell voltage level.
This parameter provides HVES system level information. If there are multiple packs in the system, then both individual pack ...";
CM_ SG_ 2364552958 ChargePLDueToBatDiagCondition "Indicates whether or not charge power of this HVES instance is being limited due to a battery diagnostic condition.
This parameter provides HVES system level information. If there are multiple packs in the system, then both individual pack messages ...";
CM_ SG_ 2364552958 ChargePLDueToBatTemp "Indicates whether or not charge power of this HVES instance is being limited due to battery temperature.
This parameter provides HVES system level information. If there are multiple packs in the system, then both individual pack messages (e.g ...";
CM_ SG_ 2364552958 ChargePLDueToStOfCharge "Indicates whether or not charge power of this HVES instance is being limited due to state of charge.
This parameter provides HVES system level information. If there are multiple packs in the system, then both individual pack messages (e.g. HVESP1, ...";
CM_ SG_ 2364552958 DisPLDueToAnUndefinedCause "Indicates whether or not discharge power of this HVES instance is being limited due to an undefined cause.
This parameter provides HVES system level information. If there are multiple packs in the system, then both individual pack messages (e.g ...";
CM_ SG_ 2364552958 DisPLDueToBatCur "Indicates whether or not discharge power of this HVES instance is being limited due to battery current.
This parameter provides HVES system level information. If there are multiple packs in the system, then both individual pack messages (e.g ...";
CM_ SG_ 2364552958 DisPLDueToBatOrCellV "Indicates whether or not discharge power of this HVES instance is being limited due to a battery or cell voltage level.
This parameter provides HVES system level information. If there are multiple packs in the system, then both individual pack ...";
CM_ SG_ 2364552958 DisPLDueToBatDiagCondition "Indicates whether or not discharge power of this HVES instance is being limited due to a battery diagnostic condition.
This parameter provides HVES system level information. If there are multiple packs in the system, then both individual pack ...";
CM_ SG_ 2364552958 DisPLDueToBatTemp "Indicates whether or not discharge power of this HVES instance is being limited due to battery temperature.
This parameter provides HVES system level information. If there are multiple packs in the system, then both individual pack messages (e.g ...";
CM_ SG_ 2364552958 DisPLDueToStOfCharge "Indicates whether or not discharge power of this HVES instance is being limited due to state of charge.
This parameter provides HVES system level information. If there are multiple packs in the system, then both individual pack messages (e.g ...";
CM_ BO_ 2558459646 "Engine Speed Ramp Rate Boundary Request
Message is sent to a device to control engine speed ramp rate acceleration and deceleration boundaries (eg TSC1).";
CM_ SG_ 2558459646 ReqEngSpdDecelerationRateLmt "This parameter is intended to be received by a device sending speed commands to an engine (e.g. TSC1 or proprietary command). The sending device should issue speed commands such that this deceleration rate is not exceeded.
A value of FB00h ...";
CM_ SG_ 2558459646 ReqEngSpdAccelerationRateLmt "This parameter is intended to be received by a device sending speed commands to an engine (e.g. TSC1 or proprietary command). The sending device should issue speed commands such that this acceleration rate is not exceeded.
A value of FB00h ...";
BA_DEF_ SG_  "GenSigInactiveValue" INT 0 0;
BA_DEF_ SG_  "SigType" ENUM  "Default","Range","RangeSigned","ASCII","Discrete","Control","ReferencePGN","DTC","StringDelimiter","StringLength","StringLengthControl","MessageCounter","MessageChecksum";
BA_DEF_ SG_  "GenSigStartValue" INT 0 2147483647;
BA_DEF_ SG_  "GenSigSendType" ENUM  "Cyclic","OnWrite","OnWriteWithRepetition","OnChange","OnChangeWithRepetition","IfActive","IfActiveWithRepetition","NoSigSendType";
BA_DEF_ SG_  "GenSigILSupport" ENUM  "No","Yes";
BA_DEF_ SG_  "SPN" INT 0 524287;
BA_DEF_ BO_  "J1939CPgSendTimeout" INT -1 3600000;
BA_DEF_ BO_  "J1939CPgTOS" INT 0 7;
BA_DEF_ BO_  "J1939PgAppearanceOnBus" ENUM  "Default","CAN_Extended","CANFD_Extended";
BA_DEF_ BO_  "FsJ1939UseCrcAndCounter" STRING ;
BA_DEF_ BO_  "TpJ1939VarDlc" ENUM  "No","Yes";
BA_DEF_ BO_  "GenMsgNrOfRepetition" INT 0 1000000;
BA_DEF_ BO_  "GenMsgCycleTimeFast" INT 0 3600000;
BA_DEF_ BO_  "GenMsgFastOnStart" INT 0 100000;
BA_DEF_ BO_  "GenMsgStartDelayTime" INT 0 100000;
BA_DEF_ BO_  "GenMsgILSupport" ENUM  "No","Yes";
BA_DEF_ BO_  "GenMsgDelayTime" INT 0 1000;
BA_DEF_ BO_  "GenMsgRequestable" INT 0 1;
BA_DEF_ BO_  "GenMsgSendType" ENUM  "cyclic","NotUsed","NotUsed","NotUsed","NotUsed","NotUsed","NotUsed","IfActive","noMsgSendType";
BA_DEF_ BO_  "VFrameFormat" ENUM  "StandardCAN","ExtendedCAN","reserved","J1939PG","reserved","reserved","reserved","reserved","reserved","reserved","reserved","reserved","reserved","reserved","StandardCAN_FD","ExtendedCAN_FD";
BA_DEF_ BO_  "SingleFrame" INT 0 1;
BA_DEF_ BO_  "GenMsgCycleTime" INT 0 3600000;
BA_DEF_ SG_  "SystemSignalLongSymbol" STRING ;
BA_DEF_DEF_  "GenSigInactiveValue" 0;
BA_DEF_DEF_  "SigType" "Default";
BA_DEF_DEF_  "GenSigStartValue" 0;
BA_DEF_DEF_  "GenSigSendType" "NoSigSendType";
BA_DEF_DEF_  "GenSigILSupport" "Yes";
BA_DEF_DEF_  "SPN" 0;
BA_DEF_DEF_  "J1939CPgSendTimeout" -1;
BA_DEF_DEF_  "J1939CPgTOS" 2;
BA_DEF_DEF_  "J1939PgAppearanceOnBus" "Default";
BA_DEF_DEF_  "FsJ1939UseCrcAndCounter" "";
BA_DEF_DEF_  "TpJ1939VarDlc" "No";
BA_DEF_DEF_  "GenMsgNrOfRepetition" 0;
BA_DEF_DEF_  "GenMsgCycleTimeFast" 0;
BA_DEF_DEF_  "GenMsgFastOnStart" 0;
BA_DEF_DEF_  "GenMsgStartDelayTime" 0;
BA_DEF_DEF_  "GenMsgILSupport" "Yes";
BA_DEF_DEF_  "GenMsgDelayTime" 0;
BA_DEF_DEF_  "GenMsgRequestable" 1;
BA_DEF_DEF_  "GenMsgSendType" "noMsgSendType";
BA_DEF_DEF_  "VFrameFormat" "J1939PG";
BA_DEF_DEF_  "SingleFrame" 1;
BA_DEF_DEF_  "GenMsgCycleTime" 0;
BA_DEF_DEF_  "SystemSignalLongSymbol" "";
BA_ "GenMsgDelayTime" BO_ 2566642942 100;
BA_ "GenMsgSendType" BO_ 2566642942 0;
BA_ "GenMsgCycleTime" BO_ 2566642942 1000;
BA_ "GenMsgSendType" BO_ 2365315838 0;
BA_ "GenMsgCycleTime" BO_ 2365315838 1000;
BA_ "GenMsgSendType" BO_ 2365315582 0;
BA_ "GenMsgCycleTime" BO_ 2365315582 1000;
BA_ "GenMsgSendType" BO_ 2365315326 0;
BA_ "GenMsgCycleTime" BO_ 2365315326 1000;
BA_ "TpJ1939VarDlc" BO_ 2633750526 1;
BA_ "GenMsgSendType" BO_ 2566641406 0;
BA_ "GenMsgCycleTime" BO_ 2566641406 100;
BA_ "GenMsgSendType" BO_ 2566641150 0;
BA_ "GenMsgCycleTime" BO_ 2566641150 1000;
BA_ "GenMsgSendType" BO_ 2431719166 0;
BA_ "GenMsgCycleTime" BO_ 2431719166 50;
BA_ "GenMsgSendType" BO_ 2364610046 0;
BA_ "GenMsgCycleTime" BO_ 2364610046 100;
BA_ "GenMsgSendType" BO_ 2364609790 0;
BA_ "GenMsgCycleTime" BO_ 2364609790 100;
BA_ "FsJ1939UseCrcAndCounter" BO_ 2364609534 "Aa";
BA_ "GenMsgSendType" BO_ 2364609534 0;
BA_ "GenMsgCycleTime" BO_ 2364609534 100;
BA_ "FsJ1939UseCrcAndCounter" BO_ 2364609278 "Ae";
BA_ "GenMsgSendType" BO_ 2364609278 0;
BA_ "GenMsgCycleTime" BO_ 2364609278 100;
BA_ "GenMsgSendType" BO_ 2431717886 0;
BA_ "GenMsgCycleTime" BO_ 2431717886 100;
BA_ "GenMsgDelayTime" BO_ 2297499902 20;
BA_ "GenMsgSendType" BO_ 2297499902 0;
BA_ "GenMsgCycleTime" BO_ 2297499902 1000;
BA_ "GenMsgDelayTime" BO_ 2364608510 10;
BA_ "GenMsgSendType" BO_ 2364608510 0;
BA_ "GenMsgCycleTime" BO_ 2364608510 100;
BA_ "GenMsgSendType" BO_ 2498825982 0;
BA_ "GenMsgCycleTime" BO_ 2498825982 50;
BA_ "GenMsgSendType" BO_ 2565934590 0;
BA_ "GenMsgCycleTime" BO_ 2565934590 100;
BA_ "GenMsgSendType" BO_ 2364607742 0;
BA_ "GenMsgCycleTime" BO_ 2364607742 100;
BA_ "FsJ1939UseCrcAndCounter" BO_ 2364607486 "Aa";
BA_ "GenMsgSendType" BO_ 2364607486 0;
BA_ "GenMsgCycleTime" BO_ 2364607486 100;
BA_ "GenMsgSendType" BO_ 2364607230 0;
BA_ "GenMsgCycleTime" BO_ 2364607230 100;
BA_ "GenMsgSendType" BO_ 2364606974 0;
BA_ "GenMsgCycleTime" BO_ 2364606974 100;
BA_ "GenMsgSendType" BO_ 2364606718 0;
BA_ "GenMsgCycleTime" BO_ 2364606718 100;
BA_ "GenMsgSendType" BO_ 2565933054 0;
BA_ "GenMsgCycleTime" BO_ 2565933054 50;
BA_ "GenMsgSendType" BO_ 2565932798 0;
BA_ "GenMsgCycleTime" BO_ 2565932798 50;
BA_ "GenMsgSendType" BO_ 2364605950 0;
BA_ "GenMsgCycleTime" BO_ 2364605950 20;
BA_ "GenMsgSendType" BO_ 2364605438 0;
BA_ "GenMsgCycleTime" BO_ 2364605438 100;
BA_ "GenMsgSendType" BO_ 2364605182 0;
BA_ "GenMsgCycleTime" BO_ 2364605182 100;
BA_ "GenMsgSendType" BO_ 2364604926 0;
BA_ "GenMsgCycleTime" BO_ 2364604926 100;
BA_ "GenMsgSendType" BO_ 2364604670 0;
BA_ "GenMsgCycleTime" BO_ 2364604670 100;
BA_ "GenMsgSendType" BO_ 2364604414 0;
BA_ "GenMsgCycleTime" BO_ 2364604414 100;
BA_ "GenMsgSendType" BO_ 2364604158 0;
BA_ "GenMsgCycleTime" BO_ 2364604158 50;
BA_ "GenMsgSendType" BO_ 2364603902 0;
BA_ "GenMsgCycleTime" BO_ 2364603902 50;
BA_ "GenMsgSendType" BO_ 2364603646 0;
BA_ "GenMsgCycleTime" BO_ 2364603646 50;
BA_ "GenMsgSendType" BO_ 2364603390 0;
BA_ "GenMsgCycleTime" BO_ 2364603390 50;
BA_ "GenMsgSendType" BO_ 2364603134 0;
BA_ "GenMsgCycleTime" BO_ 2364603134 100;
BA_ "GenMsgSendType" BO_ 2364602878 0;
BA_ "GenMsgCycleTime" BO_ 2364602878 100;
BA_ "GenMsgSendType" BO_ 2565923838 0;
BA_ "GenMsgCycleTime" BO_ 2565923838 100;
BA_ "GenMsgSendType" BO_ 2565923582 0;
BA_ "GenMsgCycleTime" BO_ 2565923582 100;
BA_ "GenMsgSendType" BO_ 2565922814 0;
BA_ "GenMsgCycleTime" BO_ 2565922814 100;
BA_ "GenMsgSendType" BO_ 2565922558 0;
BA_ "GenMsgCycleTime" BO_ 2565922558 100;
BA_ "GenMsgSendType" BO_ 2565921790 0;
BA_ "GenMsgCycleTime" BO_ 2565921790 100;
BA_ "GenMsgSendType" BO_ 2565921534 0;
BA_ "GenMsgCycleTime" BO_ 2565921534 100;
BA_ "GenMsgSendType" BO_ 2565920766 0;
BA_ "GenMsgCycleTime" BO_ 2565920766 100;
BA_ "GenMsgSendType" BO_ 2565920510 0;
BA_ "GenMsgCycleTime" BO_ 2565920510 100;
BA_ "GenMsgSendType" BO_ 2364580094 0;
BA_ "GenMsgCycleTime" BO_ 2364580094 100;
BA_ "FsJ1939UseCrcAndCounter" BO_ 2364577534 "Ab";
BA_ "GenMsgDelayTime" BO_ 2364577534 20;
BA_ "GenMsgSendType" BO_ 2364577534 0;
BA_ "GenMsgCycleTime" BO_ 2364577534 100;
BA_ "GenMsgSendType" BO_ 2364577278 0;
BA_ "GenMsgCycleTime" BO_ 2364577278 100;
BA_ "GenMsgSendType" BO_ 2364577022 0;
BA_ "GenMsgCycleTime" BO_ 2364577022 20;
BA_ "GenMsgSendType" BO_ 2364576766 0;
BA_ "GenMsgCycleTime" BO_ 2364576766 100;
BA_ "GenMsgSendType" BO_ 2364576510 0;
BA_ "GenMsgCycleTime" BO_ 2364576510 20;
BA_ "GenMsgSendType" BO_ 2364576254 0;
BA_ "GenMsgCycleTime" BO_ 2364576254 20;
BA_ "GenMsgSendType" BO_ 2364575998 0;
BA_ "GenMsgCycleTime" BO_ 2364575998 20;
BA_ "GenMsgSendType" BO_ 2364552958 0;
BA_ "GenMsgCycleTime" BO_ 2364552958 100;
BA_ "GenMsgDelayTime" BO_ 2558459646 100;
BA_ "GenMsgSendType" BO_ 2558459646 0;
BA_ "GenMsgCycleTime" BO_ 2558459646 10000;
BA_ "SigType" SG_ 2566642942 EnableStatusOfDoor30 5;
BA_ "SPN" SG_ 2566642942 EnableStatusOfDoor30 8554;
BA_ "SigType" SG_ 2566642942 OpenStatusOfDoor30 5;
BA_ "SPN" SG_ 2566642942 OpenStatusOfDoor30 8553;
BA_ "SigType" SG_ 2566642942 LockStatusOfDoor30 5;
BA_ "SPN" SG_ 2566642942 LockStatusOfDoor30 8552;
BA_ "SigType" SG_ 2566642942 EnableStatusOfDoor29 5;
BA_ "SPN" SG_ 2566642942 EnableStatusOfDoor29 8551;
BA_ "SigType" SG_ 2566642942 OpenStatusOfDoor29 5;
BA_ "SPN" SG_ 2566642942 OpenStatusOfDoor29 8550;
BA_ "SigType" SG_ 2566642942 LockStatusOfDoor29 5;
BA_ "SPN" SG_ 2566642942 LockStatusOfDoor29 8549;
BA_ "SigType" SG_ 2566642942 EnableStatusOfDoor28 5;
BA_ "SPN" SG_ 2566642942 EnableStatusOfDoor28 8548;
BA_ "SigType" SG_ 2566642942 OpenStatusOfDoor28 5;
BA_ "SPN" SG_ 2566642942 OpenStatusOfDoor28 8547;
BA_ "SigType" SG_ 2566642942 LockStatusOfDoor28 5;
BA_ "SPN" SG_ 2566642942 LockStatusOfDoor28 8546;
BA_ "SigType" SG_ 2566642942 EnableStatusOfDoor27 5;
BA_ "SPN" SG_ 2566642942 EnableStatusOfDoor27 8545;
BA_ "SigType" SG_ 2566642942 OpenStatusOfDoor27 5;
BA_ "SPN" SG_ 2566642942 OpenStatusOfDoor27 8544;
BA_ "SigType" SG_ 2566642942 LockStatusOfDoor27 5;
BA_ "SPN" SG_ 2566642942 LockStatusOfDoor27 8543;
BA_ "SigType" SG_ 2566642942 EnableStatusOfDoor26 5;
BA_ "SPN" SG_ 2566642942 EnableStatusOfDoor26 8542;
BA_ "SigType" SG_ 2566642942 OpenStatusOfDoor26 5;
BA_ "SPN" SG_ 2566642942 OpenStatusOfDoor26 8541;
BA_ "SigType" SG_ 2566642942 LockStatusOfDoor26 5;
BA_ "SPN" SG_ 2566642942 LockStatusOfDoor26 8540;
BA_ "SigType" SG_ 2566642942 EnableStatusOfDoor25 5;
BA_ "SPN" SG_ 2566642942 EnableStatusOfDoor25 8539;
BA_ "SigType" SG_ 2566642942 OpenStatusOfDoor25 5;
BA_ "SPN" SG_ 2566642942 OpenStatusOfDoor25 8538;
BA_ "SigType" SG_ 2566642942 LockStatusOfDoor25 5;
BA_ "SPN" SG_ 2566642942 LockStatusOfDoor25 8537;
BA_ "SigType" SG_ 2566642942 EnableStatusOfDoor24 5;
BA_ "SPN" SG_ 2566642942 EnableStatusOfDoor24 8536;
BA_ "SigType" SG_ 2566642942 OpenStatusOfDoor24 5;
BA_ "SPN" SG_ 2566642942 OpenStatusOfDoor24 8535;
BA_ "SigType" SG_ 2566642942 LockStatusOfDoor24 5;
BA_ "SPN" SG_ 2566642942 LockStatusOfDoor24 8534;
BA_ "SigType" SG_ 2566642942 EnableStatusOfDoor23 5;
BA_ "SPN" SG_ 2566642942 EnableStatusOfDoor23 8533;
BA_ "SigType" SG_ 2566642942 OpenStatusOfDoor23 5;
BA_ "SPN" SG_ 2566642942 OpenStatusOfDoor23 8532;
BA_ "SigType" SG_ 2566642942 LockStatusOfDoor23 5;
BA_ "SPN" SG_ 2566642942 LockStatusOfDoor23 8531;
BA_ "SigType" SG_ 2566642942 EnableStatusOfDoor22 5;
BA_ "SPN" SG_ 2566642942 EnableStatusOfDoor22 8530;
BA_ "SigType" SG_ 2566642942 OpenStatusOfDoor22 5;
BA_ "SPN" SG_ 2566642942 OpenStatusOfDoor22 8529;
BA_ "SigType" SG_ 2566642942 LockStatusOfDoor22 5;
BA_ "SPN" SG_ 2566642942 LockStatusOfDoor22 8528;
BA_ "SigType" SG_ 2566642942 EnableStatusOfDoor21 5;
BA_ "SPN" SG_ 2566642942 EnableStatusOfDoor21 8527;
BA_ "SigType" SG_ 2566642942 OpenStatusOfDoor21 5;
BA_ "SPN" SG_ 2566642942 OpenStatusOfDoor21 8526;
BA_ "SigType" SG_ 2566642942 LockStatusOfDoor21 5;
BA_ "SPN" SG_ 2566642942 LockStatusOfDoor21 8525;
BA_ "SigType" SG_ 2365315838 HiSideCurMaxLmt 1;
BA_ "SPN" SG_ 2365315838 HiSideCurMaxLmt 8565;
BA_ "SigType" SG_ 2365315838 HiSideVMaxLmt 1;
BA_ "SPN" SG_ 2365315838 HiSideVMaxLmt 8564;
BA_ "SigType" SG_ 2365315838 HiSideVMinLmt 1;
BA_ "SPN" SG_ 2365315838 HiSideVMinLmt 8563;
BA_ "SigType" SG_ 2365315582 LowSideCurMaxLmt 1;
BA_ "SPN" SG_ 2365315582 LowSideCurMaxLmt 8568;
BA_ "SigType" SG_ 2365315582 LowSideVMaxLmt 1;
BA_ "SPN" SG_ 2365315582 LowSideVMaxLmt 8567;
BA_ "SigType" SG_ 2365315582 LowSideVMinLmt 1;
BA_ "SPN" SG_ 2365315582 LowSideVMinLmt 8566;
BA_ "SigType" SG_ 2365315326 OneCoolantOutTemp 1;
BA_ "SPN" SG_ 2365315326 OneCoolantOutTemp 8823;
BA_ "SigType" SG_ 2365315326 OneCoolantInTemp 1;
BA_ "SPN" SG_ 2365315326 OneCoolantInTemp 8822;
BA_ "SigType" SG_ 2365315326 PwrETemp 1;
BA_ "SPN" SG_ 2365315326 PwrETemp 8594;
BA_ "SigType" SG_ 2365315326 ElectronicFilterTemp 1;
BA_ "SPN" SG_ 2365315326 ElectronicFilterTemp 8593;
BA_ "SigType" SG_ 2365315326 Temp 1;
BA_ "SPN" SG_ 2365315326 Temp 8592;
BA_ "SigType" SG_ 2633750526 PGNModifiedStatus 5;
BA_ "SPN" SG_ 2633750526 PGNModifiedStatus 8605;
BA_ "SigType" SG_ 2633750526 PGNPendingChangeStatus 5;
BA_ "SPN" SG_ 2633750526 PGNPendingChangeStatus 8604;
BA_ "SigType" SG_ 2633750526 PGNCurTransmitStatus 5;
BA_ "SPN" SG_ 2633750526 PGNCurTransmitStatus 8603;
BA_ "SPN" SG_ 2633750526 PGN 8602;
BA_ "SPN" SG_ 2633750526 PortCmdStatus 8601;
BA_ "SPN" SG_ 2633750526 PortPendingChangesStatus 8600;
BA_ "SPN" SG_ 2633750526 Port 8599;
BA_ "SigType" SG_ 2566641406 ExhManifoldPress2 1;
BA_ "SPN" SG_ 2566641406 ExhManifoldPress2 8620;
BA_ "SigType" SG_ 2566641406 ExhManifoldPress1 1;
BA_ "SPN" SG_ 2566641406 ExhManifoldPress1 8619;
BA_ "SigType" SG_ 2566641150 EngOilCoolerInTemp 1;
BA_ "SPN" SG_ 2566641150 EngOilCoolerInTemp 8638;
BA_ "SigType" SG_ 2566641150 EngOilCoolerDisPumpPress 1;
BA_ "SPN" SG_ 2566641150 EngOilCoolerDisPumpPress 8637;
BA_ "SigType" SG_ 2566641150 AltOilCoolerDisPumpPress 1;
BA_ "SPN" SG_ 2566641150 AltOilCoolerDisPumpPress 8636;
BA_ "SigType" SG_ 2566641150 AltBearingHeaderInPress 1;
BA_ "SPN" SG_ 2566641150 AltBearingHeaderInPress 8635;
BA_ "SigType" SG_ 2633749758 RatedSpd 1;
BA_ "SPN" SG_ 2633749758 RatedSpd 8655;
BA_ "SigType" SG_ 2633749758 GearRatio 1;
BA_ "SPN" SG_ 2633749758 GearRatio 8654;
BA_ "SigType" SG_ 2633749758 StrokeLength 1;
BA_ "SPN" SG_ 2633749758 StrokeLength 8653;
BA_ "SigType" SG_ 2633749758 PlungerDiameter 1;
BA_ "SPN" SG_ 2633749758 PlungerDiameter 8652;
BA_ "SigType" SG_ 2633749502 CycleCount 1;
BA_ "SPN" SG_ 2633749502 CycleCount 8659;
BA_ "SigType" SG_ 2633749502 WorkingHours 1;
BA_ "SPN" SG_ 2633749502 WorkingHours 8658;
BA_ "SigType" SG_ 2633749502 PwrEndWorkingHours 1;
BA_ "SPN" SG_ 2633749502 PwrEndWorkingHours 8657;
BA_ "SigType" SG_ 2633749502 FluidEndWorkingHours 1;
BA_ "SPN" SG_ 2633749502 FluidEndWorkingHours 8656;
BA_ "SigType" SG_ 2566640382 WellStimPumpOilTemp 1;
BA_ "SPN" SG_ 2566640382 WellStimPumpOilTemp 8663;
BA_ "SigType" SG_ 2566640382 WellStimPumpOilRelDielectricity 1;
BA_ "SPN" SG_ 2566640382 WellStimPumpOilRelDielectricity 8662;
BA_ "SigType" SG_ 2566640382 WellStimPumpOilDensity 1;
BA_ "SPN" SG_ 2566640382 WellStimPumpOilDensity 8661;
BA_ "SigType" SG_ 2566640382 WellStimPumpOilViscosity 1;
BA_ "SPN" SG_ 2566640382 WellStimPumpOilViscosity 8660;
BA_ "SigType" SG_ 2431719166 RatedRodLoadPercent 1;
BA_ "SPN" SG_ 2431719166 RatedRodLoadPercent 12811;
BA_ "SigType" SG_ 2431719166 FlowRate 1;
BA_ "SPN" SG_ 2431719166 FlowRate 8650;
BA_ "SigType" SG_ 2431719166 FluidEndVlvLeak 4;
BA_ "SPN" SG_ 2431719166 FluidEndVlvLeak 8651;
BA_ "SPN" SG_ 2431719166 CavitationStatus 8649;
BA_ "SigType" SG_ 2431719166 RodLoad 1;
BA_ "SPN" SG_ 2431719166 RodLoad 8648;
BA_ "SigType" SG_ 2364610046 SLIBatTermTemp 1;
BA_ "SPN" SG_ 2364610046 SLIBatTermTemp 8591;
BA_ "SigType" SG_ 2364610046 SLIBatTermCur 1;
BA_ "SPN" SG_ 2364610046 SLIBatTermCur 8590;
BA_ "SigType" SG_ 2364610046 SLIBatTermV 1;
BA_ "SPN" SG_ 2364610046 SLIBatTermV 8589;
BA_ "SigType" SG_ 2364609790 HiSideCur 1;
BA_ "SPN" SG_ 2364609790 HiSideCur 8588;
BA_ "SigType" SG_ 2364609790 HiSideV 1;
BA_ "SPN" SG_ 2364609790 HiSideV 8587;
BA_ "SigType" SG_ 2364609790 LowSideCur 1;
BA_ "SPN" SG_ 2364609790 LowSideCur 8586;
BA_ "SigType" SG_ 2364609790 LowSideV 1;
BA_ "SPN" SG_ 2364609790 LowSideV 8585;
BA_ "SigType" SG_ 2364609534 DCDC1OperatingStatusCRC 12;
BA_ "SPN" SG_ 2364609534 DCDC1OperatingStatusCRC 7958;
BA_ "SigType" SG_ 2364609534 DCDC1OperatingStatusCounter 11;
BA_ "SPN" SG_ 2364609534 DCDC1OperatingStatusCounter 7957;
BA_ "SigType" SG_ 2364609534 PLDueToUndefinedReason 4;
BA_ "SPN" SG_ 2364609534 PLDueToUndefinedReason 8584;
BA_ "SigType" SG_ 2364609534 PLDueToSLIBatTermTemp 4;
BA_ "SPN" SG_ 2364609534 PLDueToSLIBatTermTemp 8582;
BA_ "SigType" SG_ 2364609534 PLDueToSLIBatTermCur 4;
BA_ "SPN" SG_ 2364609534 PLDueToSLIBatTermCur 8583;
BA_ "SigType" SG_ 2364609534 PLDueToSLIBatTermV 4;
BA_ "SPN" SG_ 2364609534 PLDueToSLIBatTermV 8581;
BA_ "SigType" SG_ 2364609534 PLDueToPwrETemp 4;
BA_ "SPN" SG_ 2364609534 PLDueToPwrETemp 8580;
BA_ "SigType" SG_ 2364609534 PLDueToElectronicFilterTemp 4;
BA_ "SPN" SG_ 2364609534 PLDueToElectronicFilterTemp 8579;
BA_ "SigType" SG_ 2364609534 PLDueToCtrlTemp 4;
BA_ "SPN" SG_ 2364609534 PLDueToCtrlTemp 8578;
BA_ "SigType" SG_ 2364609534 PLDueToLowSideVMax 4;
BA_ "SPN" SG_ 2364609534 PLDueToLowSideVMax 8577;
BA_ "SigType" SG_ 2364609534 PLDueToLowSideVMin 4;
BA_ "SPN" SG_ 2364609534 PLDueToLowSideVMin 8576;
BA_ "SigType" SG_ 2364609534 PLDueToHiSideVMax 4;
BA_ "SPN" SG_ 2364609534 PLDueToHiSideVMax 8575;
BA_ "SigType" SG_ 2364609534 PLDueToHiSideVMin 4;
BA_ "SPN" SG_ 2364609534 PLDueToHiSideVMin 8574;
BA_ "SigType" SG_ 2364609534 PLDueToLowSideCur 4;
BA_ "SPN" SG_ 2364609534 PLDueToLowSideCur 8573;
BA_ "SigType" SG_ 2364609534 PLDueToHiSideCur 4;
BA_ "SPN" SG_ 2364609534 PLDueToHiSideCur 8572;
BA_ "SigType" SG_ 2364609534 LoadshedReq 5;
BA_ "SPN" SG_ 2364609534 LoadshedReq 8571;
BA_ "SigType" SG_ 2364609534 HVILStatus 4;
BA_ "SPN" SG_ 2364609534 HVILStatus 8570;
BA_ "SPN" SG_ 2364609534 OperationalStatus 8569;
BA_ "SigType" SG_ 2364609278 DCDC1CtrlCRC 12;
BA_ "SPN" SG_ 2364609278 DCDC1CtrlCRC 7956;
BA_ "SigType" SG_ 2364609278 DCDC1CtrlCounter 11;
BA_ "SPN" SG_ 2364609278 DCDC1CtrlCounter 7955;
BA_ "SigType" SG_ 2364609278 OneLowSideVBuckDefaultSetpoint 1;
BA_ "SPN" SG_ 2364609278 OneLowSideVBuckDefaultSetpoint 9515;
BA_ "SigType" SG_ 2364609278 HiSideVBoostSetpoint 1;
BA_ "SPN" SG_ 2364609278 HiSideVBoostSetpoint 8562;
BA_ "SigType" SG_ 2364609278 LowSideVBuckSetpoint 1;
BA_ "SPN" SG_ 2364609278 LowSideVBuckSetpoint 8561;
BA_ "SPN" SG_ 2364609278 OperationalCmd 8560;
BA_ "SigType" SG_ 2431717886 EngGasFuelSupplyFilterInPress 1;
BA_ "SPN" SG_ 2431717886 EngGasFuelSupplyFilterInPress 12302;
BA_ "SigType" SG_ 2431717886 EngGasFuelSupplyFilterDiffPress 1;
BA_ "SPN" SG_ 2431717886 EngGasFuelSupplyFilterDiffPress 12301;
BA_ "SigType" SG_ 2431717886 EngFuelVlv1DiffPress 1;
BA_ "SPN" SG_ 2431717886 EngFuelVlv1DiffPress 8494;
BA_ "SigType" SG_ 2297499902 BrkPedalSw2 4;
BA_ "SPN" SG_ 2297499902 BrkPedalSw2 603;
BA_ "SigType" SG_ 2297499902 DemandedBrkAppPress 1;
BA_ "SPN" SG_ 2297499902 DemandedBrkAppPress 8484;
BA_ "SigType" SG_ 2364608510 CoolantFlow 4;
BA_ "SPN" SG_ 2364608510 CoolantFlow 22136;
BA_ "SigType" SG_ 2364608510 PwtnProtState 5;
BA_ "SPN" SG_ 2364608510 PwtnProtState 22135;
BA_ "SigType" SG_ 2364608510 AFTThermalMnmgtElevatedIdleSt 5;
BA_ "SPN" SG_ 2364608510 AFTThermalMnmgtElevatedIdleSt 22134;
BA_ "SigType" SG_ 2364608510 PwrDerateReq 1;
BA_ "SPN" SG_ 2364608510 PwrDerateReq 8436;
BA_ "SigType" SG_ 2364608510 SelfInducedDerateLoad 1;
BA_ "SPN" SG_ 2364608510 SelfInducedDerateLoad 8435;
BA_ "SigType" SG_ 2498825982 BodyEjectorBladePos 1;
BA_ "SPN" SG_ 2498825982 BodyEjectorBladePos 8315;
BA_ "SigType" SG_ 2498825982 BodyRaisePosRelToRecommendedMax 1;
BA_ "SPN" SG_ 2498825982 BodyRaisePosRelToRecommendedMax 8314;
BA_ "SigType" SG_ 2498825982 BodyRaiseAngle 1;
BA_ "SPN" SG_ 2498825982 BodyRaiseAngle 8313;
BA_ "SigType" SG_ 2498825982 BodyRollAngle 1;
BA_ "SPN" SG_ 2498825982 BodyRollAngle 8312;
BA_ "SigType" SG_ 2565934590 EngFuelVlv2DiffPress 1;
BA_ "SPN" SG_ 2565934590 EngFuelVlv2DiffPress 6885;
BA_ "SigType" SG_ 2364607742 HVBusPassiveIsolTestResults 1;
BA_ "SPN" SG_ 2364607742 HVBusPassiveIsolTestResults 8432;
BA_ "SigType" SG_ 2364607742 HVBusActiveIsolTestResults 1;
BA_ "SPN" SG_ 2364607742 HVBusActiveIsolTestResults 8431;
BA_ "SigType" SG_ 2364607742 LowestCellStOfChargeCellNum 1;
BA_ "SPN" SG_ 2364607742 LowestCellStOfChargeCellNum 8248;
BA_ "SigType" SG_ 2364607742 LowestCellStOfChargeModuleNum 1;
BA_ "SPN" SG_ 2364607742 LowestCellStOfChargeModuleNum 8247;
BA_ "SigType" SG_ 2364607742 HighestCellStOfChargeCellNum 1;
BA_ "SPN" SG_ 2364607742 HighestCellStOfChargeCellNum 8246;
BA_ "SigType" SG_ 2364607742 HighestCellStOfChargeModuleNum 1;
BA_ "SPN" SG_ 2364607742 HighestCellStOfChargeModuleNum 8245;
BA_ "SigType" SG_ 2364607486 Data9CRC 12;
BA_ "SPN" SG_ 2364607486 Data9CRC 22973;
BA_ "SigType" SG_ 2364607486 Data9Counter 11;
BA_ "SPN" SG_ 2364607486 Data9Counter 22972;
BA_ "SigType" SG_ 2364607486 Data9EmbeddedIntegritySupport 5;
BA_ "SPN" SG_ 2364607486 Data9EmbeddedIntegritySupport 22971;
BA_ "SigType" SG_ 2364607486 ThermalEventDetected 4;
BA_ "SPN" SG_ 2364607486 ThermalEventDetected 21287;
BA_ "SigType" SG_ 2364607486 LowestCellTempCellNum 1;
BA_ "SPN" SG_ 2364607486 LowestCellTempCellNum 8244;
BA_ "SigType" SG_ 2364607486 LowestCellTempModuleNum 1;
BA_ "SPN" SG_ 2364607486 LowestCellTempModuleNum 8243;
BA_ "SigType" SG_ 2364607486 HighestCellTempCellNum 1;
BA_ "SPN" SG_ 2364607486 HighestCellTempCellNum 8242;
BA_ "SigType" SG_ 2364607486 HighestCellTempModuleNum 1;
BA_ "SPN" SG_ 2364607486 HighestCellTempModuleNum 8241;
BA_ "SigType" SG_ 2364607230 AvgCellV 1;
BA_ "SPN" SG_ 2364607230 AvgCellV 8240;
BA_ "SigType" SG_ 2364607230 LowestCellVCellNum 1;
BA_ "SPN" SG_ 2364607230 LowestCellVCellNum 8239;
BA_ "SigType" SG_ 2364607230 LowestCellVModuleNum 1;
BA_ "SPN" SG_ 2364607230 LowestCellVModuleNum 8238;
BA_ "SigType" SG_ 2364607230 HighestCellVCellNum 1;
BA_ "SPN" SG_ 2364607230 HighestCellVCellNum 8237;
BA_ "SigType" SG_ 2364607230 HighestCellVModuleNum 1;
BA_ "SPN" SG_ 2364607230 HighestCellVModuleNum 8236;
BA_ "SigType" SG_ 2364606974 TMSCoolantLvl 4;
BA_ "SPN" SG_ 2364606974 TMSCoolantLvl 12897;
BA_ "SigType" SG_ 2364606974 TMSHVILStatus 4;
BA_ "SPN" SG_ 2364606974 TMSHVILStatus 12813;
BA_ "SPN" SG_ 2364606974 TMSMode 8235;
BA_ "SigType" SG_ 2364606974 TMSHtrStatus 5;
BA_ "SPN" SG_ 2364606974 TMSHtrStatus 8234;
BA_ "SigType" SG_ 2364606974 TMSRelHumidty 1;
BA_ "SPN" SG_ 2364606974 TMSRelHumidty 8233;
BA_ "SigType" SG_ 2364606974 TMSCompressorSpd 1;
BA_ "SPN" SG_ 2364606974 TMSCompressorSpd 8232;
BA_ "SigType" SG_ 2364606974 TMSHVInputPwr 1;
BA_ "SPN" SG_ 2364606974 TMSHVInputPwr 8231;
BA_ "SigType" SG_ 2364606974 TMSSLIInputPwr 1;
BA_ "SPN" SG_ 2364606974 TMSSLIInputPwr 8230;
BA_ "SigType" SG_ 2364606718 Module32OperationalStatus 5;
BA_ "SPN" SG_ 2364606718 Module32OperationalStatus 14624;
BA_ "SigType" SG_ 2364606718 Module31OperationalStatus 5;
BA_ "SPN" SG_ 2364606718 Module31OperationalStatus 14623;
BA_ "SigType" SG_ 2364606718 Module30OperationalStatus 5;
BA_ "SPN" SG_ 2364606718 Module30OperationalStatus 14622;
BA_ "SigType" SG_ 2364606718 Module29OperationalStatus 5;
BA_ "SPN" SG_ 2364606718 Module29OperationalStatus 14621;
BA_ "SigType" SG_ 2364606718 Module28OperationalStatus 5;
BA_ "SPN" SG_ 2364606718 Module28OperationalStatus 14620;
BA_ "SigType" SG_ 2364606718 Module27OperationalStatus 5;
BA_ "SPN" SG_ 2364606718 Module27OperationalStatus 14619;
BA_ "SigType" SG_ 2364606718 Module26OperationalStatus 5;
BA_ "SPN" SG_ 2364606718 Module26OperationalStatus 14618;
BA_ "SigType" SG_ 2364606718 Module25OperationalStatus 5;
BA_ "SPN" SG_ 2364606718 Module25OperationalStatus 14617;
BA_ "SigType" SG_ 2364606718 Module24OperationalStatus 5;
BA_ "SPN" SG_ 2364606718 Module24OperationalStatus 14616;
BA_ "SigType" SG_ 2364606718 Module23OperationalStatus 5;
BA_ "SPN" SG_ 2364606718 Module23OperationalStatus 14615;
BA_ "SigType" SG_ 2364606718 Module22OperationalStatus 5;
BA_ "SPN" SG_ 2364606718 Module22OperationalStatus 14614;
BA_ "SigType" SG_ 2364606718 Module21OperationalStatus 5;
BA_ "SPN" SG_ 2364606718 Module21OperationalStatus 14613;
BA_ "SigType" SG_ 2364606718 Module20OperationalStatus 5;
BA_ "SPN" SG_ 2364606718 Module20OperationalStatus 14612;
BA_ "SigType" SG_ 2364606718 Module19OperationalStatus 5;
BA_ "SPN" SG_ 2364606718 Module19OperationalStatus 14611;
BA_ "SigType" SG_ 2364606718 Module18OperationalStatus 5;
BA_ "SPN" SG_ 2364606718 Module18OperationalStatus 14610;
BA_ "SigType" SG_ 2364606718 Module17OperationalStatus 5;
BA_ "SPN" SG_ 2364606718 Module17OperationalStatus 14609;
BA_ "SigType" SG_ 2364606718 Module16OperationalStatus 5;
BA_ "SPN" SG_ 2364606718 Module16OperationalStatus 8229;
BA_ "SigType" SG_ 2364606718 Module15OperationalStatus 5;
BA_ "SPN" SG_ 2364606718 Module15OperationalStatus 8228;
BA_ "SigType" SG_ 2364606718 Module14OperationalStatus 5;
BA_ "SPN" SG_ 2364606718 Module14OperationalStatus 8227;
BA_ "SigType" SG_ 2364606718 Module13OperationalStatus 5;
BA_ "SPN" SG_ 2364606718 Module13OperationalStatus 8226;
BA_ "SigType" SG_ 2364606718 Module12OperationalStatus 5;
BA_ "SPN" SG_ 2364606718 Module12OperationalStatus 8225;
BA_ "SigType" SG_ 2364606718 Module11OperationalStatus 5;
BA_ "SPN" SG_ 2364606718 Module11OperationalStatus 8224;
BA_ "SigType" SG_ 2364606718 Module10OperationalStatus 5;
BA_ "SPN" SG_ 2364606718 Module10OperationalStatus 8223;
BA_ "SigType" SG_ 2364606718 Module9OperationalStatus 5;
BA_ "SPN" SG_ 2364606718 Module9OperationalStatus 8222;
BA_ "SigType" SG_ 2364606718 Module8OperationalStatus 5;
BA_ "SPN" SG_ 2364606718 Module8OperationalStatus 8221;
BA_ "SigType" SG_ 2364606718 Module7OperationalStatus 5;
BA_ "SPN" SG_ 2364606718 Module7OperationalStatus 8220;
BA_ "SigType" SG_ 2364606718 Module6OperationalStatus 5;
BA_ "SPN" SG_ 2364606718 Module6OperationalStatus 8219;
BA_ "SigType" SG_ 2364606718 Module5OperationalStatus 5;
BA_ "SPN" SG_ 2364606718 Module5OperationalStatus 8218;
BA_ "SigType" SG_ 2364606718 Module4OperationalStatus 5;
BA_ "SPN" SG_ 2364606718 Module4OperationalStatus 8217;
BA_ "SigType" SG_ 2364606718 Module3OperationalStatus 5;
BA_ "SPN" SG_ 2364606718 Module3OperationalStatus 8216;
BA_ "SigType" SG_ 2364606718 Module2OperationalStatus 5;
BA_ "SPN" SG_ 2364606718 Module2OperationalStatus 8215;
BA_ "SigType" SG_ 2364606718 Module1OperationalStatus 5;
BA_ "SPN" SG_ 2364606718 Module1OperationalStatus 8214;
BA_ "SigType" SG_ 2565933054 GearBoxOutOilTemp 1;
BA_ "SPN" SG_ 2565933054 GearBoxOutOilTemp 12812;
BA_ "SigType" SG_ 2565933054 Spd 1;
BA_ "SPN" SG_ 2565933054 Spd 8158;
BA_ "SigType" SG_ 2565933054 GearBoxOilTemp 1;
BA_ "SPN" SG_ 2565933054 GearBoxOilTemp 8157;
BA_ "SigType" SG_ 2565933054 GearBoxOilPress 1;
BA_ "SPN" SG_ 2565933054 GearBoxOilPress 8156;
BA_ "SigType" SG_ 2565932798 DisPress 1;
BA_ "SPN" SG_ 2565932798 DisPress 8155;
BA_ "SigType" SG_ 2565932798 SuctionPress 1;
BA_ "SPN" SG_ 2565932798 SuctionPress 8154;
BA_ "SigType" SG_ 2364605950 MechMovementAngle 1;
BA_ "SPN" SG_ 2364605950 MechMovementAngle 7940;
BA_ "SigType" SG_ 2364605950 LinePress 1;
BA_ "SPN" SG_ 2364605950 LinePress 7939;
BA_ "SigType" SG_ 2565932286 Vour 1;
BA_ "SPN" SG_ 2565932286 Vour 7846;
BA_ "SigType" SG_ 2364605438 KVArHoursExport 1;
BA_ "SPN" SG_ 2364605438 KVArHoursExport 7832;
BA_ "SigType" SG_ 2364605438 KWHoursExport 1;
BA_ "SPN" SG_ 2364605438 KWHoursExport 7831;
BA_ "SigType" SG_ 2364605182 PitchSensitivityCmd 1;
BA_ "SPN" SG_ 2364605182 PitchSensitivityCmd 7811;
BA_ "SigType" SG_ 2364605182 PitchCmd 1;
BA_ "SPN" SG_ 2364605182 PitchCmd 7810;
BA_ "SigType" SG_ 2364605182 SensitivityCmd 1;
BA_ "SPN" SG_ 2364605182 SensitivityCmd 7809;
BA_ "SigType" SG_ 2364605182 Cmd 1;
BA_ "SPN" SG_ 2364605182 Cmd 7808;
BA_ "SPN" SG_ 2364604926 PitchExit_ReasonCode 7807;
BA_ "SPN" SG_ 2364604926 PitchLmtSt 7806;
BA_ "SigType" SG_ 2364604926 PitchAngle 1;
BA_ "SPN" SG_ 2364604926 PitchAngle 7805;
BA_ "SPN" SG_ 2364604926 Exit_ReasonCode 7804;
BA_ "SPN" SG_ 2364604926 LmtSt 7803;
BA_ "SigType" SG_ 2364604926 Angle 1;
BA_ "SPN" SG_ 2364604926 Angle 7802;
BA_ "SigType" SG_ 2364604670 PitchSensitivityCmd 1;
BA_ "SPN" SG_ 2364604670 PitchSensitivityCmd 7799;
BA_ "SigType" SG_ 2364604670 PitchCmd 1;
BA_ "SPN" SG_ 2364604670 PitchCmd 7798;
BA_ "SigType" SG_ 2364604670 SensitivityCmd 1;
BA_ "SPN" SG_ 2364604670 SensitivityCmd 7797;
BA_ "SigType" SG_ 2364604670 Cmd 1;
BA_ "SPN" SG_ 2364604670 Cmd 7796;
BA_ "SPN" SG_ 2364604414 PitchExit_ReasonCode 7795;
BA_ "SPN" SG_ 2364604414 PitchLmtSt 7794;
BA_ "SigType" SG_ 2364604414 PitchAngle 1;
BA_ "SPN" SG_ 2364604414 PitchAngle 7793;
BA_ "SPN" SG_ 2364604414 Exit_ReasonCode 7792;
BA_ "SPN" SG_ 2364604414 LmtSt 7791;
BA_ "SigType" SG_ 2364604414 Angle 1;
BA_ "SPN" SG_ 2364604414 Angle 7790;
BA_ "SigType" SG_ 2364604158 DEFActualQuantityOfIntegrator 1;
BA_ "SPN" SG_ 2364604158 DEFActualQuantityOfIntegrator 7787;
BA_ "SigType" SG_ 2364603902 DEFActualQuantityOfIntegrator 1;
BA_ "SPN" SG_ 2364603902 DEFActualQuantityOfIntegrator 7786;
BA_ "SigType" SG_ 2364603646 DEFDoserVlv2Cmd 1;
BA_ "SPN" SG_ 2364603646 DEFDoserVlv2Cmd 22721;
BA_ "SigType" SG_ 2364603646 DEFDoserVlv1Cmd 1;
BA_ "SPN" SG_ 2364603646 DEFDoserVlv1Cmd 22720;
BA_ "SigType" SG_ 2364603646 DEFReqQuantityOfIntegrator 1;
BA_ "SPN" SG_ 2364603646 DEFReqQuantityOfIntegrator 7784;
BA_ "SigType" SG_ 2364603390 DEFDoserVlv2Cmd 1;
BA_ "SPN" SG_ 2364603390 DEFDoserVlv2Cmd 8307;
BA_ "SigType" SG_ 2364603390 DEFDoserVlv1Cmd 1;
BA_ "SPN" SG_ 2364603390 DEFDoserVlv1Cmd 8442;
BA_ "SigType" SG_ 2364603390 DEFReqQuantityOfIntegrator 1;
BA_ "SPN" SG_ 2364603390 DEFReqQuantityOfIntegrator 7783;
BA_ "SigType" SG_ 2364603134 Mode20Ind 4;
BA_ "SPN" SG_ 2364603134 Mode20Ind 12948;
BA_ "SigType" SG_ 2364603134 Mode19Ind 4;
BA_ "SPN" SG_ 2364603134 Mode19Ind 12947;
BA_ "SigType" SG_ 2364603134 Mode18Ind 4;
BA_ "SPN" SG_ 2364603134 Mode18Ind 12946;
BA_ "SigType" SG_ 2364603134 Mode17Ind 4;
BA_ "SPN" SG_ 2364603134 Mode17Ind 12945;
BA_ "SigType" SG_ 2364603134 Mode16Ind 4;
BA_ "SPN" SG_ 2364603134 Mode16Ind 12944;
BA_ "SigType" SG_ 2364603134 Mode15Ind 4;
BA_ "SPN" SG_ 2364603134 Mode15Ind 12943;
BA_ "SigType" SG_ 2364603134 Mode14Ind 4;
BA_ "SPN" SG_ 2364603134 Mode14Ind 12942;
BA_ "SigType" SG_ 2364603134 Mode13Ind 4;
BA_ "SPN" SG_ 2364603134 Mode13Ind 12941;
BA_ "SigType" SG_ 2364603134 Mode12Ind 4;
BA_ "SPN" SG_ 2364603134 Mode12Ind 12940;
BA_ "SigType" SG_ 2364603134 Mode11Ind 4;
BA_ "SPN" SG_ 2364603134 Mode11Ind 12939;
BA_ "SPN" SG_ 2364603134 SAOfActiveOrPendingTransReqGear 8613;
BA_ "SigType" SG_ 2364603134 MaxReverseTransOSS 1;
BA_ "SPN" SG_ 2364603134 MaxReverseTransOSS 7780;
BA_ "SigType" SG_ 2364603134 MaxForwardTransOSS 1;
BA_ "SPN" SG_ 2364603134 MaxForwardTransOSS 7779;
BA_ "SPN" SG_ 2364602878 CtrlModule8PreliminaryFMI 7777;
BA_ "SPN" SG_ 2364602878 CtrlModule7PreliminaryFMI 7776;
BA_ "SPN" SG_ 2364602878 CtrlModule6PreliminaryFMI 7775;
BA_ "SPN" SG_ 2364602878 CtrlModule5PreliminaryFMI 7774;
BA_ "SPN" SG_ 2364602878 CtrlModule4PreliminaryFMI 7773;
BA_ "SPN" SG_ 2364602878 CtrlModule3PreliminaryFMI 7772;
BA_ "SPN" SG_ 2364602878 CtrlModule2PreliminaryFMI 7771;
BA_ "SPN" SG_ 2364602878 CtrlModule1PreliminaryFMI 7770;
BA_ "SigType" SG_ 2565923838 HVILStatus 4;
BA_ "SPN" SG_ 2565923838 HVILStatus 8854;
BA_ "SigType" SG_ 2565923838 ACSideRMSCur 1;
BA_ "SPN" SG_ 2565923838 ACSideRMSCur 9203;
BA_ "SigType" SG_ 2565923838 LoadshedReq 5;
BA_ "SPN" SG_ 2565923838 LoadshedReq 8383;
BA_ "SPN" SG_ 2565923838 StatusFeedback 8382;
BA_ "SigType" SG_ 2565923838 PwrFeedback 1;
BA_ "SPN" SG_ 2565923838 PwrFeedback 8381;
BA_ "SigType" SG_ 2565923838 VFeedback 1;
BA_ "SPN" SG_ 2565923838 VFeedback 8380;
BA_ "SigType" SG_ 2565923838 FreqFeedback 1;
BA_ "SPN" SG_ 2565923838 FreqFeedback 8379;
BA_ "SigType" SG_ 2565923582 ACSideMotorStartingRMSVReq 1;
BA_ "SPN" SG_ 2565923582 ACSideMotorStartingRMSVReq 9546;
BA_ "SigType" SG_ 2565923582 EnableCmd 5;
BA_ "SPN" SG_ 2565923582 EnableCmd 8378;
BA_ "SPN" SG_ 2565923582 Device2Status 8377;
BA_ "SPN" SG_ 2565923582 Device1Status 8376;
BA_ "SigType" SG_ 2565923582 FreqCmd 1;
BA_ "SPN" SG_ 2565923582 FreqCmd 8375;
BA_ "SigType" SG_ 2565923582 DeviceFreqRateOfChangeLmt 1;
BA_ "SPN" SG_ 2565923582 DeviceFreqRateOfChangeLmt 8374;
BA_ "SigType" SG_ 2565923582 DeviceRatedV 1;
BA_ "SPN" SG_ 2565923582 DeviceRatedV 8373;
BA_ "SigType" SG_ 2565923582 DeviceRatedFreq 1;
BA_ "SPN" SG_ 2565923582 DeviceRatedFreq 8372;
BA_ "SigType" SG_ 2565923582 DeviceMinFreq 1;
BA_ "SPN" SG_ 2565923582 DeviceMinFreq 8371;
BA_ "SigType" SG_ 2565923582 DeviceMaxFreq 1;
BA_ "SPN" SG_ 2565923582 DeviceMaxFreq 8370;
BA_ "SigType" SG_ 2565922814 HVILStatus 4;
BA_ "SPN" SG_ 2565922814 HVILStatus 8853;
BA_ "SigType" SG_ 2565922814 ACSideRMSCur 1;
BA_ "SPN" SG_ 2565922814 ACSideRMSCur 9202;
BA_ "SigType" SG_ 2565922814 LoadshedReq 5;
BA_ "SPN" SG_ 2565922814 LoadshedReq 8369;
BA_ "SPN" SG_ 2565922814 StatusFeedback 8368;
BA_ "SigType" SG_ 2565922814 PwrFeedback 1;
BA_ "SPN" SG_ 2565922814 PwrFeedback 8367;
BA_ "SigType" SG_ 2565922814 VFeedback 1;
BA_ "SPN" SG_ 2565922814 VFeedback 8366;
BA_ "SigType" SG_ 2565922814 FreqFeedback 1;
BA_ "SPN" SG_ 2565922814 FreqFeedback 8365;
BA_ "SigType" SG_ 2565922558 ACSideMotorStartingRMSVReq 1;
BA_ "SPN" SG_ 2565922558 ACSideMotorStartingRMSVReq 9540;
BA_ "SigType" SG_ 2565922558 EnableCmd 5;
BA_ "SPN" SG_ 2565922558 EnableCmd 8364;
BA_ "SPN" SG_ 2565922558 Device2Status 8363;
BA_ "SPN" SG_ 2565922558 Device1Status 8362;
BA_ "SigType" SG_ 2565922558 FreqCmd 1;
BA_ "SPN" SG_ 2565922558 FreqCmd 8361;
BA_ "SigType" SG_ 2565922558 DeviceFreqRateOfChangeLmt 1;
BA_ "SPN" SG_ 2565922558 DeviceFreqRateOfChangeLmt 8360;
BA_ "SigType" SG_ 2565922558 DeviceRatedV 1;
BA_ "SPN" SG_ 2565922558 DeviceRatedV 8359;
BA_ "SigType" SG_ 2565922558 DeviceRatedFreq 1;
BA_ "SPN" SG_ 2565922558 DeviceRatedFreq 8358;
BA_ "SigType" SG_ 2565922558 DeviceMinFreq 1;
BA_ "SPN" SG_ 2565922558 DeviceMinFreq 8357;
BA_ "SigType" SG_ 2565922558 DeviceMaxFreq 1;
BA_ "SPN" SG_ 2565922558 DeviceMaxFreq 8356;
BA_ "SigType" SG_ 2565921790 HVILStatus 4;
BA_ "SPN" SG_ 2565921790 HVILStatus 8852;
BA_ "SigType" SG_ 2565921790 ACSideRMSCur 1;
BA_ "SPN" SG_ 2565921790 ACSideRMSCur 9201;
BA_ "SigType" SG_ 2565921790 LoadshedReq 5;
BA_ "SPN" SG_ 2565921790 LoadshedReq 8355;
BA_ "SPN" SG_ 2565921790 StatusFeedback 8354;
BA_ "SigType" SG_ 2565921790 PwrFeedback 1;
BA_ "SPN" SG_ 2565921790 PwrFeedback 8353;
BA_ "SigType" SG_ 2565921790 VFeedback 1;
BA_ "SPN" SG_ 2565921790 VFeedback 8352;
BA_ "SigType" SG_ 2565921790 FreqFeedback 1;
BA_ "SPN" SG_ 2565921790 FreqFeedback 8351;
BA_ "SigType" SG_ 2565921534 ACSideMotorStartingRMSVReq 1;
BA_ "SPN" SG_ 2565921534 ACSideMotorStartingRMSVReq 9534;
BA_ "SigType" SG_ 2565921534 EnableCmd 5;
BA_ "SPN" SG_ 2565921534 EnableCmd 8350;
BA_ "SPN" SG_ 2565921534 Device2Status 8349;
BA_ "SPN" SG_ 2565921534 Device1Status 8348;
BA_ "SigType" SG_ 2565921534 FreqCmd 1;
BA_ "SPN" SG_ 2565921534 FreqCmd 8347;
BA_ "SigType" SG_ 2565921534 DeviceFreqRateOfChangeLmt 1;
BA_ "SPN" SG_ 2565921534 DeviceFreqRateOfChangeLmt 8346;
BA_ "SigType" SG_ 2565921534 DeviceRatedV 1;
BA_ "SPN" SG_ 2565921534 DeviceRatedV 8345;
BA_ "SigType" SG_ 2565921534 DeviceRatedFreq 1;
BA_ "SPN" SG_ 2565921534 DeviceRatedFreq 8344;
BA_ "SigType" SG_ 2565921534 DeviceMinFreq 1;
BA_ "SPN" SG_ 2565921534 DeviceMinFreq 8343;
BA_ "SigType" SG_ 2565921534 DeviceMaxFreq 1;
BA_ "SPN" SG_ 2565921534 DeviceMaxFreq 8342;
BA_ "SigType" SG_ 2565920766 HVILStatus 4;
BA_ "SPN" SG_ 2565920766 HVILStatus 8851;
BA_ "SigType" SG_ 2565920766 ACSideRMSCur 1;
BA_ "SPN" SG_ 2565920766 ACSideRMSCur 9200;
BA_ "SigType" SG_ 2565920766 LoadshedReq 5;
BA_ "SPN" SG_ 2565920766 LoadshedReq 8341;
BA_ "SPN" SG_ 2565920766 StatusFeedback 8340;
BA_ "SigType" SG_ 2565920766 PwrFeedback 1;
BA_ "SPN" SG_ 2565920766 PwrFeedback 8339;
BA_ "SigType" SG_ 2565920766 VFeedback 1;
BA_ "SPN" SG_ 2565920766 VFeedback 8338;
BA_ "SigType" SG_ 2565920766 FreqFeedback 1;
BA_ "SPN" SG_ 2565920766 FreqFeedback 8337;
BA_ "SigType" SG_ 2565920510 ACSideMotorStartingRMSVReq 1;
BA_ "SPN" SG_ 2565920510 ACSideMotorStartingRMSVReq 9528;
BA_ "SigType" SG_ 2565920510 EnableCmd 5;
BA_ "SPN" SG_ 2565920510 EnableCmd 8336;
BA_ "SPN" SG_ 2565920510 Device2Status 8335;
BA_ "SPN" SG_ 2565920510 Device1Status 8334;
BA_ "SigType" SG_ 2565920510 FreqCmd 1;
BA_ "SPN" SG_ 2565920510 FreqCmd 8333;
BA_ "SigType" SG_ 2565920510 DeviceFreqRateOfChangeLmt 1;
BA_ "SPN" SG_ 2565920510 DeviceFreqRateOfChangeLmt 8332;
BA_ "SigType" SG_ 2565920510 DeviceRatedV 1;
BA_ "SPN" SG_ 2565920510 DeviceRatedV 8331;
BA_ "SigType" SG_ 2565920510 DeviceRatedFreq 1;
BA_ "SPN" SG_ 2565920510 DeviceRatedFreq 8330;
BA_ "SigType" SG_ 2565920510 DeviceMinFreq 1;
BA_ "SPN" SG_ 2565920510 DeviceMinFreq 8329;
BA_ "SigType" SG_ 2565920510 DeviceMaxFreq 1;
BA_ "SPN" SG_ 2565920510 DeviceMaxFreq 8328;
BA_ "SigType" SG_ 2364580094 MaxChargeVLmt 1;
BA_ "SPN" SG_ 2364580094 MaxChargeVLmt 8090;
BA_ "SPN" SG_ 2364580094 ChargeEnergyCapacity 8206;
BA_ "SPN" SG_ 2364580094 DisEnergyCapacity 8205;
BA_ "SigType" SG_ 2364577534 Status1CRC 12;
BA_ "SPN" SG_ 2364577534 Status1CRC 13014;
BA_ "SigType" SG_ 2364577534 NumOfHVESPsReady 1;
BA_ "SPN" SG_ 2364577534 NumOfHVESPsReady 12905;
BA_ "SigType" SG_ 2364577534 Status1Counter 11;
BA_ "SPN" SG_ 2364577534 Status1Counter 13013;
BA_ "SPN" SG_ 2364577534 OperationalStatus 8414;
BA_ "SPN" SG_ 2364577534 HVBusConnectionStatus 8413;
BA_ "SigType" SG_ 2364577534 InternalChargerStatus 5;
BA_ "SPN" SG_ 2364577534 InternalChargerStatus 8207;
BA_ "SigType" SG_ 2364577534 CellBalancingActive 4;
BA_ "SPN" SG_ 2364577534 CellBalancingActive 8102;
BA_ "SigType" SG_ 2364577534 CellBalanceStatus 4;
BA_ "SPN" SG_ 2364577534 CellBalanceStatus 8101;
BA_ "SPN" SG_ 2364577534 StOfChargeStatus 8100;
BA_ "SigType" SG_ 2364577534 InertiaSwStatus 4;
BA_ "SPN" SG_ 2364577534 InertiaSwStatus 8099;
BA_ "SigType" SG_ 2364577534 HVILStatus 4;
BA_ "SPN" SG_ 2364577534 HVILStatus 8098;
BA_ "SPN" SG_ 2364577534 HVBusPassiveIsolTestStatus 8097;
BA_ "SPN" SG_ 2364577534 HVBusActiveIsolTestStatus 8096;
BA_ "SigType" SG_ 2364577534 CenterOfPackContactorSt 4;
BA_ "SPN" SG_ 2364577534 CenterOfPackContactorSt 8095;
BA_ "SigType" SG_ 2364577534 HVBusPreChargeRelaySt 4;
BA_ "SPN" SG_ 2364577534 HVBusPreChargeRelaySt 8094;
BA_ "SPN" SG_ 2364577534 HVBusDisconnectForewarning 8093;
BA_ "SigType" SG_ 2364577534 HVBusContactorSt8092 4;
BA_ "SPN" SG_ 2364577534 HVBusContactorSt8092 8092;
BA_ "SigType" SG_ 2364577534 HVBusContactorSt 4;
BA_ "SPN" SG_ 2364577534 HVBusContactorSt 8091;
BA_ "SigType" SG_ 2364577278 Temp 1;
BA_ "SPN" SG_ 2364577278 Temp 9119;
BA_ "SigType" SG_ 2364577278 ETemp 1;
BA_ "SPN" SG_ 2364577278 ETemp 8204;
BA_ "SigType" SG_ 2364577278 OutCoolantTemp 1;
BA_ "SPN" SG_ 2364577278 OutCoolantTemp 8089;
BA_ "SigType" SG_ 2364577278 InCoolantTemp 1;
BA_ "SPN" SG_ 2364577278 InCoolantTemp 8088;
BA_ "SigType" SG_ 2364577278 IgntV 1;
BA_ "SPN" SG_ 2364577278 IgntV 8087;
BA_ "SigType" SG_ 2364577278 BusV 1;
BA_ "SPN" SG_ 2364577278 BusV 8086;
BA_ "SigType" SG_ 2364577022 MaxCellStOfCharge 1;
BA_ "SPN" SG_ 2364577022 MaxCellStOfCharge 8085;
BA_ "SigType" SG_ 2364577022 MinCellStOfCharge 1;
BA_ "SPN" SG_ 2364577022 MinCellStOfCharge 8084;
BA_ "SigType" SG_ 2364577022 ChargeCurLmt 1;
BA_ "GenSigStartValue" SG_ 2364577022 ChargeCurLmt 32000;
BA_ "SPN" SG_ 2364577022 ChargeCurLmt 8083;
BA_ "SigType" SG_ 2364577022 DisCurLmt 1;
BA_ "SPN" SG_ 2364577022 DisCurLmt 8082;
BA_ "SigType" SG_ 2364576766 CellBalancingCount 1;
BA_ "SPN" SG_ 2364576766 CellBalancingCount 8081;
BA_ "SigType" SG_ 2364576766 ChargeCapacity 1;
BA_ "SPN" SG_ 2364576766 ChargeCapacity 8080;
BA_ "SigType" SG_ 2364576766 DisCapacity 1;
BA_ "SPN" SG_ 2364576766 DisCapacity 8079;
BA_ "SigType" SG_ 2364576510 CellTempDiffStatus 4;
BA_ "SPN" SG_ 2364576510 CellTempDiffStatus 8078;
BA_ "SigType" SG_ 2364576510 AvgCellTemp 1;
BA_ "SPN" SG_ 2364576510 AvgCellTemp 8077;
BA_ "SigType" SG_ 2364576510 LowestCellTemp 1;
BA_ "SPN" SG_ 2364576510 LowestCellTemp 8076;
BA_ "SigType" SG_ 2364576510 HighestCellTemp 1;
BA_ "SPN" SG_ 2364576510 HighestCellTemp 8075;
BA_ "SPN" SG_ 2364576254 CellVDiffStatus 5924;
BA_ "SigType" SG_ 2364576254 LowestCellV 1;
BA_ "SPN" SG_ 2364576254 LowestCellV 5923;
BA_ "SigType" SG_ 2364576254 HighestCellV 1;
BA_ "SPN" SG_ 2364576254 HighestCellV 5922;
BA_ "SigType" SG_ 2364576254 FastUpdateStOfCharge 1;
BA_ "SPN" SG_ 2364576254 FastUpdateStOfCharge 5921;
BA_ "SigType" SG_ 2364575998 Cur 1;
BA_ "SPN" SG_ 2364575998 Cur 5920;
BA_ "SigType" SG_ 2364575998 Lvl 1;
BA_ "SPN" SG_ 2364575998 Lvl 5919;
BA_ "SigType" SG_ 2364575998 AvailableChargePwr 1;
BA_ "SPN" SG_ 2364575998 AvailableChargePwr 5918;
BA_ "SigType" SG_ 2364575998 AvailableDisPwr 1;
BA_ "SPN" SG_ 2364575998 AvailableDisPwr 5917;
BA_ "SigType" SG_ 2364552958 ChargePLDueToPwrModuleETemp 4;
BA_ "SPN" SG_ 2364552958 ChargePLDueToPwrModuleETemp 22823;
BA_ "SigType" SG_ 2364552958 DisPLDueToPwrModuleETemp 4;
BA_ "SPN" SG_ 2364552958 DisPLDueToPwrModuleETemp 22824;
BA_ "SigType" SG_ 2364552958 ChargePLDueToAnUndefinedCause 4;
BA_ "SPN" SG_ 2364552958 ChargePLDueToAnUndefinedCause 8114;
BA_ "SigType" SG_ 2364552958 ChargePLDueToBatCur 4;
BA_ "SPN" SG_ 2364552958 ChargePLDueToBatCur 8113;
BA_ "SigType" SG_ 2364552958 ChargePLDueToBatOrCellV 4;
BA_ "SPN" SG_ 2364552958 ChargePLDueToBatOrCellV 8112;
BA_ "SigType" SG_ 2364552958 ChargePLDueToBatDiagCondition 4;
BA_ "SPN" SG_ 2364552958 ChargePLDueToBatDiagCondition 8111;
BA_ "SigType" SG_ 2364552958 ChargePLDueToBatTemp 4;
BA_ "SPN" SG_ 2364552958 ChargePLDueToBatTemp 8110;
BA_ "SigType" SG_ 2364552958 ChargePLDueToStOfCharge 4;
BA_ "SPN" SG_ 2364552958 ChargePLDueToStOfCharge 8109;
BA_ "SigType" SG_ 2364552958 DisPLDueToAnUndefinedCause 4;
BA_ "SPN" SG_ 2364552958 DisPLDueToAnUndefinedCause 8108;
BA_ "SigType" SG_ 2364552958 DisPLDueToBatCur 4;
BA_ "SPN" SG_ 2364552958 DisPLDueToBatCur 8107;
BA_ "SigType" SG_ 2364552958 DisPLDueToBatOrCellV 4;
BA_ "SPN" SG_ 2364552958 DisPLDueToBatOrCellV 8106;
BA_ "SigType" SG_ 2364552958 DisPLDueToBatDiagCondition 4;
BA_ "SPN" SG_ 2364552958 DisPLDueToBatDiagCondition 8105;
BA_ "SigType" SG_ 2364552958 DisPLDueToBatTemp 4;
BA_ "SPN" SG_ 2364552958 DisPLDueToBatTemp 8104;
BA_ "SigType" SG_ 2364552958 DisPLDueToStOfCharge 4;
BA_ "SPN" SG_ 2364552958 DisPLDueToStOfCharge 8103;
BA_ "SigType" SG_ 2558459646 ReqEngSpdDecelerationRateLmt 1;
BA_ "SPN" SG_ 2558459646 ReqEngSpdDecelerationRateLmt 7761;
BA_ "SigType" SG_ 2558459646 ReqEngSpdAccelerationRateLmt 1;
BA_ "SPN" SG_ 2558459646 ReqEngSpdAccelerationRateLmt 7760;
VAL_ 2566642942 EnableStatusOfDoor30 3 "Not available" 2 "Error" 1 "Door enabled" 0 "Door disabled" ;
VAL_ 2566642942 OpenStatusOfDoor30 3 "Not available" 2 "Error" 1 "Door opened" 0 "Door closed" ;
VAL_ 2566642942 LockStatusOfDoor30 3 "Not available" 2 "Error" 1 "Locked" 0 "Unlocked" ;
VAL_ 2566642942 EnableStatusOfDoor29 3 "Not available" 2 "Error" 1 "Door enabled" 0 "Door disabled" ;
VAL_ 2566642942 OpenStatusOfDoor29 3 "Not available" 2 "Error" 1 "Door opened" 0 "Door closed" ;
VAL_ 2566642942 LockStatusOfDoor29 3 "Not available" 2 "Error" 1 "Locked" 0 "Unlocked" ;
VAL_ 2566642942 EnableStatusOfDoor28 3 "Not available" 2 "Error" 1 "Door enabled" 0 "Door disabled" ;
VAL_ 2566642942 OpenStatusOfDoor28 3 "Not available" 2 "Error" 1 "Door opened" 0 "Door closed" ;
VAL_ 2566642942 LockStatusOfDoor28 3 "Not available" 2 "Error" 1 "Locked" 0 "Unlocked" ;
VAL_ 2566642942 EnableStatusOfDoor27 3 "Not available" 2 "Error" 1 "Door enabled" 0 "Door disabled" ;
VAL_ 2566642942 OpenStatusOfDoor27 3 "Not available" 2 "Error" 1 "Door opened" 0 "Door closed" ;
VAL_ 2566642942 LockStatusOfDoor27 3 "Not available" 2 "Error" 1 "Locked" 0 "Unlocked" ;
VAL_ 2566642942 EnableStatusOfDoor26 3 "Not available" 2 "Error" 1 "Door enabled" 0 "Door disabled" ;
VAL_ 2566642942 OpenStatusOfDoor26 3 "Not available" 2 "Error" 1 "Door opened" 0 "Door closed" ;
VAL_ 2566642942 LockStatusOfDoor26 3 "Not available" 2 "Error" 1 "Locked" 0 "Unlocked" ;
VAL_ 2566642942 EnableStatusOfDoor25 3 "Not available" 2 "Error" 1 "Door enabled" 0 "Door disabled" ;
VAL_ 2566642942 OpenStatusOfDoor25 3 "Not available" 2 "Error" 1 "Door opened" 0 "Door closed" ;
VAL_ 2566642942 LockStatusOfDoor25 3 "Not available" 2 "Error" 1 "Locked" 0 "Unlocked" ;
VAL_ 2566642942 EnableStatusOfDoor24 3 "Not available" 2 "Error" 1 "Door enabled" 0 "Door disabled" ;
VAL_ 2566642942 OpenStatusOfDoor24 3 "Not available" 2 "Error" 1 "Door opened" 0 "Door closed" ;
VAL_ 2566642942 LockStatusOfDoor24 3 "Not available" 2 "Error" 1 "Locked" 0 "Unlocked" ;
VAL_ 2566642942 EnableStatusOfDoor23 3 "Not available" 2 "Error" 1 "Door enabled" 0 "Door disabled" ;
VAL_ 2566642942 OpenStatusOfDoor23 3 "Not available" 2 "Error" 1 "Door opened" 0 "Door closed" ;
VAL_ 2566642942 LockStatusOfDoor23 3 "Not available" 2 "Error" 1 "Locked" 0 "Unlocked" ;
VAL_ 2566642942 EnableStatusOfDoor22 3 "Not available" 2 "Error" 1 "Door enabled" 0 "Door disabled" ;
VAL_ 2566642942 OpenStatusOfDoor22 3 "Not available" 2 "Error" 1 "Door opened" 0 "Door closed" ;
VAL_ 2566642942 LockStatusOfDoor22 3 "Not available" 2 "Error" 1 "Locked" 0 "Unlocked" ;
VAL_ 2566642942 EnableStatusOfDoor21 3 "Not available" 2 "Error" 1 "Door enabled" 0 "Door disabled" ;
VAL_ 2566642942 OpenStatusOfDoor21 3 "Not available" 2 "Error" 1 "Door opened" 0 "Door closed" ;
VAL_ 2566642942 LockStatusOfDoor21 3 "Not available" 2 "Error" 1 "Locked" 0 "Unlocked" ;
VAL_ 2633750526 PGNModifiedStatus 3 "Not Available" 2 "PG's transmit status could be modified as requested" 1 "PG's transmit status was not requested to be modified" 0 "PG's transmit status could not be modified" ;
VAL_ 2633750526 PGNPendingChangeStatus 3 "Not Available" 2 "No pending transmit change for the port identified in SPN 8599." 1 "Pending transmit change to enable for the port identified in SPN 8599." 0 "Pending transmit change to disable for the port identified in SPN 8599." ;
VAL_ 2633750526 PGNCurTransmitStatus 3 "Not Available" 2 "The PG transmit capability cannot be modified" 1 "PG is not currently configured for transmit on the port identified in SPN 8599." 0 "PG is currently configured for transmit on the port identified in SPN 8599." ;
VAL_ 2633750526 PortCmdStatus 7 "Not Available" 6 "SAE Reserved" 5 "SAE Reserved" 4 "SAE Reserved" 3 "SAE Reserved" 2 "No Configurable PGs exist for the port identified in SPN 8599." 1 "Negative Acknowledgment" 0 "Positive Acknowledgment" ;
VAL_ 2633750526 PortPendingChangesStatus 1 "Transmit changes are pending for one or more supported PGs on the port identified in SPN 8599." 0 "No pending changes to the transmit status for any supported PGs for the port identified in SPN 8599." ;
VAL_ 2633750526 Port 15 "SAE Reserved" 14 "SAE Reserved" 13 "SAE Reserved" 12 "SAE Reserved" 11 "SAE Reserved" 10 "Port 10" 9 "Port 9" 8 "Port 8" 7 "Port 7" 6 "Port 6" 5 "Port 5" 4 "Port 4" 3 "Port 3" 2 "Port 2" 1 "Port 1" 0 "Current port" ;
VAL_ 2431719166 FluidEndVlvLeak 3 "Not Available" 2 "Error" 1 "Leak Detected" 0 "No Leak Detected" ;
VAL_ 2431719166 CavitationStatus 7 "Not Available" 6 "Error" 5 "Reserved" 4 "Reserved" 3 "High" 2 "Medium" 1 "Low" 0 "No Cavitation" ;
VAL_ 2364609534 PLDueToUndefinedReason 3 "Not Available" 2 "Error" 1 "Power limited for this reason" 0 "No power limit for this reason" ;
VAL_ 2364609534 PLDueToSLIBatTermTemp 3 "Not Available" 2 "Error" 1 "Power limited for this reason" 0 "No power limit for this reason" ;
VAL_ 2364609534 PLDueToSLIBatTermCur 3 "Not Available" 2 "Error" 1 "Power limited for this reason" 0 "No power limit for this reason" ;
VAL_ 2364609534 PLDueToSLIBatTermV 3 "Not Available" 2 "Error" 1 "Power limited for this reason" 0 "No power limit for this reason" ;
VAL_ 2364609534 PLDueToPwrETemp 3 "Not Available" 2 "Error" 1 "Power limited for this reason" 0 "No power limit for this reason" ;
VAL_ 2364609534 PLDueToElectronicFilterTemp 3 "Not available" 2 "Error" 1 "Power limited for this reason" 0 "No power limit for this reason" ;
VAL_ 2364609534 PLDueToCtrlTemp 3 "Not Available" 2 "Error" 1 "Power limited for this reason" 0 "No power limit for this reason" ;
VAL_ 2364609534 PLDueToLowSideVMax 3 "Not Available" 2 "Error" 1 "Power limited for this reason" 0 "No power limit for this reason" ;
VAL_ 2364609534 PLDueToLowSideVMin 3 "Not Available" 2 "Error" 1 "Power limited for this reason" 0 "No power limit for this reason" ;
VAL_ 2364609534 PLDueToHiSideVMax 3 "Not Available" 2 "Error" 1 "Power limited for this reason" 0 "No power limit for this reason" ;
VAL_ 2364609534 PLDueToHiSideVMin 3 "Not Available" 2 "Error" 1 "Power limited for this reason" 0 "No power limit for this reason" ;
VAL_ 2364609534 PLDueToLowSideCur 3 "Not Available" 2 "Error" 1 "Power limited for this reason" 0 "No power limit for this reason" ;
VAL_ 2364609534 PLDueToHiSideCur 3 "Not Available" 2 "Error" 1 "Power limited for this reason" 0 "No power limit for this reason" ;
VAL_ 2364609534 LoadshedReq 3 "Don't Care/Take No Action" 2 "Loadshed Requested,  Shutdown Imminent" 1 "Loadshed Requested" 0 "No Loadshed Requested" ;
VAL_ 2364609534 HVILStatus 3 "Not Available" 2 "Error" 1 "HVIL Open" 0 "HVIL Closed" ;
VAL_ 2364609534 OperationalStatus 15 "Not Available" 14 "Error" 13 "Manufacturer assignable state" 12 "Reserved" 11 "Reserved" 10 "Reserved" 9 "Reserved" 8 "Reserved" 7 "Reserved" 6 "Disabled due to malfunction or protection" 5 "Normal power down in process" 4 "Operational, Boost mode" 3 "Operational, Buck mode" 2 "Operational, Standby" 1 "Initialization in process" 0 "Disabled" ;
VAL_ 2364609278 OperationalCmd 15 "Don't care/ Take No Action" 13 "Reserved" 12 "Reserved" 11 "Reserved" 10 "Reserved" 9 "Reserved" 8 "Reserved" 7 "Reserved" 6 "Reserved" 5 "Reserved" 4 "Power down DC/DC Converter" 3 "Operate in boost mode" 2 "Operate in buck mode" 1 "Operate in standby mode" 0 "Disable" ;
VAL_ 2297499902 BrkPedalSw2 3 "Not Available" 2 "Error" 1 "Brake pedal depressed" 0 "Brake pedal released" ;
VAL_ 2364608510 CoolantFlow 3 "Not Available" 2 "Error" 1 "Engine Coolant is Flowing" 0 "No Engine Coolant Flow" ;
VAL_ 2364608510 PwtnProtState 3 "Not Available" 2 "Reserved for SAE assignment" 1 "Powertrain Protection is disabled" 0 "Powertrain Protection is enabled" ;
VAL_ 2364608510 AFTThermalMnmgtElevatedIdleSt 3 "Not Available" 2 "Reserved for SAE assignment" 1 "Idle Elevation Active" 0 "No Idle Elevation Active" ;
VAL_ 2364607486 Data9EmbeddedIntegritySupport 3 "CRC and Counter are not supported by the sender" 2 "Reserved" 1 "Protection is supported using J1939-76 SHM" 0 "Embedded CRC and Counter are supported by the sender" ;
VAL_ 2364607486 ThermalEventDetected 3 "Not available" 2 "Error" 1 "Thermal Event Detected" 0 "No Thermal Event Detected" ;
VAL_ 2364606974 TMSCoolantLvl 3 "Not Available" 2 "Error" 1 "Coolant Level is sufficient" 0 "Coolant Level is not sufficient" ;
VAL_ 2364606974 TMSHVILStatus 3 "Not Available" 2 "Error" 1 "HVIL Open" 0 "HVIL Closed" ;
VAL_ 2364606974 TMSMode 15 "Not Available" 14 "Faulted" 13 "Reserved" 12 "Reserved" 11 "Reserved" 10 "Reserved" 9 "Reserved" 8 "Reserved" 7 "Reserved" 6 "Reserved" 5 "Maintaining" 4 "Drying" 3 "Heating" 2 "Cooling" 1 "Circulating" 0 "Off" ;
VAL_ 2364606974 TMSHtrStatus 3 "Not Available" 2 "Error" 1 "Heater On" 0 "Heater Off" ;
VAL_ 2364606718 Module32OperationalStatus 3 "Not Available" 2 "Error" 1 "Operational" 0 "Not Operational" ;
VAL_ 2364606718 Module31OperationalStatus 3 "Not Available" 2 "Error" 1 "Operational" 0 "Not Operational" ;
VAL_ 2364606718 Module30OperationalStatus 3 "Not Available" 2 "Error" 1 "Operational" 0 "Not Operational" ;
VAL_ 2364606718 Module29OperationalStatus 3 "Not Available" 2 "Error" 1 "Operational" 0 "Not Operational" ;
VAL_ 2364606718 Module28OperationalStatus 3 "Not Available" 2 "Error" 1 "Operational" 0 "Not Operational" ;
VAL_ 2364606718 Module27OperationalStatus 3 "Not Available" 2 "Error" 1 "Operational" 0 "Not Operational" ;
VAL_ 2364606718 Module26OperationalStatus 3 "Not Available" 2 "Error" 1 "Operational" 0 "Not Operational" ;
VAL_ 2364606718 Module25OperationalStatus 3 "Not Available" 2 "Error" 1 "Operational" 0 "Not Operational" ;
VAL_ 2364606718 Module24OperationalStatus 3 "Not Available" 2 "Error" 1 "Operational" 0 "Not Operational" ;
VAL_ 2364606718 Module23OperationalStatus 3 "Not Available" 2 "Error" 1 "Operational" 0 "Not Operational" ;
VAL_ 2364606718 Module22OperationalStatus 3 "Not Available" 2 "Error" 1 "Operational" 0 "Not Operational" ;
VAL_ 2364606718 Module21OperationalStatus 3 "Not Available" 2 "Error" 1 "Operational" 0 "Not Operational" ;
VAL_ 2364606718 Module20OperationalStatus 3 "Not Available" 2 "Error" 1 "Operational" 0 "Not Operational" ;
VAL_ 2364606718 Module19OperationalStatus 3 "Not Available" 2 "Error" 1 "Operational" 0 "Not Operational" ;
VAL_ 2364606718 Module18OperationalStatus 3 "Not Available" 2 "Error" 1 "Operational" 0 "Not Operational" ;
VAL_ 2364606718 Module17OperationalStatus 3 "Not Available" 2 "Error" 1 "Operational" 0 "Not Operational" ;
VAL_ 2364606718 Module16OperationalStatus 3 "Not Available" 2 "Error" 1 "Operational" 0 "Not Operational" ;
VAL_ 2364606718 Module15OperationalStatus 3 "Not Available" 2 "Error" 1 "Operational" 0 "Not Operational" ;
VAL_ 2364606718 Module14OperationalStatus 3 "Not Available" 2 "Error" 1 "Operational" 0 "Not Operational" ;
VAL_ 2364606718 Module13OperationalStatus 3 "Not Available" 2 "Error" 1 "Operational" 0 "Not Operational" ;
VAL_ 2364606718 Module12OperationalStatus 3 "Not Available" 2 "Error" 1 "Operational" 0 "Not Operational" ;
VAL_ 2364606718 Module11OperationalStatus 3 "Not Available" 2 "Error" 1 "Operational" 0 "Not Operational" ;
VAL_ 2364606718 Module10OperationalStatus 3 "Not Available" 2 "Error" 1 "Operational" 0 "Not Operational" ;
VAL_ 2364606718 Module9OperationalStatus 3 "Not Available" 2 "Error" 1 "Operational" 0 "Not Operational" ;
VAL_ 2364606718 Module8OperationalStatus 3 "Not Available" 2 "Error" 1 "Operational" 0 "Not Operational" ;
VAL_ 2364606718 Module7OperationalStatus 3 "Not Available" 2 "Error" 1 "Operational" 0 "Not Operational" ;
VAL_ 2364606718 Module6OperationalStatus 3 "Not Available" 2 "Error" 1 "Operational" 0 "Not Operational" ;
VAL_ 2364606718 Module5OperationalStatus 3 "Not Available" 2 "Error" 1 "Operational" 0 "Not Operational" ;
VAL_ 2364606718 Module4OperationalStatus 3 "Not Available" 2 "Error" 1 "Operational" 0 "Not Operational" ;
VAL_ 2364606718 Module3OperationalStatus 3 "Not Available" 2 "Error" 1 "Operational" 0 "Not Operational" ;
VAL_ 2364606718 Module2OperationalStatus 3 "Not Available" 2 "Error" 1 "Operational" 0 "Not Operational" ;
VAL_ 2364606718 Module1OperationalStatus 3 "Not Available" 2 "Error" 1 "Operational" 0 "Not Operational" ;
VAL_ 2364604926 PitchLmtSt 7 "Not available" 6 "Non recoverable fault" 5 "Reserved" 4 "Reserved" 3 "Limited Low" 2 "Limited High" 1 "Operator limited/controlled" 0 "Not limited" ;
VAL_ 2364604926 LmtSt 7 "Not available" 6 "Non recoverable fault" 5 "Reserved" 4 "Reserved" 3 "Limited Low" 2 "Limited High" 1 "Operator limited/controlled" 0 "Not limited" ;
VAL_ 2364604414 PitchLmtSt 7 "Not available" 6 "Non recoverable fault" 5 "Reserved" 4 "Reserved" 3 "Limited Low" 2 "Limited High" 1 "Operator limited/controlled" 0 "Not limited" ;
VAL_ 2364604414 LmtSt 7 "Not available" 6 "Non recoverable fault" 5 "Reserved" 4 "Reserved" 3 "Limited Low" 2 "Limited High" 1 "Operator limited/controlled" 0 "Not limited" ;
VAL_ 2364603134 Mode20Ind 3 "Not available" 2 "Error" 1 "Transmission Mode 20 active" 0 "Transmission Mode 20 not active" ;
VAL_ 2364603134 Mode19Ind 3 "Not available" 2 "Error" 1 "Transmission Mode 19 active" 0 "Transmission Mode 19 not active" ;
VAL_ 2364603134 Mode18Ind 3 "Not available" 2 "Error" 1 "Transmission Mode 18 active" 0 "Transmission Mode 18 not active" ;
VAL_ 2364603134 Mode17Ind 3 "Not available" 2 "Error" 1 "Transmission Mode 17 active" 0 "Transmission Mode 17 not active" ;
VAL_ 2364603134 Mode16Ind 3 "Not available" 2 "Error" 1 "Transmission Mode 16 active" 0 "Transmission Mode 16 not active" ;
VAL_ 2364603134 Mode15Ind 3 "Not available" 2 "Error" 1 "Transmission Mode 15 active" 0 "Transmission Mode 15 not active" ;
VAL_ 2364603134 Mode14Ind 3 "Not available" 2 "Error" 1 "Transmission Mode 14 active" 0 "Transmission Mode 14 not active" ;
VAL_ 2364603134 Mode13Ind 3 "Not available" 2 "Error" 1 "Transmission Mode 13 active" 0 "Transmission Mode 13 not active" ;
VAL_ 2364603134 Mode12Ind 3 "Not available" 2 "Error" 1 "Transmission Mode 12 active" 0 "Transmission Mode 12 not active" ;
VAL_ 2364603134 Mode11Ind 3 "Not available" 2 "Error" 1 "Transmission Mode 11 active" 0 "Transmission Mode 11 not active" ;
VAL_ 2565923838 HVILStatus 3 "Not Available" 2 "Error" 1 "HVIL Open" 0 "HVIL Closed" ;
VAL_ 2565923838 LoadshedReq 3 "Don't Care/Take No Action" 2 "Loadshed Requested,  Shutdown Imminent" 1 "Loadshed Requested" 0 "No Loadshed Requested" ;
VAL_ 2565923838 StatusFeedback 7 "Not Available" 6 "Error" 5 "Reserved" 4 "Normal Power Down in Process" 3 "Output Faulted Off" 2 "Output Faulted On" 1 "Output Enabled" 0 "Output Disabled" ;
VAL_ 2565923582 EnableCmd 3 "Don't care/take no action" 2 "Power down DC/AC Accessory Inverter Controller" 1 "Enable DC/AC Accessory Inverter Output" 0 "Disable DC/AC Accessory Inverter Output" ;
VAL_ 2565923582 Device2Status 7 "Not Available" 6 "Error" 5 "Reserved for SAE Assignment" 4 "Reserved for SAE Assignment" 3 "Faulted Off" 2 "Faulted On" 1 "Off" 0 "On" ;
VAL_ 2565923582 Device1Status 7 "Not Available" 6 "Error" 5 "Reserved for SAE Assignment" 4 "Reserved for SAE Assignment" 3 "Faulted Off" 2 "Faulted On" 1 "Off" 0 "On" ;
VAL_ 2565922814 HVILStatus 3 "Not Available" 2 "Error" 1 "HVIL Open" 0 "HVIL Closed" ;
VAL_ 2565922814 LoadshedReq 3 "Don't Care/Take No Action" 2 "Loadshed Requested,  Shutdown Imminent" 1 "Loadshed Requested" 0 "No Loadshed Requested" ;
VAL_ 2565922814 StatusFeedback 7 "Not Available" 6 "Error" 5 "Reserved" 4 "Normal Power Down in Process" 3 "Output Faulted Off" 2 "Output Faulted On" 1 "Output Enabled" 0 "Output Disabled" ;
VAL_ 2565922558 EnableCmd 3 "Don't care/take no action" 2 "Power down DC/AC Accessory Inverter Controller" 1 "Enable DC/AC Accessory Inverter Output" 0 "Disable DC/AC Accessory Inverter Output" ;
VAL_ 2565922558 Device2Status 7 "Not Available" 6 "Error" 5 "Reserved for SAE Assignment" 4 "Reserved for SAE Assignment" 3 "Faulted Off" 2 "Faulted On" 1 "Off" 0 "On" ;
VAL_ 2565922558 Device1Status 7 "Not Available" 6 "Error" 5 "Reserved for SAE Assignment" 4 "Reserved for SAE Assignment" 3 "Faulted Off" 2 "Faulted On" 1 "Off" 0 "On" ;
VAL_ 2565921790 HVILStatus 3 "Not Available" 2 "Error" 1 "HVIL Open" 0 "HVIL Closed" ;
VAL_ 2565921790 LoadshedReq 3 "Don't Care/Take No Action" 2 "Loadshed Requested,  Shutdown Imminent" 1 "Loadshed Requested" 0 "No Loadshed Requested" ;
VAL_ 2565921790 StatusFeedback 7 "Not Available" 6 "Error" 5 "Reserved" 4 "Normal Power Down in Process" 3 "Output Faulted Off" 2 "Output Faulted On" 1 "Output Enabled" 0 "Output Disabled" ;
VAL_ 2565921534 EnableCmd 3 "Don't care/take no action" 2 "Power down DC/AC Accessory Inverter Controller" 1 "Enable DC/AC Accessory Inverter Output" 0 "Disable DC/AC Accessory Inverter Output" ;
VAL_ 2565921534 Device2Status 7 "Not Available" 6 "Error" 5 "Reserved for SAE Assignment" 4 "Reserved for SAE Assignment" 3 "Faulted Off" 2 "Faulted On" 1 "Off" 0 "On" ;
VAL_ 2565921534 Device1Status 7 "Not Available" 6 "Error" 5 "Reserved for SAE Assignment" 4 "Reserved for SAE Assignment" 3 "Faulted Off" 2 "Faulted On" 1 "Off" 0 "On" ;
VAL_ 2565920766 HVILStatus 3 "Not Available" 2 "Error" 1 "HVIL Open" 0 "HVIL Closed" ;
VAL_ 2565920766 LoadshedReq 3 "Don't Care/Take No Action" 2 "Loadshed Requested,  Shutdown Imminent" 1 "Loadshed Requested" 0 "No Loadshed Requested" ;
VAL_ 2565920766 StatusFeedback 7 "Not Available" 6 "Error" 5 "Reserved" 4 "Normal Power Down in Process" 3 "Output Faulted Off" 2 "Output Faulted On" 1 "Output Enabled" 0 "Output Disabled" ;
VAL_ 2565920510 EnableCmd 3 "Don't care/take no action" 2 "Power down DC/AC Accessory Inverter Controller" 1 "Enable DC/AC Accessory Inverter Output" 0 "Disable DC/AC Accessory Inverter Output" ;
VAL_ 2565920510 Device2Status 7 "Not Available" 6 "Error" 5 "Reserved for SAE Assignment" 4 "Reserved for SAE Assignment" 3 "Faulted Off" 2 "Faulted On" 1 "Off" 0 "On" ;
VAL_ 2565920510 Device1Status 7 "Not Available" 6 "Error" 5 "Reserved for SAE Assignment" 4 "Reserved for SAE Assignment" 3 "Faulted Off" 2 "Faulted On" 1 "Off" 0 "On" ;
VAL_ 2364577534 OperationalStatus 15 "Not Available" 14 "Error" 13 "Reserved" 12 "Reserved" 11 "Reserved" 10 "Reserved" 9 "Reserved" 8 "Reserved" 7 "Reserved" 6 "Disabled by internal decision of HVES controller" 5 "Disabled by external command" 4 "Emergency Power-Down In Process" 3 "Normal Power-Down in Process" 2 "Operational." 1 "Initialization Complete" 0 "Initialization in process" ;
VAL_ 2364577534 HVBusConnectionStatus 15 "Not Available" 14 "Error" 13 "Reserved" 12 "Reserved" 11 "Reserved" 10 "Reserved" 9 "Reserved" 8 "Reserved" 7 "Reserved" 6 "Reserved" 5 "Reserved" 4 "Disconnected,  Precharge Failed" 3 "Disconnection in Process" 2 "Connection in Process" 1 "Connected" 0 "Disconnected,  One or more contactors are open" ;
VAL_ 2364577534 InternalChargerStatus 3 "Not Available" 2 "Error" 1 "Charging on" 0 "Charging off" ;
VAL_ 2364577534 CellBalancingActive 3 "Not Available" 2 "Error" 1 "Cell balancing is active" 0 "Cell balancing is not active" ;
VAL_ 2364577534 CellBalanceStatus 3 "Not Available" 2 "Error" 1 "Cells are unbalanced" 0 "Cells are balanced" ;
VAL_ 2364577534 StOfChargeStatus 15 "Not  Available" 14 "Error" 13 "Reserved" 12 "Reserved" 11 "Reserved" 10 "Reserved" 9 "Reserved" 8 "Reserved" 7 "Reserved" 6 "SOC is above its recommended upper limit" 5 "SOC is at its recommended upper limit" 4 "SOC is approaching its recommended upper limit" 3 "SOC is below its recommended lower limit" 2 "SOC is at its recommended lower limit" 1 "SOC is approaching its recommended lower limit" 0 "SOC level is acceptable." ;
VAL_ 2364577534 InertiaSwStatus 3 "Not Available" 2 "Error" 1 "Impact sensed" 0 "No impact sensed" ;
VAL_ 2364577534 HVILStatus 3 "Not Available" 2 "Error" 1 "HVIL Open" 0 "HVIL Closed" ;
VAL_ 2364577534 HVBusPassiveIsolTestStatus 15 "Not available" 14 "Error" 13 "Reserved" 12 "Reserved" 11 "Reserved" 10 "Reserved" 9 "Reserved" 8 "Reserved" 7 "Reserved" 6 "Test is inhibited" 5 "Test complete,  isolation fault" 4 "Test complete,  isolation marginal" 3 "Test complete,  isolation acceptable" 2 "Test in process" 1 "Test requested but not yet in process" 0 "No test requested / No test in process" ;
VAL_ 2364577534 HVBusActiveIsolTestStatus 15 "Not available" 14 "Error" 13 "Reserved" 12 "Reserved" 11 "Reserved" 10 "Reserved" 9 "Reserved" 8 "Reserved" 7 "Reserved" 6 "Test is inhibited" 5 "Test complete,  isolation fault" 4 "Test complete,  isolation marginal" 3 "Test complete,  isolation acceptable" 2 "Test in process" 1 "Test requested but not yet in process" 0 "No test requested / No test in process" ;
VAL_ 2364577534 CenterOfPackContactorSt 3 "Not Available" 2 "Error" 1 "Contactor Closed" 0 "Contactor Open" ;
VAL_ 2364577534 HVBusPreChargeRelaySt 3 "Not Available" 2 "Error" 1 "Relay Closed" 0 "Relay Open" ;
VAL_ 2364577534 HVBusDisconnectForewarning 15 "Not Available" 14 "Error" 13 "Disconnect imminent" 12 "Reserved" 11 "Reserved" 10 "Reserved" 9 "Reserved" 8 "Reserved" 7 "Disconnect imminent due to battery pack current approaching maximum acceptable level" 6 "Disconnect imminent due to cell voltage approaching maximum acceptable level" 5 "Disconnect imminent due to cell voltage approaching minimum acceptable level" 4 "Disconnect imminent due to module voltage approaching maximum acceptable level" 3 "Disconnect imminent due to module voltage approaching minimum acceptable level" 2 "Disconnect imminent due to battery pack voltage approaching maximum acceptable level" 1 "Disconnect imminent due to battery pack voltage approaching minimum acceptable level" 0 "Disconnect not pending" ;
VAL_ 2364577534 HVBusContactorSt8092 3 "Not Available" 2 "Error" 1 "Contactor Closed" 0 "Contactor Open" ;
VAL_ 2364577534 HVBusContactorSt 3 "Not Available" 2 "Error" 1 "Contactor Closed" 0 "Contactor Open" ;
VAL_ 2364576510 CellTempDiffStatus 3 "Not Available" 2 "Error" 1 "Cell-to-cell temperature differential exceeds acceptable limits" 0 "Cell-to-cell temperature differential is within acceptable limits" ;
VAL_ 2364576254 CellVDiffStatus 15 "Not Available" 14 "Error" 13 "Reserved" 12 "Reserved" 11 "Reserved" 10 "Reserved" 9 "Reserved" 8 "Reserved" 7 "Reserved" 6 "Reserved" 5 "Reserved" 4 "Exceeds limits and it is not known whether balancing can restore performance" 3 "Exceeds limits and external maintenance balancing cannot restore performance" 2 "Exceeds limits and external maintenance balancing is required" 1 "Exceeds limits and can be corrected via auto-balancing" 0 "Is within acceptable limits" ;
VAL_ 2364552958 ChargePLDueToPwrModuleETemp 3 "Not Available" 2 "Error" 1 "Power limited for this reason" 0 "No power limit for this reason" ;
VAL_ 2364552958 DisPLDueToPwrModuleETemp 3 "Not Available" 2 "Error" 1 "Power limited for this reason" 0 "No power limit for this reason" ;
VAL_ 2364552958 ChargePLDueToAnUndefinedCause 0 "No power limit for this reason" 3 "Not Available" 2 "Error" 1 "Power limited for this reason" ;
VAL_ 2364552958 ChargePLDueToBatCur 3 "Not Available" 2 "Error" 1 "Power limited for this reason" 0 "No power limit for this reason" ;
VAL_ 2364552958 ChargePLDueToBatOrCellV 3 "Not Available" 2 "Error" 1 "Power limited for this reason" 0 "No power limit for this reason" ;
VAL_ 2364552958 ChargePLDueToBatDiagCondition 3 "Not Available" 2 "Error" 1 "Power limited for this reason" 0 "No power limit for this reason" ;
VAL_ 2364552958 ChargePLDueToBatTemp 3 "Not Available" 2 "Error" 1 "Power limited for this reason" 0 "No power limit for this reason" ;
VAL_ 2364552958 ChargePLDueToStOfCharge 3 "Not Available" 2 "Error" 1 "Power limited for this reason" 0 "No power limit for this reason" ;
VAL_ 2364552958 DisPLDueToAnUndefinedCause 3 "Not Available" 2 "Error" 1 "Power limited for this reason" 0 "No power limit for this reason" ;
VAL_ 2364552958 DisPLDueToBatCur 3 "Not Available" 2 "Error" 1 "Power limited for this reason" 0 "No power limit for this reason" ;
VAL_ 2364552958 DisPLDueToBatOrCellV 3 "Not Available" 2 "Error" 1 "Power limited for this reason" 0 "No power limit for this reason" ;
VAL_ 2364552958 DisPLDueToBatDiagCondition 3 "Not Available" 2 "Error" 1 "Power limited for this reason" 0 "No power limit for this reason" ;
VAL_ 2364552958 DisPLDueToBatTemp 3 "Not Available" 2 "Error" 1 "Power limited for this reason" 0 "No power limit for this reason" ;
VAL_ 2364552958 DisPLDueToStOfCharge 3 "Not Available" 2 "Error" 1 "Power limited for this reason" 0 "No power limit for this reason" ;
